VERSION "hnnbnnnynnnnnnnnnnnnnnnnnnnnnnnnnnnnnnnnnn/4/%%%/4/'%**4nnn///"

NS_ :

BS_:

BU_: BAP_Tester Fahrerdisplay_Kombi HUD ICAS1_X_Gateway ICAS3_Gateway ICC_IO_Node Kombi SmartLight_01 ZR_MIB_TOP_ab_Gen3

BO_ 2463978804 SmaLi_Control_Frame_01: 32 ICAS1_X_Gateway
	SG_ SmaLi_brightness : 72|8@1+ (1,0) [0|255] "None"  SmartLight_01
	SG_ SmaLi_Checksum : 96|16@1+ (1,0) [0|65535] "None"  SmartLight_01
	SG_ SmaLi_Cnt_05 : 8|16@1+ (1,0) [0|65535] "None"  SmartLight_01
	SG_ SmaLi_CtrlCmd_01 : 0|8@1+ (1,0) [0|255] ""  SmartLight_01
	SG_ SmaLi_Loops : 64|8@1+ (1,0) [0|255] "None"  SmartLight_01
	SG_ SmaLi_MovieBundleVersion : 80|16@1+ (1,0) [0|65535] "None"  SmartLight_01
	SG_ SmaLi_MovieID : 32|32@1+ (1,0) [0|4294967295] "None"  SmartLight_01
	SG_ SmaLi_SlotID_05 : 24|8@1+ (1,0) [0|255] "None"  SmartLight_01

BO_ 2463978800 SmaLi_Daten_Frame_01: 64 ICAS1_X_Gateway
	SG_ SmaLi_Cnt_01 : 8|16@1+ (1,0) [0|65535] "None"  SmartLight_01
	SG_ SmaLi_ColorValue_01 : 48|32@1+ (1,0) [0|4294967295] "None"  SmartLight_01
	SG_ SmaLi_ColorValue_02 : 80|32@1+ (1,0) [0|4294967295] "None"  SmartLight_01
	SG_ SmaLi_ColorValue_03 : 112|32@1+ (1,0) [0|4294967295] "None"  SmartLight_01
	SG_ SmaLi_ColorValue_04 : 144|32@1+ (1,0) [0|4294967295] "None"  SmartLight_01
	SG_ SmaLi_ColorValue_05 : 176|32@1+ (1,0) [0|4294967295] "None"  SmartLight_01
	SG_ SmaLi_ColorValue_06 : 208|32@1+ (1,0) [0|4294967295] "None"  SmartLight_01
	SG_ SmaLi_ColorValue_07 : 240|32@1+ (1,0) [0|4294967295] "None"  SmartLight_01
	SG_ SmaLi_ColorValue_08 : 272|32@1+ (1,0) [0|4294967295] "None"  SmartLight_01
	SG_ SmaLi_ColorValue_09 : 304|32@1+ (1,0) [0|4294967295] "None"  SmartLight_01
	SG_ SmaLi_ColorValue_10 : 336|32@1+ (1,0) [0|4294967295] "None"  SmartLight_01
	SG_ SmaLi_ColorValue_11 : 368|32@1+ (1,0) [0|4294967295] "None"  SmartLight_01
	SG_ SmaLi_ColorValue_12 : 400|32@1+ (1,0) [0|4294967295] "None"  SmartLight_01
	SG_ SmaLi_ColorValue_13 : 432|32@1+ (1,0) [0|4294967295] "None"  SmartLight_01
	SG_ SmaLi_ColorValue_14 : 464|32@1+ (1,0) [0|4294967295] "None"  SmartLight_01
	SG_ SmaLi_FrameCmd_01 : 0|8@1+ (1,0) [0|255] ""  SmartLight_01
	SG_ SmaLi_length : 40|8@1+ (1,0) [0|255] "None"  SmartLight_01
	SG_ SmaLi_SlotID_01 : 24|8@1+ (1,0) [0|255] "None"  SmartLight_01
	SG_ SmaLi_StartIndex : 32|8@1+ (1,0) [0|255] "None"  SmartLight_01

BO_ 2463978801 SmaLi_Daten_Frame_02: 64 ICAS1_X_Gateway
	SG_ SmaLi_Cnt_02 : 8|16@1+ (1,0) [0|65535] "None"  SmartLight_01
	SG_ SmaLi_ColorValue_15 : 32|32@1+ (1,0) [0|4294967295] "None"  SmartLight_01
	SG_ SmaLi_ColorValue_16 : 64|32@1+ (1,0) [0|4294967295] "None"  SmartLight_01
	SG_ SmaLi_ColorValue_17 : 96|32@1+ (1,0) [0|4294967295] "None"  SmartLight_01
	SG_ SmaLi_ColorValue_18 : 128|32@1+ (1,0) [0|4294967295] "None"  SmartLight_01
	SG_ SmaLi_ColorValue_19 : 160|32@1+ (1,0) [0|4294967295] "None"  SmartLight_01
	SG_ SmaLi_ColorValue_20 : 192|32@1+ (1,0) [0|4294967295] "None"  SmartLight_01
	SG_ SmaLi_ColorValue_21 : 224|32@1+ (1,0) [0|4294967295] "None"  SmartLight_01
	SG_ SmaLi_ColorValue_22 : 256|32@1+ (1,0) [0|4294967295] "None"  SmartLight_01
	SG_ SmaLi_ColorValue_23 : 288|32@1+ (1,0) [0|4294967295] "None"  SmartLight_01
	SG_ SmaLi_ColorValue_24 : 320|32@1+ (1,0) [0|4294967295] "None"  SmartLight_01
	SG_ SmaLi_ColorValue_25 : 352|32@1+ (1,0) [0|4294967295] "None"  SmartLight_01
	SG_ SmaLi_ColorValue_26 : 384|32@1+ (1,0) [0|4294967295] "None"  SmartLight_01
	SG_ SmaLi_ColorValue_27 : 416|32@1+ (1,0) [0|4294967295] "None"  SmartLight_01
	SG_ SmaLi_ColorValue_28 : 448|32@1+ (1,0) [0|4294967295] "None"  SmartLight_01
	SG_ SmaLi_ColorValue_29 : 480|32@1+ (1,0) [0|4294967295] "None"  SmartLight_01
	SG_ SmaLi_FrameCmd_02 : 0|8@1+ (1,0) [0|255] ""  SmartLight_01
	SG_ SmaLi_SlotID_02 : 24|8@1+ (1,0) [0|255] "None"  SmartLight_01

BO_ 2463978802 SmaLi_Daten_Frame_03: 64 ICAS1_X_Gateway
	SG_ SmaLi_Cnt_03 : 8|16@1+ (1,0) [0|65535] "None"  SmartLight_01
	SG_ SmaLi_ColorValue_30 : 32|32@1+ (1,0) [0|4294967295] "None"  SmartLight_01
	SG_ SmaLi_ColorValue_31 : 64|32@1+ (1,0) [0|4294967295] "None"  SmartLight_01
	SG_ SmaLi_ColorValue_32 : 96|32@1+ (1,0) [0|4294967295] "None"  SmartLight_01
	SG_ SmaLi_ColorValue_33 : 128|32@1+ (1,0) [0|4294967295] "None"  SmartLight_01
	SG_ SmaLi_ColorValue_34 : 160|32@1+ (1,0) [0|4294967295] "None"  SmartLight_01
	SG_ SmaLi_ColorValue_35 : 192|32@1+ (1,0) [0|4294967295] "None"  SmartLight_01
	SG_ SmaLi_ColorValue_36 : 224|32@1+ (1,0) [0|4294967295] "None"  SmartLight_01
	SG_ SmaLi_ColorValue_37 : 256|32@1+ (1,0) [0|4294967295] "None"  SmartLight_01
	SG_ SmaLi_ColorValue_38 : 288|32@1+ (1,0) [0|4294967295] "None"  SmartLight_01
	SG_ SmaLi_ColorValue_39 : 320|32@1+ (1,0) [0|4294967295] "None"  SmartLight_01
	SG_ SmaLi_ColorValue_40 : 352|32@1+ (1,0) [0|4294967295] "None"  SmartLight_01
	SG_ SmaLi_ColorValue_41 : 384|32@1+ (1,0) [0|4294967295] "None"  SmartLight_01
	SG_ SmaLi_ColorValue_42 : 416|32@1+ (1,0) [0|4294967295] "None"  SmartLight_01
	SG_ SmaLi_ColorValue_43 : 448|32@1+ (1,0) [0|4294967295] "None"  SmartLight_01
	SG_ SmaLi_ColorValue_44 : 480|32@1+ (1,0) [0|4294967295] "None"  SmartLight_01
	SG_ SmaLi_FrameCmd_03 : 0|8@1+ (1,0) [0|255] ""  SmartLight_01
	SG_ SmaLi_SlotID_03 : 24|8@1+ (1,0) [0|255] "None"  SmartLight_01

BO_ 2463978803 SmaLi_Daten_Frame_04: 64 ICAS1_X_Gateway
	SG_ SmaLi_Cnt_04 : 8|16@1+ (1,0) [0|65535] "None"  SmartLight_01
	SG_ SmaLi_ColorValue_45 : 32|32@1+ (1,0) [0|4294967295] "None"  SmartLight_01
	SG_ SmaLi_ColorValue_46 : 64|32@1+ (1,0) [0|4294967295] "None"  SmartLight_01
	SG_ SmaLi_ColorValue_47 : 96|32@1+ (1,0) [0|4294967295] "None"  SmartLight_01
	SG_ SmaLi_ColorValue_48 : 128|32@1+ (1,0) [0|4294967295] "None"  SmartLight_01
	SG_ SmaLi_ColorValue_49 : 160|32@1+ (1,0) [0|4294967295] "None"  SmartLight_01
	SG_ SmaLi_ColorValue_50 : 192|32@1+ (1,0) [0|4294967295] "None"  SmartLight_01
	SG_ SmaLi_ColorValue_51 : 224|32@1+ (1,0) [0|4294967295] "None"  SmartLight_01
	SG_ SmaLi_ColorValue_52 : 256|32@1+ (1,0) [0|4294967295] "None"  SmartLight_01
	SG_ SmaLi_ColorValue_53 : 288|32@1+ (1,0) [0|4294967295] "None"  SmartLight_01
	SG_ SmaLi_ColorValue_54 : 320|32@1+ (1,0) [0|4294967295] "None"  SmartLight_01
	SG_ SmaLi_ColorValue_55 : 352|32@1+ (1,0) [0|4294967295] "None"  SmartLight_01
	SG_ SmaLi_ColorValue_56 : 384|32@1+ (1,0) [0|4294967295] "None"  SmartLight_01
	SG_ SmaLi_ColorValue_57 : 416|32@1+ (1,0) [0|4294967295] "None"  SmartLight_01
	SG_ SmaLi_ColorValue_58 : 448|32@1+ (1,0) [0|4294967295] "None"  SmartLight_01
	SG_ SmaLi_ColorValue_59 : 480|32@1+ (1,0) [0|4294967295] "None"  SmartLight_01
	SG_ SmaLi_FrameCmd_04 : 0|8@1+ (1,0) [0|255] ""  SmartLight_01
	SG_ SmaLi_SlotID_04 : 24|8@1+ (1,0) [0|255] "None"  SmartLight_01

BO_ 2463978806 SmaLi_Daten_Frame_05: 64 ICAS1_X_Gateway
	SG_ SmaLi_Cnt_07 : 8|16@1+ (1,0) [0|65535] "None"  SmartLight_01
	SG_ SmaLi_ColorValue_60 : 32|32@1+ (1,0) [0|4294967295] "None"  SmartLight_01
	SG_ SmaLi_ColorValue_61 : 64|32@1+ (1,0) [0|4294967295] "None"  SmartLight_01
	SG_ SmaLi_ColorValue_62 : 96|32@1+ (1,0) [0|4294967295] "None"  SmartLight_01
	SG_ SmaLi_ColorValue_63 : 128|32@1+ (1,0) [0|4294967295] "None"  SmartLight_01
	SG_ SmaLi_ColorValue_64 : 160|32@1+ (1,0) [0|4294967295] "None"  SmartLight_01
	SG_ SmaLi_ColorValue_65 : 192|32@1+ (1,0) [0|4294967295] "None"  SmartLight_01
	SG_ SmaLi_ColorValue_66 : 224|32@1+ (1,0) [0|4294967295] "None"  SmartLight_01
	SG_ SmaLi_ColorValue_67 : 256|32@1+ (1,0) [0|4294967295] "None"  SmartLight_01
	SG_ SmaLi_ColorValue_68 : 288|32@1+ (1,0) [0|4294967295] "None"  SmartLight_01
	SG_ SmaLi_ColorValue_69 : 320|32@1+ (1,0) [0|4294967295] "None"  SmartLight_01
	SG_ SmaLi_ColorValue_70 : 352|32@1+ (1,0) [0|4294967295] "None"  SmartLight_01
	SG_ SmaLi_ColorValue_71 : 384|32@1+ (1,0) [0|4294967295] "None"  SmartLight_01
	SG_ SmaLi_ColorValue_72 : 416|32@1+ (1,0) [0|4294967295] "None"  SmartLight_01
	SG_ SmaLi_ColorValue_73 : 448|32@1+ (1,0) [0|4294967295] "None"  SmartLight_01
	SG_ SmaLi_ColorValue_74 : 480|32@1+ (1,0) [0|4294967295] "None"  SmartLight_01
	SG_ SmaLi_FrameCmd_05 : 0|8@1+ (1,0) [0|255] ""  SmartLight_01
	SG_ SmaLi_SlotID_07 : 24|8@1+ (1,0) [0|255] "None"  SmartLight_01

BO_ 2463978805 SmaLi_Response_Frame_01: 32 SmartLight_01
	SG_ SmaLi_AppSwVersion : 160|32@1+ (1,0) [0|4294967295] ""  ICAS1_X_Gateway,ICAS3_Gateway
	SG_ SmaLi_availMemory : 88|16@1+ (1,0) [0|65535] "None"  ICAS1_X_Gateway,ICAS3_Gateway
	SG_ SmaLi_Cnt_06 : 8|16@1+ (1,0) [0|65535] "None"  ICAS1_X_Gateway,ICAS3_Gateway
	SG_ SmaLi_CtrlCmdRsp_01 : 0|8@1+ (1,0) [0|255] ""  ICAS1_X_Gateway,ICAS3_Gateway
	SG_ SmaLi_error_cause : 136|8@1+ (1,0) [0|255] ""  ICAS1_X_Gateway,ICAS3_Gateway
	SG_ SmaLi_InterfaceVersion : 32|16@1+ (1,0) [0|65535] "None"  ICAS1_X_Gateway,ICAS3_Gateway
	SG_ SmaLi_MovieIDRsp : 104|32@1+ (1,0) [0|4294967295] "None"  ICAS1_X_Gateway,ICAS3_Gateway
	SG_ SmaLi_numLEDs : 48|8@1+ (1,0) [0|255] "None"  ICAS1_X_Gateway,ICAS3_Gateway
	SG_ SmaLi_numOfSlots : 80|8@1+ (1,0) [0|255] "None"  ICAS1_X_Gateway,ICAS3_Gateway
	SG_ SmaLi_SavedMovieBundleVersion : 144|16@1+ (1,0) [0|65535] "None"  ICAS1_X_Gateway,ICAS3_Gateway
	SG_ SmaLi_SlotID_06 : 24|8@1+ (1,0) [0|255] "None"  ICAS1_X_Gateway,ICAS3_Gateway
	SG_ SmaLi_xPosCenter : 64|8@1+ (1,0) [0|255] "None"  ICAS1_X_Gateway,ICAS3_Gateway
	SG_ SmaLi_xPosPassengerLeft : 56|8@1+ (1,0) [0|255] "None"  ICAS1_X_Gateway,ICAS3_Gateway
	SG_ SmaLi_xPosPassengerRight : 72|8@1+ (1,0) [0|255] "None"  ICAS1_X_Gateway,ICAS3_Gateway

BO_ 980 SMLS_01: 8 ICAS1_X_Gateway
	SG_ BH_Blinker_Fehler : 46|1@1+ (1,0) [0|1] ""  Vector__XXX
	SG_ BH_Blinker_li : 12|1@1+ (1,0) [0|1] ""  ICAS3_Gateway
	SG_ BH_Blinker_re : 13|1@1+ (1,0) [0|1] ""  ICAS3_Gateway
	SG_ BH_Fernlicht : 15|1@1+ (1,0) [0|1] ""  Vector__XXX
	SG_ BH_Lichthupe : 14|1@1+ (1,0) [0|1] ""  Vector__XXX
	SG_ FAS_Taster : 27|1@1+ (1,0) [0|1] ""  Vector__XXX
	SG_ FAS_Taster_Fehler : 28|1@1+ (1,0) [0|1] ""  Vector__XXX
	SG_ LRH_aktiv : 40|1@1+ (1,0) [0|1] ""  Vector__XXX
	SG_ LRH_On_Off : 30|2@1+ (1,0) [0|3] ""  Kombi
	SG_ LSS_Tastencode : 32|8@1+ (1,0) [0|255] ""  Vector__XXX
	SG_ SMLS_01_BZ : 8|4@1+ (1,0) [0|15] ""  Vector__XXX
	SG_ SMLS_01_CRC : 0|8@1+ (1,0) [0|255] ""  Vector__XXX
	SG_ SMLS_Hupe : 29|1@1+ (1,0) [0|1] ""  Vector__XXX
	SG_ SMLS_P_verriegelt : 41|2@1+ (1,0) [0|3] ""  Vector__XXX
	SG_ SMLS_P_verriegelt_plausibel : 43|1@1+ (1,0) [0|1] ""  Vector__XXX
	SG_ SMLS_PTT : 47|1@1+ (1,0) [0|1] ""  Vector__XXX
	SG_ WH_Frontwaschen : 20|1@1+ (1,0) [0|1] ""  Vector__XXX
	SG_ WH_Heckintervall : 21|1@1+ (1,0) [0|1] ""  Vector__XXX
	SG_ WH_Heckwaschen : 22|1@1+ (1,0) [0|1] ""  Vector__XXX
	SG_ WH_Intervall : 17|1@1+ (1,0) [0|1] ""  Vector__XXX
	SG_ WH_Intervallstufen : 23|4@1+ (1,0) [0|15] ""  Vector__XXX
	SG_ WH_SRA : 44|1@1+ (1,0) [0|1] ""  Vector__XXX
	SG_ WH_Tipwischen : 16|1@1+ (1,0) [0|1] ""  Vector__XXX
	SG_ WH_Tipwischen_lang : 48|1@1+ (1,0) [0|1] ""  Vector__XXX
	SG_ WH_Wischer_Fehler : 45|1@1+ (1,0) [0|1] ""  Vector__XXX
	SG_ WH_WischerStufe1 : 18|1@1+ (1,0) [0|1] ""  Vector__XXX
	SG_ WH_WischerStufe2 : 19|1@1+ (1,0) [0|1] ""  Vector__XXX

BO_ 2536271618 SOK_BAP_ENI4_ASG_03_Sig: 8 Vector__XXX
	SG_ SOK_BAP_ENI4_ASG_03_Sig : 0|64@1+ (1,0) [0|18446744073709551616] ""  ICAS1_X_Gateway

BO_ 2536271634 SOK_BAP_ENI4_FSG_03_Sig: 8 ICAS1_X_Gateway
	SG_ SOK_BAP_ENI4_FSG_03_Sig : 0|64@1+ (1,0) [0|18446744073709551616] ""  Vector__XXX

BO_ 2464161907 SOK_FoD_Info_El_Req_Chal_04: 8 ICAS3_Gateway
	SG_ SOK_FoD_Info_El_Req_Challenge : 0|64@1+ (1,0) [0|18446744073709551616] "None"  ICAS1_X_Gateway

BO_ 2464301171 SOK_FoD_Info_El_Resp_Chal_04: 8 ICAS1_X_Gateway
	SG_ SOK_FoD_Info_El_Resp_Challenge : 0|64@1+ (1,0) [0|18446744073709551616] "None"  ICAS3_Gateway,ICC_IO_Node,ZR_MIB_TOP_ab_Gen3

BO_ 2589283756 SOK_NoAuthenticTime_01: 8 ICAS1_X_Gateway
	SG_ SOK_ungeschuetzte_Zeit : 8|56@1+ (1,0) [1|72057594037927936] "None"  ICAS3_Gateway,ICC_IO_Node,Kombi,ZR_MIB_TOP_ab_Gen3

BO_ 2464153715 SOK_Zeit_Info_El_Chal_01: 8 ICAS3_Gateway
	SG_ SOK_Zeit_Info_El_Challenge : 0|64@1+ (1,0) [0|18446744073709551616] "None"  ICAS1_X_Gateway

BO_ 2464284787 SOK_Zeit_Info_El_Resp_01: 16 ICAS1_X_Gateway
	SG_ SOK_Zeit_Info_El_Signatur : 64|64@1- (1,0) [0|18446744073709551616] ""  ICAS3_Gateway,ICC_IO_Node,ZR_MIB_TOP_ab_Gen3
	SG_ SOK_Zeit_Info_El_Zeit : 0|56@1+ (1,0) [0|72057594037927936] "None"  ICAS3_Gateway,ICC_IO_Node,ZR_MIB_TOP_ab_Gen3

BO_ 2464153620 SOK_Zeit_Kombi_Chal_01: 8 Kombi
	SG_ SOK_Zeit_Kombi_Challenge : 0|64@1+ (1,0) [0|18446744073709551616] "None"  ICAS1_X_Gateway

BO_ 2464284692 SOK_Zeit_Kombi_Signatur_Resp_01: 8 ICAS1_X_Gateway
	SG_ SOK_Zeit_Kombi_Signatur : 0|64@1+ (1,0) [0|18446744073709551616] ""  Kombi

BO_ 2464288788 SOK_Zeit_Kombi_Zeit_Resp_01: 8 ICAS1_X_Gateway
	SG_ SOK_Zeit_Kombi_Zeit : 0|56@1+ (1,0) [0|72057594037927936] "None"  Kombi

BO_ 2527679739 Standklima_01: 8 ICAS1_X_Gateway
	SG_ STK_Anf_AussenspiegelHZ : 34|1@1+ (1,0) [0|1] ""  Vector__XXX
	SG_ STK_Berechnungsphase : 30|2@1+ (1,0) [0|3] ""  Vector__XXX
	SG_ STK_Betriebsdauer : 5|7@1+ (1,0) [0|120] "Minut"  Vector__XXX
	SG_ STK_ErwVK_Anf : 25|1@1+ (1,0) [0|1] ""  Vector__XXX
	SG_ STK_ErwVK_Beifahrerzone : 35|1@1+ (1,0) [0|1] ""  Vector__XXX
	SG_ STK_ErwVK_Fahrerzone : 36|1@1+ (1,0) [0|1] ""  Vector__XXX
	SG_ STK_ErwVK_Heckzone2_links : 62|1@1+ (1,0) [0|1] ""  Vector__XXX
	SG_ STK_ErwVK_Heckzone2_rechts : 63|1@1+ (1,0) [0|1] ""  Vector__XXX
	SG_ STK_ErwVK_Heckzone_links : 37|1@1+ (1,0) [0|1] ""  Vector__XXX
	SG_ STK_ErwVK_Heckzone_rechts : 38|1@1+ (1,0) [0|1] ""  Vector__XXX
	SG_ STK_ErwVK_Modus : 26|4@1+ (1,0) [0|15] ""  Vector__XXX
	SG_ STK_ErwVK_Scheibenheizung : 39|1@1+ (1,0) [0|1] ""  Vector__XXX
	SG_ STK_FSH_Anf : 12|1@1+ (1,0) [0|1] ""  Vector__XXX
	SG_ STK_GesamtEnergiebedarf : 52|8@1+ (0.1,0) [0|15] "KiloWattHour"  Vector__XXX
	SG_ STK_HSH_Anf : 13|1@1+ (1,0) [0|1] ""  Vector__XXX
	SG_ STK_Klima_Temp : 14|5@1+ (0.5,15.5) [15.5|29.5] "DegreCelsi"  Vector__XXX
	SG_ STK_KurzVK_Anf : 19|1@1+ (1,0) [0|1] ""  Vector__XXX
	SG_ STK_MaxLeistung : 44|8@1+ (0.1,0) [0|15] "KiloWatt"  Vector__XXX
	SG_ STK_Standklima_Anf : 20|1@1+ (1,0) [0|1] ""  Vector__XXX
	SG_ STK_Standklima_Timer_Status : 21|1@1+ (1,0) [0|1] ""  Vector__XXX
	SG_ STK_Stecker_Status : 60|2@1+ (1,0) [0|3] ""  Vector__XXX
	SG_ STK_VK_Modus : 23|2@1+ (1,0) [0|3] ""  Vector__XXX
	SG_ STK_VK_STH_Einsatz : 40|3@1+ (1,0) [0|7] ""  Vector__XXX
	SG_ STK_VK_Timer_Status : 32|2@1+ (1,0) [0|3] ""  Vector__XXX
	SG_ STK_Voko_LED : 43|1@1+ (1,0) [0|1] ""  Fahrerdisplay_Kombi

BO_ 1413 Systeminfo_01: 8 ICAS1_X_Gateway
	SG_ GW_KD_Fehler : 13|1@1+ (1,0) [0|1] ""  ICAS3_Gateway,ICC_IO_Node,ZR_MIB_TOP_ab_Gen3
	SG_ SI_BUS_01 : 16|1@1+ (1,0) [0|1] ""  ICAS3_Gateway,ICC_IO_Node,Kombi,ZR_MIB_TOP_ab_Gen3
	SG_ SI_BUS_02 : 17|1@1+ (1,0) [0|1] ""  Fahrerdisplay_Kombi,ICAS3_Gateway,ICC_IO_Node,Kombi,ZR_MIB_TOP_ab_Gen3
	SG_ SI_BUS_03 : 18|1@1+ (1,0) [0|1] ""  ICAS3_Gateway,ICC_IO_Node,Kombi,ZR_MIB_TOP_ab_Gen3
	SG_ SI_BUS_04 : 19|1@1+ (1,0) [0|1] ""  ICAS3_Gateway,ICC_IO_Node,Kombi,ZR_MIB_TOP_ab_Gen3
	SG_ SI_BUS_05 : 20|1@1+ (1,0) [0|1] ""  ICAS3_Gateway,ICC_IO_Node,Kombi,ZR_MIB_TOP_ab_Gen3
	SG_ SI_BUS_06 : 21|1@1+ (1,0) [0|1] ""  ICAS3_Gateway,ICC_IO_Node,Kombi,ZR_MIB_TOP_ab_Gen3
	SG_ SI_BUS_07 : 22|1@1+ (1,0) [0|1] ""  ICAS3_Gateway,ICC_IO_Node,ZR_MIB_TOP_ab_Gen3
	SG_ SI_BUS_08 : 23|1@1+ (1,0) [0|1] ""  ICAS3_Gateway,ICC_IO_Node,ZR_MIB_TOP_ab_Gen3
	SG_ SI_BUS_09 : 24|1@1+ (1,0) [0|1] ""  ICAS3_Gateway,ICC_IO_Node,ZR_MIB_TOP_ab_Gen3
	SG_ SI_BUS_10 : 25|1@1+ (1,0) [0|1] ""  ICAS3_Gateway,ICC_IO_Node,ZR_MIB_TOP_ab_Gen3
	SG_ SI_BUS_11 : 26|1@1+ (1,0) [0|1] ""  ICAS3_Gateway,ICC_IO_Node,ZR_MIB_TOP_ab_Gen3
	SG_ SI_BUS_12 : 27|1@1+ (1,0) [0|1] ""  ICAS3_Gateway,ICC_IO_Node,ZR_MIB_TOP_ab_Gen3
	SG_ SI_BUS_13 : 28|1@1+ (1,0) [0|1] ""  ICAS3_Gateway,ICC_IO_Node,Kombi,ZR_MIB_TOP_ab_Gen3
	SG_ SI_BUS_14 : 29|1@1+ (1,0) [0|1] ""  ICAS3_Gateway,ICC_IO_Node,Kombi,ZR_MIB_TOP_ab_Gen3
	SG_ SI_BUS_15 : 30|1@1+ (1,0) [0|1] ""  ICAS3_Gateway,ICC_IO_Node,Kombi,ZR_MIB_TOP_ab_Gen3
	SG_ SI_Bus_Identifikation : 32|8@1+ (1,0) [0|255] ""  ICAS3_Gateway,ICC_IO_Node,Kombi,ZR_MIB_TOP_ab_Gen3
	SG_ SI_CAB_V15 : 40|24@1+ (1,0) [0|16777215] ""  ICAS3_Gateway,ICC_IO_Node,ZR_MIB_TOP_ab_Gen3
	SG_ SI_Diagnose_Aktiv : 7|1@1+ (1,0) [0|1] ""  ICAS3_Gateway,ICC_IO_Node,ZR_MIB_TOP_ab_Gen3
	SG_ SI_NWDF : 10|1@1+ (1,0) [0|1] ""  Fahrerdisplay_Kombi,HUD,ICAS3_Gateway,ICC_IO_Node,Kombi,SmartLight_01,ZR_MIB_TOP_ab_Gen3
	SG_ SI_NWDF_gueltig : 11|1@1+ (1,0) [0|1] ""  Fahrerdisplay_Kombi,HUD,ICAS3_Gateway,ICC_IO_Node,Kombi,SmartLight_01,ZR_MIB_TOP_ab_Gen3
	SG_ SI_P_Mode : 15|1@1+ (1,0) [0|1] ""  Fahrerdisplay_Kombi,HUD,ICAS3_Gateway,ICC_IO_Node,Kombi,SmartLight_01,ZR_MIB_TOP_ab_Gen3
	SG_ SI_P_Mode_gueltig : 6|1@1+ (1,0) [0|1] ""  Fahrerdisplay_Kombi,HUD,ICAS3_Gateway,ICC_IO_Node,Kombi,SmartLight_01,ZR_MIB_TOP_ab_Gen3
	SG_ SI_QRS_Mode : 8|1@1+ (1,0) [0|1] ""  Fahrerdisplay_Kombi,HUD,ICAS3_Gateway,ICC_IO_Node,Kombi,SmartLight_01,ZR_MIB_TOP_ab_Gen3
	SG_ SI_Sammel_SG_Fehler : 0|6@1+ (1,0) [0|60] ""  ICAS3_Gateway,ICC_IO_Node,ZR_MIB_TOP_ab_Gen3
	SG_ SI_Sammelfehler : 12|1@1+ (1,0) [0|1] ""  ICAS3_Gateway,ICC_IO_Node,ZR_MIB_TOP_ab_Gen3
	SG_ SI_T_Mode : 9|1@1+ (1,0) [0|1] ""  Fahrerdisplay_Kombi,HUD,ICAS3_Gateway,ICC_IO_Node,Kombi,SmartLight_01,ZR_MIB_TOP_ab_Gen3
	SG_ SI_T_Schutz : 14|1@1+ (1,0) [0|1] ""  ICAS3_Gateway,ICC_IO_Node,Kombi,SmartLight_01,ZR_MIB_TOP_ab_Gen3

BO_ 2589283775 SystemState_01: 8 ICAS1_X_Gateway
	SG_ NM_aktiv_Buskopplung : 25|1@1+ (1,0) [0|1] ""  Vector__XXX
	SG_ NM_aktiv_CAB : 26|1@1+ (1,0) [0|1] ""  Vector__XXX
	SG_ NM_aktiv_CWU : 24|1@1+ (1,0) [0|1] ""  Vector__XXX
	SG_ NM_Req_CMS : 13|1@1+ (1,0) [0|1] ""  Vector__XXX
	SG_ NM_Req_DCP_01 : 14|1@1+ (1,0) [0|1] ""  Vector__XXX
	SG_ NM_Req_DCP_02 : 18|1@1+ (1,0) [0|1] ""  Vector__XXX
	SG_ NM_Req_DIM : 15|1@1+ (1,0) [0|1] ""  Vector__XXX
	SG_ NM_Req_ECM : 12|1@1+ (1,0) [0|1] ""  Vector__XXX
	SG_ NM_Req_EMHLR : 10|1@1+ (1,0) [0|1] ""  Vector__XXX
	SG_ NM_Req_EOC : 22|1@1+ (1,0) [0|1] ""  Vector__XXX
	SG_ NM_Req_FoD : 9|1@1+ (1,0) [0|1] ""  Vector__XXX
	SG_ NM_Req_HVEM : 11|1@1+ (1,0) [0|1] ""  Vector__XXX
	SG_ NM_Req_IAA_PSO : 2|1@1+ (1,0) [0|1] ""  Vector__XXX
	SG_ NM_Req_internal : 21|1@1+ (1,0) [0|1] ""  Vector__XXX
	SG_ NM_Req_Kessy : 0|1@1+ (1,0) [0|1] ""  Vector__XXX
	SG_ NM_Req_KLS : 17|1@1+ (1,0) [0|1] ""  Vector__XXX
	SG_ NM_Req_KS : 3|1@1+ (1,0) [0|1] ""  Vector__XXX
	SG_ NM_Req_PaCo : 4|1@1+ (1,0) [0|1] ""  Vector__XXX
	SG_ NM_Req_RTM : 7|1@1+ (1,0) [0|1] ""  Vector__XXX
	SG_ NM_Req_SAL : 16|1@1+ (1,0) [0|1] ""  Vector__XXX
	SG_ NM_Req_STK : 5|1@1+ (1,0) [0|1] ""  Vector__XXX
	SG_ NM_Req_SWC1 : 19|1@1+ (1,0) [0|1] ""  Vector__XXX
	SG_ NM_Req_SWC2 : 20|1@1+ (1,0) [0|1] ""  Vector__XXX
	SG_ NM_Req_USS : 1|1@1+ (1,0) [0|1] ""  Vector__XXX
	SG_ NM_Req_ZM : 8|1@1+ (1,0) [0|1] ""  Vector__XXX
	SG_ NM_Req_ZV : 6|1@1+ (1,0) [0|1] ""  Vector__XXX
	SG_ Powerstate_Act : 32|5@1+ (1,0) [0|31] ""  Vector__XXX
	SG_ Powerstate_Time : 48|16@1+ (1,0) [0|65535] "Minut"  Vector__XXX

BO_ 2589283947 SystemState_02: 16 ICAS1_X_Gateway
	SG_ NM_Reason_CMS : 52|4@1+ (1,0) [0|15] ""  Vector__XXX
	SG_ NM_Reason_DCP_1 : 56|4@1+ (1,0) [0|15] ""  Vector__XXX
	SG_ NM_Reason_DCP_2 : 60|4@1+ (1,0) [0|15] ""  Vector__XXX
	SG_ NM_Reason_DIM : 64|4@1+ (1,0) [0|15] ""  Vector__XXX
	SG_ NM_Reason_ECM : 48|4@1+ (1,0) [0|15] ""  Vector__XXX
	SG_ NM_Reason_EMHLR : 40|4@1+ (1,0) [0|15] ""  Vector__XXX
	SG_ NM_Reason_EOC : 88|4@1+ (1,0) [0|15] ""  Vector__XXX
	SG_ NM_Reason_FoD : 36|4@1+ (1,0) [0|15] ""  Vector__XXX
	SG_ NM_Reason_HVEM : 44|4@1+ (1,0) [0|15] ""  Vector__XXX
	SG_ NM_Reason_IAA_PSO : 8|4@1+ (1,0) [0|15] ""  Vector__XXX
	SG_ NM_Reason_ICAS1_internal : 84|4@1+ (1,0) [0|15] ""  Vector__XXX
	SG_ NM_Reason_Kessy : 0|4@1+ (1,0) [0|15] ""  Vector__XXX
	SG_ NM_Reason_KLS : 72|4@1+ (1,0) [0|15] ""  Vector__XXX
	SG_ NM_Reason_KS : 12|4@1+ (1,0) [0|15] ""  Vector__XXX
	SG_ NM_Reason_PaCo : 16|4@1+ (1,0) [0|15] ""  Vector__XXX
	SG_ NM_Reason_RTM : 28|4@1+ (1,0) [0|15] ""  Vector__XXX
	SG_ NM_Reason_SAL : 68|4@1+ (1,0) [0|15] ""  Vector__XXX
	SG_ NM_Reason_STK : 20|4@1+ (1,0) [0|15] ""  Vector__XXX
	SG_ NM_Reason_SWC1 : 76|4@1+ (1,0) [0|15] ""  Vector__XXX
	SG_ NM_Reason_SWC2 : 80|4@1+ (1,0) [0|15] ""  Vector__XXX
	SG_ NM_Reason_USS : 4|4@1+ (1,0) [0|15] ""  Vector__XXX
	SG_ NM_Reason_ZM : 32|4@1+ (1,0) [0|15] ""  Vector__XXX
	SG_ NM_Reason_ZV : 24|4@1+ (1,0) [0|15] ""  Vector__XXX
	SG_ Powerstate_Prev_01 : 104|5@1+ (1,0) [0|31] ""  Vector__XXX
	SG_ Powerstate_Prev_02 : 109|5@1+ (1,0) [0|31] ""  Vector__XXX

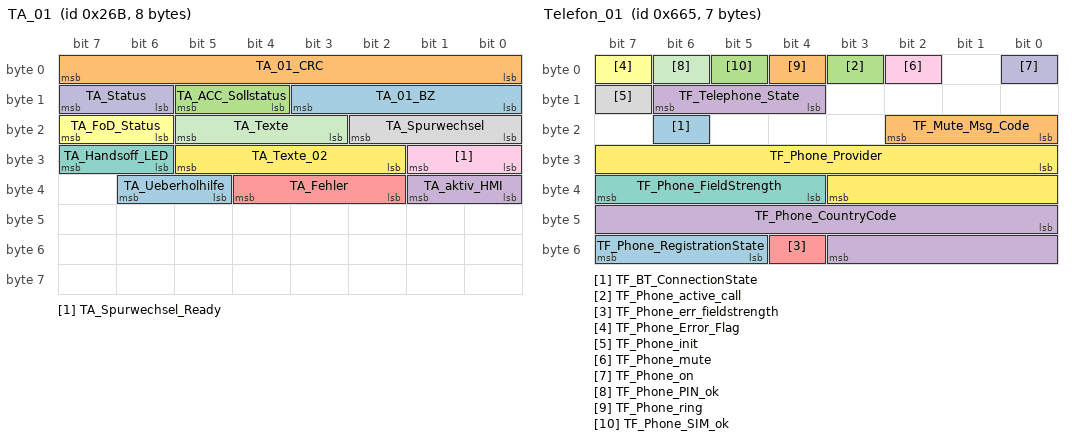
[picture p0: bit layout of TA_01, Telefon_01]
BO_ 619 TA_01: 8 ICAS1_X_Gateway
	SG_ TA_01_BZ : 8|4@1+ (1,0) [0|15] ""  Vector__XXX
	SG_ TA_01_CRC : 0|8@1+ (1,0) [0|255] ""  Vector__XXX
	SG_ TA_ACC_Sollstatus : 12|2@1+ (1,0) [0|3] ""  Vector__XXX
	SG_ TA_aktiv_HMI : 32|2@1+ (1,0) [0|3] ""  ICAS3_Gateway
	SG_ TA_Fehler : 34|3@1+ (1,0) [0|7] ""  ICAS3_Gateway
	SG_ TA_FoD_Status : 22|2@1+ (1,0) [0|3] ""  ICAS3_Gateway
	SG_ TA_Handsoff_LED : 30|2@1+ (1,0) [0|3] ""  ICAS3_Gateway
	SG_ TA_Spurwechsel : 16|3@1+ (1,0) [0|7] ""  Kombi
	SG_ TA_Spurwechsel_Ready : 24|2@1+ (1,0) [0|3] ""  Vector__XXX
	SG_ TA_Status : 14|2@1+ (1,0) [0|3] ""  Kombi
	SG_ TA_Texte : 19|3@1+ (1,0) [0|7] ""  Kombi
	SG_ TA_Texte_02 : 26|4@1+ (1,0) [0|15] ""  Kombi
	SG_ TA_Ueberholhilfe : 37|2@1+ (1,0) [0|3] ""  Vector__XXX

BO_ 1637 Telefon_01: 7 ICAS3_Gateway
	SG_ TF_BT_ConnectionState : 22|1@1+ (1,0) [0|1] ""  Vector__XXX
	SG_ TF_Mute_Msg_Code : 16|3@1+ (1,0) [0|7] ""  Vector__XXX
	SG_ TF_Phone_active_call : 3|1@1+ (1,0) [0|1] ""  Vector__XXX
	SG_ TF_Phone_CountryCode : 40|12@1+ (1,0) [0|4095] ""  Vector__XXX
	SG_ TF_Phone_err_fieldstrength : 52|1@1+ (1,0) [0|1] ""  Vector__XXX
	SG_ TF_Phone_Error_Flag : 7|1@1+ (1,0) [0|1] ""  Vector__XXX
	SG_ TF_Phone_FieldStrength : 36|4@1+ (1,0) [0|15] ""  Vector__XXX
	SG_ TF_Phone_init : 15|1@1+ (1,0) [0|1] ""  Vector__XXX
	SG_ TF_Phone_mute : 2|1@1+ (1,0) [0|1] ""  Vector__XXX
	SG_ TF_Phone_on : 0|1@1+ (1,0) [0|1] ""  Vector__XXX
	SG_ TF_Phone_PIN_ok : 6|1@1+ (1,0) [0|1] ""  Vector__XXX
	SG_ TF_Phone_Provider : 24|12@1+ (1,0) [0|4095] ""  Vector__XXX
	SG_ TF_Phone_RegistrationState : 53|3@1+ (1,0) [0|7] ""  Vector__XXX
	SG_ TF_Phone_ring : 4|1@1+ (1,0) [0|1] ""  Vector__XXX
	SG_ TF_Phone_SIM_ok : 5|1@1+ (1,0) [0|1] ""  Vector__XXX
	SG_ TF_Telephone_State : 12|3@1+ (1,0) [0|7] ""  ICAS1_X_Gateway

BO_ 2589283750 Temperaturen_01: 8 ICAS1_X_Gateway
	SG_ KBI_Aussen_Temp_gef : 16|8@1+ (0.5,-50) [-50|75] "DegreCelsi"  SmartLight_01,ZR_MIB_TOP_ab_Gen3
	SG_ KBI_QBit_Aussen_Temp_gef : 12|1@1+ (1,0) [0|1] ""  SmartLight_01,ZR_MIB_TOP_ab_Gen3

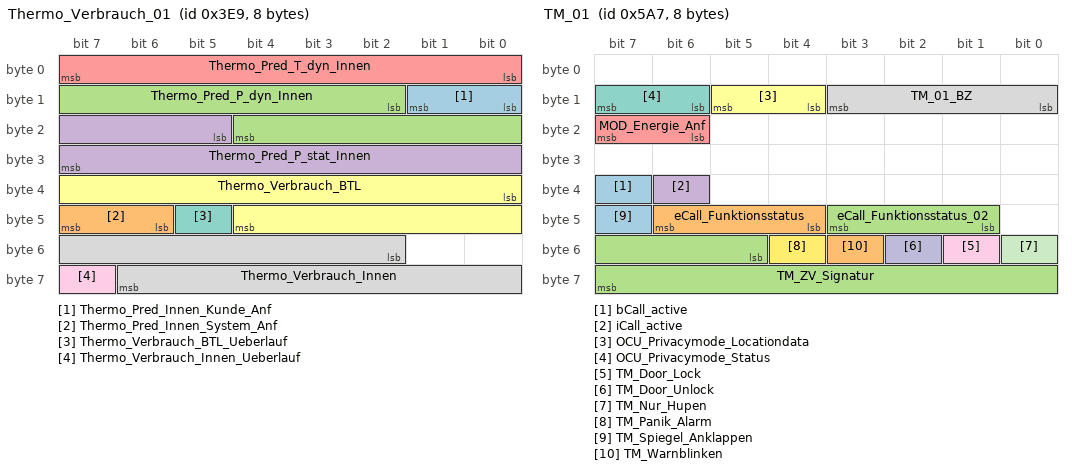
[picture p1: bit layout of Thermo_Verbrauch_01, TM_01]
BO_ 1001 Thermo_Verbrauch_01: 8 ICAS1_X_Gateway
	SG_ Thermo_Pred_Innen_Kunde_Anf : 8|2@1+ (1,0) [0|3] "None"  Vector__XXX
	SG_ Thermo_Pred_Innen_System_Anf : 46|2@1+ (1,0) [0|3] "None"  Vector__XXX
	SG_ Thermo_Pred_P_dyn_Innen : 10|11@1+ (10,0) [0|20450] "Watt"  Vector__XXX
	SG_ Thermo_Pred_P_stat_Innen : 21|11@1+ (10,0) [0|20450] "Watt"  Vector__XXX
	SG_ Thermo_Pred_T_dyn_Innen : 0|8@1+ (1,0) [0|253] "Minut"  Vector__XXX
	SG_ Thermo_Verbrauch_BTL : 32|13@1+ (1,0) [0|8191] "WattSecond"  Kombi
	SG_ Thermo_Verbrauch_BTL_Ueberlauf : 45|1@1+ (1,0) [0|1] ""  Kombi
	SG_ Thermo_Verbrauch_Innen : 50|13@1+ (1,0) [0|8191] "WattSecond"  Kombi
	SG_ Thermo_Verbrauch_Innen_Ueberlauf : 63|1@1+ (1,0) [0|1] ""  Kombi

BO_ 1447 TM_01: 8 ICAS1_X_Gateway
	SG_ bCall_active : 39|1@1+ (1,0) [0|1] ""  Vector__XXX
	SG_ eCall_Funktionsstatus : 44|3@1+ (1,0) [0|7] ""  Kombi
	SG_ eCall_Funktionsstatus_02 : 41|3@1+ (1,0) [0|7] ""  Kombi
	SG_ iCall_active : 38|1@1+ (1,0) [0|1] ""  Vector__XXX
	SG_ MOD_Energie_Anf : 22|2@1+ (1,0) [0|3] ""  Vector__XXX
	SG_ OCU_Privacymode_Locationdata : 12|2@1+ (1,0) [0|3] ""  Vector__XXX
	SG_ OCU_Privacymode_Status : 14|2@1+ (1,0) [0|3] ""  Vector__XXX
	SG_ TM_01_BZ : 8|4@1+ (1,0) [0|15] ""  Vector__XXX
	SG_ TM_Door_Lock : 49|1@1+ (1,0) [0|1] ""  Vector__XXX
	SG_ TM_Door_Unlock : 50|1@1+ (1,0) [0|1] ""  Vector__XXX
	SG_ TM_Nur_Hupen : 48|1@1+ (1,0) [0|1] ""  Vector__XXX
	SG_ TM_Panik_Alarm : 52|1@1+ (1,0) [0|1] ""  Vector__XXX
	SG_ TM_Spiegel_Anklappen : 47|1@1+ (1,0) [0|1] ""  Vector__XXX
	SG_ TM_Warnblinken : 51|1@1+ (1,0) [0|1] ""  Vector__XXX
	SG_ TM_ZV_Signatur : 53|11@1+ (1,0) [1|2047] "None"  Vector__XXX

BO_ 977 TSG_BT_01: 8 ICAS1_X_Gateway
	SG_ ASW_Warnung_aktiv_BFS : 56|1@1+ (1,0) [0|1] ""  Vector__XXX
	SG_ BFS_Status_eTAG : 49|2@1+ (1,0) [0|3] ""  Vector__XXX
	SG_ BT_ASW_HMI_defekt : 63|1@1+ (1,0) [0|1] ""  Vector__XXX
	SG_ BT_EC_Spiegel_Helligkeit : 10|5@1+ (3.125,0) [0|96.875] "PerCent"  Vector__XXX
	SG_ BT_FH_Bew_hoch : 32|1@1+ (1,0) [0|1] ""  Vector__XXX
	SG_ BT_FH_Bew_tief : 33|1@1+ (1,0) [0|1] ""  Vector__XXX
	SG_ BT_FH_Block : 35|1@1+ (1,0) [0|1] ""  Vector__XXX
	SG_ BT_FH_Fang : 34|1@1+ (1,0) [0|1] ""  Vector__XXX
	SG_ BT_FH_normiert : 39|1@1+ (1,0) [0|1] ""  Vector__XXX
	SG_ BT_FH_Oeffnung : 24|8@1+ (0.5,0) [0|100] "PerCent"  Vector__XXX
	SG_ BT_FH_Pos_oben : 57|1@1+ (1,0) [0|1] ""  Vector__XXX
	SG_ BT_FH_S_AutoHoch : 21|1@1+ (1,0) [0|1] ""  Vector__XXX
	SG_ BT_FH_S_AutoTief : 23|1@1+ (1,0) [0|1] ""  Vector__XXX
	SG_ BT_FH_S_ManHoch : 20|1@1+ (1,0) [0|1] ""  Vector__XXX
	SG_ BT_FH_S_ManTief : 22|1@1+ (1,0) [0|1] ""  Vector__XXX
	SG_ BT_FH_Thermo : 36|1@1+ (1,0) [0|1] ""  Vector__XXX
	SG_ BT_gesafet : 2|1@1+ (1,0) [0|1] ""  Vector__XXX
	SG_ BT_Kisi_Fehler : 38|1@1+ (1,0) [0|1] ""  Vector__XXX
	SG_ BT_Lock_Taster : 6|1@1+ (1,0) [0|1] ""  Vector__XXX
	SG_ BT_Lock_Taster_inv : 60|1@1+ (1,0) [0|1] ""  Vector__XXX
	SG_ BT_Lock_Unlock_Taster : 52|1@1+ (1,0) [0|1] ""  Vector__XXX
	SG_ BT_Oben_Block_erw : 46|1@1+ (1,0) [0|1] ""  Vector__XXX
	SG_ BT_Schliesstaster : 40|1@1+ (1,0) [0|1] ""  Vector__XXX
	SG_ BT_Schluesselschalter_auf : 3|1@1+ (1,0) [0|1] ""  Vector__XXX
	SG_ BT_Schluesselschalter_zu : 4|1@1+ (1,0) [0|1] ""  Vector__XXX
	SG_ BT_Schluesselschalter_zu_inv : 61|1@1+ (1,0) [0|1] ""  Vector__XXX
	SG_ BT_SP_ausgerastet : 42|1@1+ (1,0) [0|1] ""  Vector__XXX
	SG_ BT_Sp_Blk_def : 19|1@1+ (1,0) [0|1] ""  Vector__XXX
	SG_ BT_SP_Heizung_aktiv : 45|1@1+ (1,0) [0|1] ""  Vector__XXX
	SG_ BT_Sp_Heizung_Anf : 15|1@1+ (100,0) [0|100] "PerCent"  Vector__XXX
	SG_ BT_SP_Heizung_Status : 55|1@1+ (1,0) [0|1] ""  Vector__XXX
	SG_ BT_SP_ht_aktiv : 44|1@1+ (1,0) [0|1] ""  Vector__XXX
	SG_ BT_SP_lr_aktiv : 43|1@1+ (1,0) [0|1] ""  Vector__XXX
	SG_ BT_Sperrklinke : 7|1@1+ (1,0) [0|1] ""  Vector__XXX
	SG_ BT_SWA_HMI_defekt : 62|1@1+ (1,0) [0|1] ""  Vector__XXX
	SG_ BT_TAG_betaetigt : 8|1@1+ (1,0) [0|1] ""  Vector__XXX
	SG_ BT_TCR_Mode_aktiv : 51|1@1+ (1,0) [0|1] ""  Vector__XXX
	SG_ BT_TIG_betaetigt : 9|1@1+ (1,0) [0|1] ""  Vector__XXX
	SG_ BT_TSG_hinten_verbaut : 18|1@1+ (1,0) [0|1] ""  Vector__XXX
	SG_ BT_Tuer_geoeffnet : 0|1@1+ (1,0) [0|1] ""  ICAS3_Gateway,ZR_MIB_TOP_ab_Gen3
	SG_ BT_Tuer_Status : 16|2@1+ (1,0) [0|3] ""  Vector__XXX
	SG_ BT_Tuer_Status_QBit : 48|1@1+ (1,0) [0|1] ""  Vector__XXX
	SG_ BT_Tueroeffnen_Warnung : 59|1@1+ (1,0) [0|1] ""  Vector__XXX
	SG_ BT_Tuerschloss_defekt : 58|1@1+ (1,0) [0|1] ""  Kombi
	SG_ BT_UEKB_aktiviert : 37|1@1+ (1,0) [0|1] ""  Vector__XXX
	SG_ BT_Unlock_Taster : 5|1@1+ (1,0) [0|1] ""  Vector__XXX
	SG_ BT_Unten_Block_erw : 47|1@1+ (1,0) [0|1] ""  Vector__XXX
	SG_ BT_verriegelt : 1|1@1+ (1,0) [0|1] ""  Vector__XXX
	SG_ BT_Zuziehhilfe_aktiv : 41|1@1+ (1,0) [0|1] ""  Vector__XXX

BO_ 976 TSG_FT_01: 8 ICAS1_X_Gateway
	SG_ ASW_HMI_defekt : 38|1@1+ (1,0) [0|1] ""  Vector__XXX
	SG_ ASW_wakeup : 45|1@1+ (1,0) [0|1] ""  Vector__XXX
	SG_ ASW_Warnung_aktiv_FS : 56|1@1+ (1,0) [0|1] ""  Vector__XXX
	SG_ FS_Status_eTAG : 62|2@1+ (1,0) [0|3] ""  Vector__XXX
	SG_ FT_BFS_Fond_Freigabe : 52|1@1+ (1,0) [0|1] ""  Vector__XXX
	SG_ FT_Daemmglas : 54|1@1+ (1,0) [0|1] ""  Vector__XXX
	SG_ FT_FH_Bew_hoch : 32|1@1+ (1,0) [0|1] ""  Vector__XXX
	SG_ FT_FH_Bew_tief : 33|1@1+ (1,0) [0|1] ""  Vector__XXX
	SG_ FT_FH_Block : 35|1@1+ (1,0) [0|1] ""  Vector__XXX
	SG_ FT_FH_Fang : 34|1@1+ (1,0) [0|1] ""  Vector__XXX
	SG_ FT_FH_normiert : 39|1@1+ (1,0) [0|1] ""  Vector__XXX
	SG_ FT_FH_Oeffnung : 24|8@1+ (0.5,0) [0|100] "PerCent"  Vector__XXX
	SG_ FT_FH_Pos_oben : 57|1@1+ (1,0) [0|1] ""  Vector__XXX
	SG_ FT_FH_S_AutoHoch : 21|1@1+ (1,0) [0|1] ""  Vector__XXX
	SG_ FT_FH_S_AutoTief : 23|1@1+ (1,0) [0|1] ""  Vector__XXX
	SG_ FT_FH_S_ManHoch : 20|1@1+ (1,0) [0|1] ""  Vector__XXX
	SG_ FT_FH_S_ManTief : 22|1@1+ (1,0) [0|1] ""  Vector__XXX
	SG_ FT_FH_Thermo : 36|1@1+ (1,0) [0|1] ""  Vector__XXX
	SG_ FT_gesafet : 2|1@1+ (1,0) [0|1] ""  Vector__XXX
	SG_ FT_HD_Taste : 11|1@1+ (1,0) [0|1] ""  Vector__XXX
	SG_ FT_HD_Taste_2 : 16|1@1+ (1,0) [0|1] ""  Vector__XXX
	SG_ FT_IRUE_Taste : 10|1@1+ (1,0) [0|1] ""  Vector__XXX
	SG_ FT_Kisi_Fehler : 53|1@1+ (1,0) [0|1] ""  Kombi
	SG_ FT_Kisi_li_aktiv : 48|1@1+ (1,0) [0|1] ""  ZR_MIB_TOP_ab_Gen3
	SG_ FT_Kisi_re_aktiv : 49|1@1+ (1,0) [0|1] ""  ZR_MIB_TOP_ab_Gen3
	SG_ FT_Kisi_Taster_li : 50|1@1+ (1,0) [0|1] ""  Vector__XXX
	SG_ FT_Kisi_Taster_re : 51|1@1+ (1,0) [0|1] ""  Vector__XXX
	SG_ FT_Lock_Taster : 6|1@1+ (1,0) [0|1] ""  Vector__XXX
	SG_ FT_Lock_Unlock_Taster : 17|1@1+ (1,0) [0|1] ""  Vector__XXX
	SG_ FT_Oben_Block_erw : 46|1@1+ (1,0) [0|1] ""  Vector__XXX
	SG_ FT_Schliesstaster : 40|1@1+ (1,0) [0|1] ""  Vector__XXX
	SG_ FT_Schluesselschalter_auf : 3|1@1+ (1,0) [0|1] ""  Vector__XXX
	SG_ FT_Schluesselschalter_zu : 4|1@1+ (1,0) [0|1] ""  Vector__XXX
	SG_ FT_SP_ausgerastet : 42|1@1+ (1,0) [0|1] ""  Vector__XXX
	SG_ FT_Sp_Blk_def : 19|1@1+ (1,0) [0|1] ""  Vector__XXX
	SG_ FT_Sp_Heizung_Anf : 15|1@1+ (100,0) [0|100] "PerCent"  Vector__XXX
	SG_ FT_SP_Heizung_Status : 55|1@1+ (1,0) [0|1] ""  Vector__XXX
	SG_ FT_SP_ht_aktiv : 44|1@1+ (1,0) [0|1] ""  Vector__XXX
	SG_ FT_SP_lr_aktiv : 43|1@1+ (1,0) [0|1] ""  Vector__XXX
	SG_ FT_Sperrklinke : 7|1@1+ (1,0) [0|1] ""  Vector__XXX
	SG_ FT_SWA_Taster : 59|1@1+ (1,0) [0|1] ""  Vector__XXX
	SG_ FT_TAG_betaetigt : 8|1@1+ (1,0) [0|1] ""  Vector__XXX
	SG_ FT_TD_Taste : 13|1@1+ (1,0) [0|1] ""  Vector__XXX
	SG_ FT_TD_Taste_Fehler : 12|1@1+ (1,0) [0|1] ""  Vector__XXX
	SG_ FT_TIG_betaetigt : 9|1@1+ (1,0) [0|1] ""  Vector__XXX
	SG_ FT_TSG_hinten_verbaut : 18|1@1+ (1,0) [0|1] ""  Vector__XXX
	SG_ FT_Tuer_geoeffnet : 0|1@1+ (1,0) [0|1] ""  ICAS3_Gateway,ZR_MIB_TOP_ab_Gen3
	SG_ FT_Tuerschloss_defekt : 58|1@1+ (1,0) [0|1] ""  Kombi
	SG_ FT_UEKB_aktiviert : 37|1@1+ (1,0) [0|1] ""  Vector__XXX
	SG_ FT_Unlock_Taster : 5|1@1+ (1,0) [0|1] ""  Vector__XXX
	SG_ FT_Unten_Block_erw : 47|1@1+ (1,0) [0|1] ""  Vector__XXX
	SG_ FT_verriegelt : 1|1@1+ (1,0) [0|1] ""  Vector__XXX
	SG_ FT_Zuziehhilfe_aktiv : 41|1@1+ (1,0) [0|1] ""  Vector__XXX
	SG_ SSR_Temp_Freigabe : 14|1@1+ (1,0) [0|1] ""  Vector__XXX
	SG_ SWA_HMI_Diagnose : 60|2@1+ (1,0) [0|3] ""  Vector__XXX

BO_ 997 TSG_FT_02: 8 ICAS1_X_Gateway
	SG_ FT_BFS_Tuer_Status : 17|2@1+ (1,0) [0|3] ""  Vector__XXX
	SG_ FT_Cargolock_bet : 38|1@1+ (1,0) [0|1] ""  Vector__XXX
	SG_ FT_HBFS_Tuer_Status : 19|2@1+ (1,0) [0|3] ""  Vector__XXX
	SG_ FT_HFS_Tuer_Status : 21|2@1+ (1,0) [0|3] ""  Vector__XXX
	SG_ FT_kisi_asynchron : 40|1@1+ (1,0) [0|1] ""  Kombi
	SG_ FT_KiSi_Status_Soll_HBFS : 34|1@1+ (1,0) [0|1] ""  Vector__XXX
	SG_ FT_KiSi_Status_Soll_HFS : 35|1@1+ (1,0) [0|1] ""  Vector__XXX
	SG_ FT_Kisi_Taster_li_02 : 25|1@1+ (1,0) [0|1] ""  Vector__XXX
	SG_ FT_Kisi_Taster_re_02 : 26|1@1+ (1,0) [0|1] ""  Vector__XXX
	SG_ FT_Lock_Taster_02 : 15|1@1+ (1,0) [0|1] ""  Vector__XXX
	SG_ FT_Schluesselschalter_zu_02 : 16|1@1+ (1,0) [0|1] ""  Vector__XXX
	SG_ FT_SP_Heizung_ein : 24|1@1+ (1,0) [0|1] ""  Vector__XXX
	SG_ FT_TCR_Mode_aktiv : 29|1@1+ (1,0) [0|1] ""  Vector__XXX
	SG_ FT_TD_Taste_Status : 27|2@1+ (1,0) [0|3] ""  Vector__XXX
	SG_ FT_Tuer_Status : 12|2@1+ (1,0) [0|3] ""  ICAS3_Gateway,ICC_IO_Node,Kombi,ZR_MIB_TOP_ab_Gen3
	SG_ FT_Tuer_Status_QBit : 14|1@1+ (1,0) [0|1] ""  Vector__XXX
	SG_ FT_Tueroeffnen_Warnung : 23|1@1+ (1,0) [0|1] ""  Vector__XXX
	SG_ TBF_FS_Touch_Event : 30|4@1+ (1,0) [0|15] ""  ICAS3_Gateway,ICC_IO_Node
	SG_ TSG_FS_Spiegel_angeklappt : 37|1@1+ (1,0) [0|1] ""  Vector__XXX
	SG_ TSG_FT_02_BZ : 8|4@1+ (1,0) [0|15] ""  Vector__XXX
	SG_ TSG_FT_02_CRC : 0|8@1+ (1,0) [0|255] ""  Vector__XXX

BO_TX_BU_ 2463978804 :ICAS1_X_Gateway,ICAS3_Gateway;
BO_TX_BU_ 2463978800 :ICAS1_X_Gateway,ICAS3_Gateway;
BO_TX_BU_ 2463978801 :ICAS1_X_Gateway,ICAS3_Gateway;
BO_TX_BU_ 2463978802 :ICAS1_X_Gateway,ICAS3_Gateway;
BO_TX_BU_ 2463978803 :ICAS1_X_Gateway,ICAS3_Gateway;
BO_TX_BU_ 2463978806 :ICAS1_X_Gateway,ICAS3_Gateway;
BO_TX_BU_ 2463978805 :SmartLight_01;
BO_TX_BU_ 980 :ICAS1_X_Gateway;
BO_TX_BU_ 2536271634 :ICAS1_X_Gateway;
BO_TX_BU_ 2464161907 :ICAS3_Gateway,ICC_IO_Node,ZR_MIB_TOP_ab_Gen3;
BO_TX_BU_ 2464301171 :ICAS1_X_Gateway;
BO_TX_BU_ 2589283756 :ICAS1_X_Gateway;
BO_TX_BU_ 2464153715 :ICAS3_Gateway,ICC_IO_Node,ZR_MIB_TOP_ab_Gen3;
BO_TX_BU_ 2464284787 :ICAS1_X_Gateway;
BO_TX_BU_ 2464153620 :Kombi;
BO_TX_BU_ 2464284692 :ICAS1_X_Gateway;
BO_TX_BU_ 2464288788 :ICAS1_X_Gateway;
BO_TX_BU_ 2527679739 :ICAS1_X_Gateway;
BO_TX_BU_ 1413 :ICAS1_X_Gateway;
BO_TX_BU_ 2589283775 :ICAS1_X_Gateway;
BO_TX_BU_ 2589283947 :ICAS1_X_Gateway;
BO_TX_BU_ 619 :ICAS1_X_Gateway;
BO_TX_BU_ 1637 :ICAS3_Gateway;
BO_TX_BU_ 2589283750 :ICAS1_X_Gateway;
BO_TX_BU_ 1001 :ICAS1_X_Gateway;
BO_TX_BU_ 1447 :ICAS1_X_Gateway;
BO_TX_BU_ 977 :ICAS1_X_Gateway;
BO_TX_BU_ 976 :ICAS1_X_Gateway;
BO_TX_BU_ 997 :ICAS1_X_Gateway;
CM_ BO_ 980 "Ab MQB 7.2";
CM_ BO_ 1413 "MQB, MLBevo";
CM_ BO_ 977 "ab MQB 7.05";
CM_ BO_ 976 "ab MQB 7.05";
CM_ SG_ 2463978804 SmaLi_brightness "Smart Light\nHelligkeitswert";
CM_ SG_ 2463978804 SmaLi_Checksum "Smart Light\nPrï?½fsumme";
CM_ SG_ 2463978804 SmaLi_Cnt_05 "Smart Light \nKommandozï?½hler";
CM_ SG_ 2463978804 SmaLi_CtrlCmd_01 "Smart Light \nKommando";
CM_ SG_ 2463978804 SmaLi_Loops "Smart Light\nAnzahl der Schleifen";
CM_ SG_ 2463978804 SmaLi_MovieBundleVersion "Smart Light\nVom ICAS3 gesendete Versionsnummer des Filmpakets";
CM_ SG_ 2463978804 SmaLi_MovieID "Smart Light \nFilmID";
CM_ SG_ 2463978804 SmaLi_SlotID_05 "Smart Light\nSlotnummer";
CM_ SG_ 2463978800 SmaLi_Cnt_01 "Smart Light \nKommandozï?½hler";
CM_ SG_ 2463978800 SmaLi_ColorValue_01 "Smart Light \nLED Farbwert";
CM_ SG_ 2463978800 SmaLi_ColorValue_02 "Smart Light \nLED Farbwert";
CM_ SG_ 2463978800 SmaLi_ColorValue_03 "Smart Light \nLED Farbwert";
CM_ SG_ 2463978800 SmaLi_ColorValue_04 "Smart Light \nLED Farbwert";
CM_ SG_ 2463978800 SmaLi_ColorValue_05 "Smart Light \nLED Farbwert";
CM_ SG_ 2463978800 SmaLi_ColorValue_06 "Smart Light \nLED Farbwert";
CM_ SG_ 2463978800 SmaLi_ColorValue_07 "Smart Light \nLED Farbwert";
CM_ SG_ 2463978800 SmaLi_ColorValue_08 "Smart Light \nLED Farbwert";
CM_ SG_ 2463978800 SmaLi_ColorValue_09 "Smart Light \nLED Farbwert";
CM_ SG_ 2463978800 SmaLi_ColorValue_10 "Smart Light \nLED Farbwert";
CM_ SG_ 2463978800 SmaLi_ColorValue_11 "Smart Light \nLED Farbwert";
CM_ SG_ 2463978800 SmaLi_ColorValue_12 "Smart Light \nLED Farbwert";
CM_ SG_ 2463978800 SmaLi_ColorValue_13 "Smart Light \nLED Farbwert";
CM_ SG_ 2463978800 SmaLi_ColorValue_14 "Smart Light \nLED Farbwert";
CM_ SG_ 2463978800 SmaLi_FrameCmd_01 "Smart Light \nKommando zur Steuerung der LED Frames";
CM_ SG_ 2463978800 SmaLi_length "Smart Light\nLï?½nge des SL-Frames";
CM_ SG_ 2463978800 SmaLi_SlotID_01 "Smart Light\nSlotnummer";
CM_ SG_ 2463978800 SmaLi_StartIndex "Smart Light\nStart-LED des SL-Frames im Smartlight";
CM_ SG_ 2463978801 SmaLi_Cnt_02 "Smart Light \nKommandozï?½hler";
CM_ SG_ 2463978801 SmaLi_ColorValue_15 "Smart Light \nLED Farbwert";
CM_ SG_ 2463978801 SmaLi_ColorValue_16 "Smart Light \nLED Farbwert";
CM_ SG_ 2463978801 SmaLi_ColorValue_17 "Smart Light \nLED Farbwert";
CM_ SG_ 2463978801 SmaLi_ColorValue_18 "Smart Light \nLED Farbwert";
CM_ SG_ 2463978801 SmaLi_ColorValue_19 "Smart Light \nLED Farbwert";
CM_ SG_ 2463978801 SmaLi_ColorValue_20 "Smart Light \nLED Farbwert";
CM_ SG_ 2463978801 SmaLi_ColorValue_21 "Smart Light \nLED Farbwert";
CM_ SG_ 2463978801 SmaLi_ColorValue_22 "Smart Light \nLED Farbwert";
CM_ SG_ 2463978801 SmaLi_ColorValue_23 "Smart Light \nLED Farbwert";
CM_ SG_ 2463978801 SmaLi_ColorValue_24 "Smart Light \nLED Farbwert";
CM_ SG_ 2463978801 SmaLi_ColorValue_25 "Smart Light \nLED Farbwert";
CM_ SG_ 2463978801 SmaLi_ColorValue_26 "Smart Light \nLED Farbwert";
CM_ SG_ 2463978801 SmaLi_ColorValue_27 "Smart Light \nLED Farbwert";
CM_ SG_ 2463978801 SmaLi_ColorValue_28 "Smart Light \nLED Farbwert";
CM_ SG_ 2463978801 SmaLi_ColorValue_29 "Smart Light \nLED Farbwert";
CM_ SG_ 2463978801 SmaLi_FrameCmd_02 "Smart Light \nKommando zur Steuerung der LED Frames";
CM_ SG_ 2463978801 SmaLi_SlotID_02 "Smart Light\nSlotnummer";
CM_ SG_ 2463978802 SmaLi_Cnt_03 "Smart Light \nKommandozï?½hler";
CM_ SG_ 2463978802 SmaLi_ColorValue_30 "Smart Light \nLED Farbwert";
CM_ SG_ 2463978802 SmaLi_ColorValue_31 "Smart Light \nLED Farbwert";
CM_ SG_ 2463978802 SmaLi_ColorValue_32 "Smart Light \nLED Farbwert";
CM_ SG_ 2463978802 SmaLi_ColorValue_33 "Smart Light \nLED Farbwert";
CM_ SG_ 2463978802 SmaLi_ColorValue_34 "Smart Light \nLED Farbwert";
CM_ SG_ 2463978802 SmaLi_ColorValue_35 "Smart Light \nLED Farbwert";
CM_ SG_ 2463978802 SmaLi_ColorValue_36 "Smart Light \nLED Farbwert";
CM_ SG_ 2463978802 SmaLi_ColorValue_37 "Smart Light \nLED Farbwert";
CM_ SG_ 2463978802 SmaLi_ColorValue_38 "Smart Light \nLED Farbwert";
CM_ SG_ 2463978802 SmaLi_ColorValue_39 "Smart Light \nLED Farbwert";
CM_ SG_ 2463978802 SmaLi_ColorValue_40 "Smart Light \nLED Farbwert";
CM_ SG_ 2463978802 SmaLi_ColorValue_41 "Smart Light \nLED Farbwert";
CM_ SG_ 2463978802 SmaLi_ColorValue_42 "Smart Light \nLED Farbwert";
CM_ SG_ 2463978802 SmaLi_ColorValue_43 "Smart Light \nLED Farbwert";
CM_ SG_ 2463978802 SmaLi_ColorValue_44 "Smart Light \nLED Farbwert";
CM_ SG_ 2463978802 SmaLi_FrameCmd_03 "Smart Light \nKommando zur Steuerung der LED Frames";
CM_ SG_ 2463978802 SmaLi_SlotID_03 "Smart Light\nSlotnummer";
CM_ SG_ 2463978803 SmaLi_Cnt_04 "Smart Light \nKommandozï?½hler";
CM_ SG_ 2463978803 SmaLi_ColorValue_45 "Smart Light \nLED Farbwert";
CM_ SG_ 2463978803 SmaLi_ColorValue_46 "Smart Light \nLED Farbwert";
CM_ SG_ 2463978803 SmaLi_ColorValue_47 "Smart Light \nLED Farbwert";
CM_ SG_ 2463978803 SmaLi_ColorValue_48 "Smart Light \nLED Farbwert";
CM_ SG_ 2463978803 SmaLi_ColorValue_49 "Smart Light \nLED Farbwert";
CM_ SG_ 2463978803 SmaLi_ColorValue_50 "Smart Light \nLED Farbwert";
CM_ SG_ 2463978803 SmaLi_ColorValue_51 "Smart Light \nLED Farbwert";
CM_ SG_ 2463978803 SmaLi_ColorValue_52 "Smart Light \nLED Farbwert";
CM_ SG_ 2463978803 SmaLi_ColorValue_53 "Smart Light \nLED Farbwert";
CM_ SG_ 2463978803 SmaLi_ColorValue_54 "Smart Light \nLED Farbwert";
CM_ SG_ 2463978803 SmaLi_ColorValue_55 "Smart Light \nLED Farbwert";
CM_ SG_ 2463978803 SmaLi_ColorValue_56 "Smart Light \nLED Farbwert";
CM_ SG_ 2463978803 SmaLi_ColorValue_57 "Smart Light \nLED Farbwert";
CM_ SG_ 2463978803 SmaLi_ColorValue_58 "Smart Light \nLED Farbwert";
CM_ SG_ 2463978803 SmaLi_ColorValue_59 "Smart Light \nLED Farbwert";
CM_ SG_ 2463978803 SmaLi_FrameCmd_04 "Smart Light \nKommando zur Steuerung der LED Frames";
CM_ SG_ 2463978803 SmaLi_SlotID_04 "Smart Light\nSlotnummer";
CM_ SG_ 2463978806 SmaLi_Cnt_07 "Smart Light \nKommandozï?½hler";
CM_ SG_ 2463978806 SmaLi_ColorValue_60 "Smart Light \nLED Farbwert";
CM_ SG_ 2463978806 SmaLi_ColorValue_61 "Smart Light \nLED Farbwert";
CM_ SG_ 2463978806 SmaLi_ColorValue_62 "Smart Light \nLED Farbwert";
CM_ SG_ 2463978806 SmaLi_ColorValue_63 "Smart Light \nLED Farbwert";
CM_ SG_ 2463978806 SmaLi_ColorValue_64 "Smart Light \nLED Farbwert";
CM_ SG_ 2463978806 SmaLi_ColorValue_65 "Smart Light \nLED Farbwert";
CM_ SG_ 2463978806 SmaLi_ColorValue_66 "Smart Light \nLED Farbwert";
CM_ SG_ 2463978806 SmaLi_ColorValue_67 "Smart Light \nLED Farbwert";
CM_ SG_ 2463978806 SmaLi_ColorValue_68 "Smart Light \nLED Farbwert";
CM_ SG_ 2463978806 SmaLi_ColorValue_69 "Smart Light \nLED Farbwert";
CM_ SG_ 2463978806 SmaLi_ColorValue_70 "Smart Light \nLED Farbwert";
CM_ SG_ 2463978806 SmaLi_ColorValue_71 "Smart Light \nLED Farbwert";
CM_ SG_ 2463978806 SmaLi_ColorValue_72 "Smart Light \nLED Farbwert";
CM_ SG_ 2463978806 SmaLi_ColorValue_73 "Smart Light \nLED Farbwert";
CM_ SG_ 2463978806 SmaLi_ColorValue_74 "Smart Light \nLED Farbwert";
CM_ SG_ 2463978806 SmaLi_FrameCmd_05 "Smart Light \nKommando zur Steuerung der LED Frames";
CM_ SG_ 2463978806 SmaLi_SlotID_07 "Smart Light\nSlotnummer";
CM_ SG_ 2463978805 SmaLi_AppSwVersion "SmartLight\nAuf dem SL-SG vorhandene Applikations-Software Version";
CM_ SG_ 2463978805 SmaLi_availMemory "Smart Light \nverfï?½gbarer Speicher im SL-SG in kByte";
CM_ SG_ 2463978805 SmaLi_Cnt_06 "Smart Light \nKommandozï?½hler";
CM_ SG_ 2463978805 SmaLi_CtrlCmdRsp_01 "Smart Light \nKommandoresponse";
CM_ SG_ 2463978805 SmaLi_error_cause "Smart Light \nFehlercode";
CM_ SG_ 2463978805 SmaLi_InterfaceVersion "Smart Light \nSW-VersionNumber";
CM_ SG_ 2463978805 SmaLi_MovieIDRsp "Smart Light \nFilmID";
CM_ SG_ 2463978805 SmaLi_numLEDs "Smart Light \nAnzahl der LEDs im Lichtband";
CM_ SG_ 2463978805 SmaLi_numOfSlots "Smart Light \nmax. Speicherslots im SL-SG";
CM_ SG_ 2463978805 SmaLi_SavedMovieBundleVersion "SmartLight\nAuf dem SL-SG gespeicherte Versionsnummer des Filmpakets";
CM_ SG_ 2463978805 SmaLi_SlotID_06 "Smart Light\nSlotnummer";
CM_ SG_ 2463978805 SmaLi_xPosCenter "Smart Light \nLED-Index im Lichtband vor FzgMitte";
CM_ SG_ 2463978805 SmaLi_xPosPassengerLeft "Smart Light \nLED-Index im Lichtband vor linkem Passagier";
CM_ SG_ 2463978805 SmaLi_xPosPassengerRight "Smart Light \nLED-Index im Lichtband vor rechtem Passagier";
CM_ SG_ 980 BH_Blinker_Fehler "Anzeige, ob am Lenkstockschalter ein Fehler anliegt.\nNotwendig aufgrund ASIL-Einstufung";
CM_ SG_ 980 BH_Blinker_li "Blinkerhebel Richtung links";
CM_ SG_ 980 BH_Blinker_re "Blinkerhebel Richtung rechts";
CM_ SG_ 980 BH_Fernlicht "Betaetigung Fernlicht\n";
CM_ SG_ 980 BH_Lichthupe "Betaetigung Lichthupe\n";
CM_ SG_ 980 FAS_Taster "Betaetigung FAS Taster\n";
CM_ SG_ 980 FAS_Taster_Fehler "Fehlerstatus FAS Taster\n";
CM_ SG_ 980 LRH_aktiv "Signal gibt an, ob ein Heizstrom durch die Lenkradheizung flieï?½t. Es dient der Auswertung durch das Energiemanagement.";
CM_ SG_ 980 LRH_On_Off "Status Lenkradheizung";
CM_ SG_ 980 LSS_Tastencode "0x00 = No key pressed / key released\n0x01 = Menu\n0x02 = Menu Up / Next Screen\n0x03 = Menu Down / Previous Screen\n0x04 = Up\n0x05 = Down\n0x06 = Up / Down ThumbWheel\n0x07 = OK (ThumbWheel-Button)\n0x08 = Cancel / Escape\n0x09..0x0F = reserved for furt";
CM_ SG_ 980 SMLS_01_BZ "4bit Botschaftszaehler, wird mit jeder Sendebotschaft inkrementiert";
CM_ SG_ 980 SMLS_01_CRC "Fï?½r MLB:\n'Berechnung siehe Lastenheft 'Kommunikationsabsicherung fï?½r FlexRay und CAN''\n\nAb MQB und MLBevo:\n'Berechnung siehe Lastenheft 'End-to-End Kommunikationsabsicherung''\n\nEndwerte siehe Begleitdokument 'S-PDU Kennungsfolgen'";
CM_ SG_ 980 SMLS_Hupe "Betaetigung Hupe\n";
CM_ SG_ 980 SMLS_P_verriegelt "Signal stellt den Status des Signals P-verriegelt auf den Fahrzeugbus zur Verfï?½gung. Nutzer sind z.B. die ELV, die das Signal fï?½r die Verriegelung benï?½tigt und die Funktion Verlassenswarnung, die den Fahrer beim Verrollen des Fahrzeugs warnt.";
CM_ SG_ 980 SMLS_P_verriegelt_plausibel "Signal stellt den Plausibilisierungstatus des Signals p_verriegelt auf den Fahrzeugbus zur Verfï?½gung. Eine Plausibilitï?½t muss explizit erkannt werden. Initial wird 'unplausibel' gesendet. Ein plausibles Signal wird erkannt, wenn p_verriegelt plausibel geg";
CM_ SG_ 980 SMLS_PTT "Betaetigung PTT";
CM_ SG_ 980 WH_Frontwaschen "Wischerhebel: Stellung Wisch Wasch vorne\n";
CM_ SG_ 980 WH_Heckintervall "Wischerhebel: Stellung Heckintervall\n";
CM_ SG_ 980 WH_Heckwaschen "Wischerhebel: Stellung Wisch Wasch hinten\n";
CM_ SG_ 980 WH_Intervall "Wischerhebel: Stellung Intervall\n";
CM_ SG_ 980 WH_Intervallstufen "Wischerhebel: Stellung Intervallstufen";
CM_ SG_ 980 WH_SRA "Scheinwerferreinigungsanlage\n\nderzeit nur bei PAG umgesetzt";
CM_ SG_ 980 WH_Tipwischen "Wischerhebel: Tippwischen\n\nMQB A0/ PQ26: Bei Verbau LSS (kein SMLS): gespiegelter Wert zu Signal WH_WischerStufe1";
CM_ SG_ 980 WH_Tipwischen_lang "Wischerhebel: Tippwischen lang\n(dient zur Auswertung fï?½r die Unterscheidung Tippwischen oder Serviceposition Wischer)";
CM_ SG_ 980 WH_Wischer_Fehler "Anzeige, ob am Lenkstockschalter ein Fehler anliegt.\nNotwendig aufgrund ASIL-Einstufung";
CM_ SG_ 980 WH_WischerStufe1 "Wischerhebel: Stufe Wischen 1\n";
CM_ SG_ 980 WH_WischerStufe2 "Wischerhebel: Stufe Wischen 2\n";
CM_ SG_ 2536271618 SOK_BAP_ENI4_ASG_03_Sig "Signatur im Rahmen des Authentischer-Broadcast-Protokoll\nGeschï?½tze Funktion: Bap-Katalog ENI4";
CM_ SG_ 2536271634 SOK_BAP_ENI4_FSG_03_Sig "Signatur im Rahmen des Authentischer-Broadcast-Protokoll\nGeschï?½tze Funktion: Bap-Katalog ENI4";
CM_ SG_ 2464161907 SOK_FoD_Info_El_Req_Challenge "Challenge im Rahmen des SOK Challenge-Response Protokolls.\n\nGeschï?½tzte Funktion: Function on Demand";
CM_ SG_ 2464301171 SOK_FoD_Info_El_Resp_Challenge "Challenge im Rahmen des SOK Challenge-Response Protokolls.\n\nGeschï?½tzte Funktion: Function on Demand";
CM_ SG_ 2589283756 SOK_ungeschuetzte_Zeit "Periodisch verschickter SOK Zeitwert des SOK Zeitmasters als Referenzzeit zur Erkennung von Clockjitter durch andere SOK Teilnehmer.\n\nDer Empfang dieses Signals ist verpflichtend fï?½r jedes Steuergerï?½t, das durch die authentische Broadcast Funktionalitï?½t";
CM_ SG_ 2464153715 SOK_Zeit_Info_El_Challenge "Challenge im Rahmen des SOK Challenge-Response Protokolls.\n\nGeschï?½tzte Funktion: Empfang der SOK-Zeit vom SOK-Zeitmaster; verbindlich fï?½r Steuergerï?½te, welche mit der durch SOK geschï?½tzten Broadcast Nachrichten empfangen oder versenden";
CM_ SG_ 2464284787 SOK_Zeit_Info_El_Signatur "Signatur im Rahmen des SOK Challenge-Response Protokolls.\n\nGeschï?½tzte Funktion: Empfang der SOK-Zeit vom SOK-Zeitmaster; verbindlich fï?½r Steuergerï?½te, welche mit der durch SOK geschï?½tzten Broadcast Nachrichten empfangen oder versenden";
CM_ SG_ 2464284787 SOK_Zeit_Info_El_Zeit "Aktueller Wert der SOK-Zeit des SOK-Zeitmasters; geschï?½tzt durch das SOK Challenge-Response Protokoll";
CM_ SG_ 2464153620 SOK_Zeit_Kombi_Challenge "Challenge im Rahmen des SOK Challenge-Response Protokolls.\n\nGeschï?½tzte Funktion: Empfang der SOK-Zeit vom SOK-Zeitmaster; verbindlich fï?½r Steuergerï?½te, welche mit der durch SOK geschï?½tzten Broadcast Nachrichten empfangen oder versenden";
CM_ SG_ 2464284692 SOK_Zeit_Kombi_Signatur "Signatur im Rahmen des SOK Challenge-Response Protokolls.\n\nGeschï?½tzte Funktion: Empfang der SOK-Zeit vom SOK-Zeitmaster; verbindlich fï?½r Steuergerï?½te, welche mit der durch SOK geschï?½tzten Broadcast Nachrichten empfangen oder versenden";
CM_ SG_ 2464288788 SOK_Zeit_Kombi_Zeit "Aktueller Wert der SOK-Zeit des SOK-Zeitmasters; geschï?½tzt durch das SOK Challenge-Response Protokoll";
CM_ SG_ 2527679739 STK_Anf_AussenspiegelHZ "Anforderung Auï?½enspiegelheizung seitens Klimafunktion (z.B. bei Erweiterter VoKo)";
CM_ SG_ 2527679739 STK_Berechnungsphase "Status der Berechnungsphase Vorkonditionierung.\n\n0 = keine Berechnungsphase\n1 = Berechnungsphase erforderlich\n2 = Init\n3 = Fehler";
CM_ SG_ 2527679739 STK_Betriebsdauer "Betriebsdauer (TimeRemaining) Standklima Frontend";
CM_ SG_ 2527679739 STK_ErwVK_Anf "Anforderung  zur Aktivierung der Erweiterten-Vorkonditionierung  im  Innenraum";
CM_ SG_ 2527679739 STK_ErwVK_Beifahrerzone "Erweiterte Voko Beifahrerseite";
CM_ SG_ 2527679739 STK_ErwVK_Fahrerzone "Erweiterte Voko Fahrerseite";
CM_ SG_ 2527679739 STK_ErwVK_Heckzone2_links "Anforderung der erweiterten Standklimatisierung in der dritten Sitzreihe links";
CM_ SG_ 2527679739 STK_ErwVK_Heckzone2_rechts "Anforderung der erweiterten Standklimatisierung fï?½r die dritte Sitzreihe rechts.";
CM_ SG_ 2527679739 STK_ErwVK_Heckzone_links "Erweiterte Voko Sitzheizung hinten links";
CM_ SG_ 2527679739 STK_ErwVK_Heckzone_rechts "Erweiterte Voko Sitzheizung hinten rechts";
CM_ SG_ 2527679739 STK_ErwVK_Modus "Erweiterte Voko angefordert";
CM_ SG_ 2527679739 STK_ErwVK_Scheibenheizung "Erweiterte Voko Scheibenheizung Freigabe";
CM_ SG_ 2527679739 STK_FSH_Anf "Frontscheibenheizung anfordern";
CM_ SG_ 2527679739 STK_GesamtEnergiebedarf "Fï?½r den Klimavorgang benï?½tigte Energie von ca. 15 kWh fï?½r Signal \nSTK_GesamtEnergiebedarf";
CM_ SG_ 2527679739 STK_HSH_Anf "Heckscheibenheizung anfordern";
CM_ SG_ 2527679739 STK_Klima_Temp "MEB: Gewï?½nschte Innenraumtemperatur, auf die bei der Standklimatisierung geregelt werden soll.\nMQB: Temperatur die vom Nutzer vorgewï?½hlt wurde (VW: low=15,5 ï?½C/ high=30,0ï?½C)";
CM_ SG_ 2527679739 STK_KurzVK_Anf "Anforderung der kurz-Vorkonditionierung  zur Aktivierung der Vorkonditionierung Innenraum";
CM_ SG_ 2527679739 STK_MaxLeistung "Anforderung an  HVLM ï?½ber den Maximalwert der angeforderten Energieleistung fï?½r Klima-Vorkonditionierung";
CM_ SG_ 2527679739 STK_Standklima_Anf "Anforderung der Vorkonditionierung zur Aktivierung der Vorkonditionierung Innenraum";
CM_ SG_ 2527679739 STK_Standklima_Timer_Status "Signalisierung an die Klima Black Box ob mind. ein Timer zur Standklimatisierung programmiert ist";
CM_ SG_ 2527679739 STK_Stecker_Status "ï?½bermittlung Status des Ladesteckers fï?½r das Klima Steuergerï?½t";
CM_ SG_ 2527679739 STK_VK_Modus "ï?½bermittlung des aktuellen Konditionierungs-Status fï?½r HMI, Mobile Online Dienste";
CM_ SG_ 2527679739 STK_VK_STH_Einsatz "Anforderung(STK) an CCM zur Freigabe der Standheizung";
CM_ SG_ 2527679739 STK_VK_Timer_Status "Statusmeldung an BMCe zum Vorkonditionierungsmodus, zur Aktivierung der Vorkonditionierung der HV-Batterie.\n'aktiv' = falls die Batterie einen Kï?½hl-/Heizbedarf festgestellt hat, darf diese Batterie darf diese eine HV-Aktivierung anfordern und die Batteri";
CM_ SG_ 2527679739 STK_Voko_LED "Signalisierung des Standheizungsbetriebs";
CM_ SG_ 1413 GW_KD_Fehler "Kundendienstfehlerbit Gateway zur Anzeige eines im Gateway abgelegten Fehlerspeichereintrages.";
CM_ SG_ 1413 SI_BUS_01 "MQB/MQB_A0/PQ26: ACAN\nMQB2020: ACAN(FD)\nMLBevo: HCAN\nE3_Volumen: ACAN(FD)\nMQBw_Baseline: ACAN(FD)";
CM_ SG_ 1413 SI_BUS_02 "MQB/MQB A0 Standard+, High: FCAN\nMQB2020: FCAN(FD)\nMLBevo: Frei\nE3_Volumen: FCAN(FD)\nMQBw_Baseline: FCAN(FD)";
CM_ SG_ 1413 SI_BUS_03 "MQB/MQB A0/PQ26: KCAN\nMQB2020: KCAN\nMLBevo: KCAN\nE3_Volumen: KCAN(HS) / K2CAN(FD) (Buskopplung)\nMQBw_Baseline: KCAN(HS)";
CM_ SG_ 1413 SI_BUS_04 "MQB/MQB A0 Standard+, High: ICAN\nMQB2020: ICAN(HS)\nMLBevo: ICAN\nE3_Volumen: ABCAN(FD)\nMQBw_Baseline: ICAN(HS)";
CM_ SG_ 1413 SI_BUS_05 "MQB/MQB A0/PQ26: DiagCAN\nMQB2020: DiagCAN(FD)\nMLBevo: DiagCAN\nE3_Volumen: DiagCAN(FD)\nMQBw_Baseline: DiagCAN(FD)";
CM_ SG_ 1413 SI_BUS_06 "MQB/MQB A0/PQ26: ECAN\nMQB2020: FASCAN(FD)\nMLBevo: ECAN\nE3_Volumen: FASCAN_1(FD)\nMQBw_Baseline: FASCAN_1(FD)";
CM_ SG_ 1413 SI_BUS_07 "MQB: LIN1 (Energie)\nMQB2020: LIN1 (Energie)\nMLBevo: LIN1 (Energie)\nE3_Volumen: LIN 1 (Energie)\nMQBw_Baseline: LIN1 (Energie)";
CM_ SG_ 1413 SI_BUS_08 "MQB: LIN2 (MFL)\nMQB2020: LIN2 (MFL)\nMLBevo: LIN2 (MFL)\nE3_Volumen: LIN2 (MFL)\nMQBw_Baseline: LIN2 (MFL)";
CM_ SG_ 1413 SI_BUS_09 "MQB: LIN3 (unbelegt)\nMQB2020: LIN3 (Uhr/FES)\nMLBevo: LIN3 (Energie2)\nMEB: LIN3\nEï?½ 1.1 UNECE: MDKCAN";
CM_ SG_ 1413 SI_BUS_10 "MLBevo: Flexray\nMQB2020: MCAN\nMQBw_Baseline: FASCAN_2(FD)\nEï?½ 1.1 UNECE: FASCAN_2(FD)";
CM_ SG_ 1413 SI_BUS_11 "MLBevo: Ethernet\nMEB: LIN4";
CM_ SG_ 1413 SI_BUS_12 "MQB: unbelegt\nMLBevo: K2CAN\nE3_Volumen: MFLCAN\nMQBw_Baseline: K2CAN(FD)";
CM_ SG_ 1413 SI_BUS_13 "MQB: unbelegt\nMLBevo: DCAN\nMEB: CCAN\nMQBw_Baseline: K3CAN(FD)";
CM_ SG_ 1413 SI_BUS_14 "MQB/MQB A0: unbelegt\nMQB2020: HCAN\nMLBevo: CCAN\nE3_Volumen: EVCAN(FD)\nMQBw_Baseline: EVCANFD(FD)";
CM_ SG_ 1413 SI_BUS_15 "MQB: frei\nMQB2020: frei\nMLBevo: frei\nMEB: AFSCAN";
CM_ SG_ 1413 SI_Bus_Identifikation "Das Signal identifiziert den Bus eindeutig. Das Signal ist konstant auf jedem Bus.\nDer Signalwert entspricht dem Wert 'Busnummer' aus der VW80127 Gateway_component_list_databus_identification (0x2A2D) 'Bus-Identifier'.";
CM_ SG_ 1413 SI_CAB_V15 "CAB = Clusteraktivbits (V15)";
CM_ SG_ 1413 SI_Diagnose_Aktiv "Gibt an ob Diagnose-Botschaften empfangen werden und somit eine Diagnose aktiv ist.\nMQB: Gibt an ob Diagnose-Bus Botschaften empfangen werden und somit eine Diagnose aktiv ist.";
CM_ SG_ 1413 SI_NWDF "Netzwerk-Diagnose Freigebe zur zentralen Aktivierung der Netzwerkdiagnose";
CM_ SG_ 1413 SI_NWDF_gueltig "Gï?½ltigkeitsbit zu SI_NWDF gemï?½ï?½ Lastenheft: Zentrale Aktivierung Netzwerkdiagnose";
CM_ SG_ 1413 SI_P_Mode "Zentrale Steuerung des Produktionsmodes gemï?½ï?½ Q-LAH-Produktionsmode (LAH.DUM.907.AS)";
CM_ SG_ 1413 SI_P_Mode_gueltig "zeigt an, ob es sich um ein Fahrzeug mit zentraler oder dezentraler Steu-erung des Produktionsmodes handelt\nSiehe Q-LAH Produktionsmode (LAH.DUM.907.AS)";
CM_ SG_ 1413 SI_QRS_Mode "Messmodus Quick-Ruhestrom";
CM_ SG_ 1413 SI_Sammel_SG_Fehler "Anzahl der gesetzten KD-Fehler direkt angeschlossener Steuergerï?½te der DK3 und DK4 gemï?½ï?½ 80127.\nHinweis: Ein Subbusmaster stellt nur die gesammelte Information der an ihn angeschlossenen Steuergerï?½te der DK3 und DK4 zur Verfï?½gung.\n\nFï?½r ServiceKey Auswe";
CM_ SG_ 1413 SI_Sammelfehler "Sammelfehlermeldung zur Anzeige im Kombi - siehe Spez. Sammelfehlermeldung\nHinweis: Einzelne Steuergerï?½te kï?½nnen zur Anpassung an den Produktionsprozess im Gateway auskodiert werden!";
CM_ SG_ 1413 SI_T_Mode "0x0: Transportmodus nicht aktiv\n0x1: Transportmodus aktiv";
CM_ SG_ 1413 SI_T_Schutz "Transportschutz-Signal, das bei Transportmodus und Motorlauf aktiv bleibt\n0x0: Transportschutz nicht aktiv\n0x1: Transportschutz aktiv";
CM_ SG_ 2589283775 NM_aktiv_Buskopplung "Nachlauf wegen Buskopplung (z.B. FAS CAN1 und CAN2)";
CM_ SG_ 2589283775 NM_aktiv_CAB "Nachlauf wegen empfangenen CAB-Signal";
CM_ SG_ 2589283775 NM_aktiv_CWU "Nachlauf wegen empfangenen CarWakeUp";
CM_ SG_ 2589283775 NM_Req_CMS "Cluster werden auf Grund einer Aktivitï?½t dieser SWC wachgehalten";
CM_ SG_ 2589283775 NM_Req_DCP_01 "Cluster werden auf Grund einer Aktivitï?½t dieser SWC wachgehalten";
CM_ SG_ 2589283775 NM_Req_DCP_02 "Cluster werden auf Grund einer Aktivitï?½t dieser SWC wachgehalten";
CM_ SG_ 2589283775 NM_Req_DIM "Cluster werden auf Grund einer Aktivitï?½t dieser SWC wachgehalten";
CM_ SG_ 2589283775 NM_Req_ECM "Cluster werden auf Grund einer Aktivitï?½t dieser SWC wachgehalten";
CM_ SG_ 2589283775 NM_Req_EMHLR "Cluster werden auf Grund einer Aktivitï?½t dieser SWC wachgehalten";
CM_ SG_ 2589283775 NM_Req_EOC "Cluster werden auf Grund einer Aktivitï?½t dieser Easy-Open-Close wachgehalten";
CM_ SG_ 2589283775 NM_Req_FoD "Dieser Bus wird auf Grund einer Aktivitï?½t der Function on Demand wachgehalten";
CM_ SG_ 2589283775 NM_Req_HVEM "Dieser Bus wird auf Grund einer Aktivitï?½t des Hochvolt Energiemanagements wachgehalten";
CM_ SG_ 2589283775 NM_Req_IAA_PSO "Dieser Bus wird auf Grund einer Aktivitï?½t des User State Servers wachgehalten";
CM_ SG_ 2589283775 NM_Req_internal "Cluster werden auf Grund einer Aktivitï?½t dieser SWC wachgehalten";
CM_ SG_ 2589283775 NM_Req_Kessy "Dieser Bus wird auf Grund einer Aktivitï?½t der Funktion Kessy wachgehalten";
CM_ SG_ 2589283775 NM_Req_KLS "Dieser Bus wird auf Grund einer Aktivitï?½t der Klemmensteuerung wachgehalten";
CM_ SG_ 2589283775 NM_Req_KS "Dieser Bus wird auf Grund einer Aktivitï?½t des Komponentenschutzes wachgehalten";
CM_ SG_ 2589283775 NM_Req_PaCo "Dieser Bus wird auf Grund einer Aktivitï?½t des Park Koordinators wachgehalten";
CM_ SG_ 2589283775 NM_Req_RTM "Cluster werden auf Grund einer Aktivitï?½t dieser SWC wachgehalten";
CM_ SG_ 2589283775 NM_Req_SAL "Dieser Bus wird auf Grund einer Aktivitï?½t des Standardauï?½enlichts wachgehalten";
CM_ SG_ 2589283775 NM_Req_STK "Cluster werden auf Grund einer Aktivitï?½t dieser SWC wachgehalten";
CM_ SG_ 2589283775 NM_Req_SWC1 "Cluster werden auf Grund einer Aktivitï?½t dieser SWC wachgehalten";
CM_ SG_ 2589283775 NM_Req_SWC2 "Cluster werden auf Grund einer Aktivitï?½t dieser SWC wachgehalten";
CM_ SG_ 2589283775 NM_Req_USS "Dieser Bus wird auf Grund einer Aktivitï?½t des User State Servers wachgehalten";
CM_ SG_ 2589283775 NM_Req_ZM "Dieser Bus wird auf Grund einer Aktivitï?½t des Zeitmasters wachgehalten";
CM_ SG_ 2589283775 NM_Req_ZV "Cluster werden auf Grund einer Aktivitï?½t dieser SWC wachgehalten";
CM_ SG_ 2589283775 Powerstate_Act "Zeigt die ï?½bergï?½nge und Zustï?½nde des Powermanagements vom Sender an";
CM_ SG_ 2589283775 Powerstate_Time "Zeigt die Dauer des Ausgangszustands an";
CM_ SG_ 2589283947 NM_Reason_CMS "Cluster werden auf Grundeiner Aktivitï?½t des Charging Management Servers vom HVLM wachgehalten";
CM_ SG_ 2589283947 NM_Reason_DCP_1 "Cluster werden auf Grundeiner Aktivitï?½t von Dynamic Charging POIs vom HVLM wachgehalten";
CM_ SG_ 2589283947 NM_Reason_DCP_2 "Cluster werden auf Grundeiner Aktivitï?½t von Dynamic Charging POIs (Req) vom HVLM wachgehalten";
CM_ SG_ 2589283947 NM_Reason_DIM "Cluster werden auf Grundeiner Aktivitï?½t der Dimmung wachgehalten.";
CM_ SG_ 2589283947 NM_Reason_ECM "Cluster werden auf Grundeiner Aktivitï?½t des Extended Charging Monitoring vom HVLM wachgehalten";
CM_ SG_ 2589283947 NM_Reason_EMHLR "Cluster werden auf Grundeiner Aktivitï?½t der Energiemanagement Heizleistungsregelung wachgehalten";
CM_ SG_ 2589283947 NM_Reason_EOC "Cluster werden auf Grund einer Aktivitï?½t Easy-Open-Close wachgehalten.";
CM_ SG_ 2589283947 NM_Reason_FoD "Cluster werden auf Grundeiner Aktivitï?½t der Function on Demand wachgehalten";
CM_ SG_ 2589283947 NM_Reason_HVEM "Cluster werden auf Grundeiner Aktivitï?½t des Hochvolt Energiemanagements wachgehalten";
CM_ SG_ 2589283947 NM_Reason_IAA_PSO "Cluster werden auf Grundeiner Aktivitï?½t des IAA wachgehalten";
CM_ SG_ 2589283947 NM_Reason_ICAS1_internal "Cluster werden auf Grund einer internen ICAS Aktivitï?½t wachgehalten";
CM_ SG_ 2589283947 NM_Reason_Kessy "Cluster werden auf Grund einer Aktivitï?½t der Funktion Kessy wachgehalten";
CM_ SG_ 2589283947 NM_Reason_KLS "Cluster werden auf Grundeiner Aktivitï?½t der Klemmensteuerung wachgehalten";
CM_ SG_ 2589283947 NM_Reason_KS "Cluster werden auf Grundeiner Aktivitï?½t des Komponentenschutzes wachgehalten";
CM_ SG_ 2589283947 NM_Reason_PaCo "Cluster werden auf Grundeiner Aktivitï?½t des Park Koordinators wachgehalten";
CM_ SG_ 2589283947 NM_Reason_RTM "Cluster werden auf Grundeiner Aktivitï?½t des Real Time Monitors wachgehalten";
CM_ SG_ 2589283947 NM_Reason_SAL "Cluster werden auf Grundeiner Aktivitï?½t des Standardauï?½enlichts wachgehalten";
CM_ SG_ 2589283947 NM_Reason_STK "Cluster werden auf Grundeiner Aktivitï?½t der Standklimatisierung wachgehalten";
CM_ SG_ 2589283947 NM_Reason_SWC1 "Cluster werden auf Grundeiner Aktivitï?½t einer Softwarekomponente 1 wachgehalten.";
CM_ SG_ 2589283947 NM_Reason_SWC2 "Cluster werden auf Grundeiner Aktivitï?½t einer Softwarekomponente 2 wachgehalten.";
CM_ SG_ 2589283947 NM_Reason_USS "Cluster werden auf Grundeiner Aktivitï?½t des User State Servers wachgehalten";
CM_ SG_ 2589283947 NM_Reason_ZM "Cluster werden auf Grundeiner Aktivitï?½t des Zeitmasters wachgehalten";
CM_ SG_ 2589283947 NM_Reason_ZV "Cluster werden auf Grundeiner Aktivitï?½t der Zentralverriegelung wachgehalten";
CM_ SG_ 2589283947 Powerstate_Prev_01 "Zeigt die ï?½bergï?½nge und Zustï?½nde des Powermanagements vom Sender an";
CM_ SG_ 2589283947 Powerstate_Prev_02 "Zeigt die ï?½bergï?½nge und Zustï?½nde des Powermanagements vom Sender an";
CM_ SG_ 619 TA_01_BZ "4bit Botschaftszï?½hler, wird mit jeder Sendebotschaft inkrementiert";
CM_ SG_ 619 TA_01_CRC "Fï?½r MLB:\nBerechnung siehe Lastenheft 'Kommunikationsabsicherung fï?½r FlexRay und CAN'\nAb MQB und MLBevo:\nBerechnung siehe Lastenheft 'End-to-End Kommunikationsabsicherung'\n\nEndwerte siehe Begleitdokument 'S-PDU Kennungsfolgen'";
CM_ SG_ 619 TA_ACC_Sollstatus "Status-Anforderung ACC vom TravelAssist";
CM_ SG_ 619 TA_aktiv_HMI "Signalwert an Anzeigegerï?½t welche Funktion aktiv";
CM_ SG_ 619 TA_Fehler "Fehler im Modus Travel Assist";
CM_ SG_ 619 TA_FoD_Status "TAwird durch FoD geschï?½tzt sein und so reicht die PR/Zieldatencontainer basierte Codierung nicht mehr aus.\n\nAus diesem Grund brauch wir ein separates Signal, dass uns den Freischaltezustand mitteilt.";
CM_ SG_ 619 TA_Handsoff_LED "Anfordern der Anzeige des LAHO-Icon in weiï?½ und rot unabhï?½ngig von der Textmeldung";
CM_ SG_ 619 TA_Spurwechsel "Anzeige fï?½r die Durchfï?½hrung eines Spurwechsels im Kombi";
CM_ SG_ 619 TA_Spurwechsel_Ready "Angabe der assistierten Spurwechselmï?½glichkeiten durch die Funktion 'Travel Assist'";
CM_ SG_ 619 TA_Status "Anzeige TravelAssist-Statusleuchte im Kombi";
CM_ SG_ 619 TA_Texte "Anzeige TravelAssist-Texte im Kombi";
CM_ SG_ 619 TA_Texte_02 "Anzeige TravelAssist-Texte im Kombi";
CM_ SG_ 619 TA_Ueberholhilfe "zusï?½tzliches Signal fï?½r Handshake TA <--> ACC hinsichtlich ï?½berholhilfe";
CM_ SG_ 1637 TF_BT_ConnectionState "Bei vorhandener BT-Verbindung zum Mobilgerï?½t soll im Kombiinstrument ein BT-Icon angezeigt werden.";
CM_ SG_ 1637 TF_Mute_Msg_Code "Tells the mute reason\n0 = Phonecall (Telephone voive)\n1 = Speech Recognition active (SDS active e.g. voice prompts)\n2 = Emergency Call\n3 = beep-signal (Signal tone)\n4 = Operator Call\n5 = Ringing\n6 = Phonecall wideband voice\n(e.g. UMTS min 100H";
CM_ SG_ 1637 TF_Phone_active_call "Phone status, call active (call in progress)\n0 = no active call  \n1 = call active ";
CM_ SG_ 1637 TF_Phone_err_fieldstrength "Signal strength not available or error: if set, \nthen the field strength is not determinable \nand the field strength information of \nTF_Phone_FieldStrength is invalid.";
CM_ SG_ 1637 TF_Phone_Error_Flag "State of CIB error memory \n0 = Error memory is empty  \n1 = Error memory is not empty (mindestens ein Kundendienstfehlerspeicher  \nEintrag vorhanden)";
CM_ SG_ 1637 TF_Phone_FieldStrength "Signal strength:(linear scaled range)\n0  = 0%\n15 = 100%";
CM_ SG_ 1637 TF_Phone_init "Phone initialization indication\n0 = Telephone is initialized \n1 = Initialization in progress ";
CM_ SG_ 1637 TF_Phone_mute "Request to mute audio\n0 = Audio active \n1 = Mute (TF_Mute_Msg_Code tells the reason) \n";
CM_ SG_ 1637 TF_Phone_on "Displays the current phone status\n0 = Phone not active (MMI off)\n1 = Phone active (MMI on)";
CM_ SG_ 1637 TF_Phone_PIN_ok "Result of entering the PIN. \n0 = PIN was not accepted by the SIM-card. \n1 = PIN was accepted by the SIM-card.";
CM_ SG_ 1637 TF_Phone_RegistrationState "Network registration status: \nset field to exact value from +CREG. In \ncase +CREG returns ERROR (or until first \nOK response comes after init bit switches \nto 0), set it to 7. \n0 = no service, not searching \n1 = registered at home network \n2 = no s";
CM_ SG_ 1637 TF_Phone_ring "Incoming or waiting call \n0 = phone does not ring  \n1 = phone rings ";
CM_ SG_ 1637 TF_Phone_SIM_ok "State of the SIM card reader\n0 = Telephone can not recognize SIM-card or no SIM-card inserted. \n1 = Telephone has detected the SIM card.";
CM_ SG_ 1637 TF_Telephone_State "This signal contain the information if a telephone call is active or not active.";
CM_ SG_ 2589283750 KBI_QBit_Aussen_Temp_gef "0x0 = gï?½ltiger Wert\n0x1 = Ersatz-, Init- oder Fehlerwert";
CM_ SG_ 1001 Thermo_Pred_Innen_Kunde_Anf "ï?½nderung der Prï?½diktion iniziiert durch Kundenaktion";
CM_ SG_ 1001 Thermo_Pred_Innen_System_Anf "Systemseitig initiierte ï?½nderung der Prï?½diktion; Signal ist einheitsloser Zï?½hler mit ï?½berlauf. \nEine Inkrementierung steht fï?½r die ï?½nderung der Umgebungsbedingungen mit dazugehï?½riger Klimaleistungsï?½nderung.";
CM_ SG_ 1001 Thermo_Pred_P_dyn_Innen "Dynamsiche Leistung fï?½r Headup / Cooldown";
CM_ SG_ 1001 Thermo_Pred_P_stat_Innen "Stationï?½re Leistung fï?½r Heizen / Kï?½hlen";
CM_ SG_ 1001 Thermo_Pred_T_dyn_Innen "Zeit bis zum ï?½bergang vom dynamischen in stationï?½ren Betrieb";
CM_ SG_ 1001 Thermo_Verbrauch_BTL "Verbrauch fï?½r Heizen und Kï?½hlen der Bauteile";
CM_ SG_ 1001 Thermo_Verbrauch_BTL_Ueberlauf "ï?½berlauf-Bit Verbrauch Bauteil";
CM_ SG_ 1001 Thermo_Verbrauch_Innen "Verbrauch fï?½r Heizen und Kï?½hlen Innenraum";
CM_ SG_ 1001 Thermo_Verbrauch_Innen_Ueberlauf "ï?½berlauf-Bit Verbrauch Innenraum";
CM_ SG_ 1447 bCall_active "1: Breakdown call is active\n0: BreakdownCall is inactive";
CM_ SG_ 1447 eCall_Funktionsstatus "HMI-Aufruf im Kombi (Broadcast)\nFehlerfï?½lle die im Kombi angezeigt werden kï?½nnen";
CM_ SG_ 1447 eCall_Funktionsstatus_02 "Erweiterung des Funktionsstatus fï?½r andere Funktionen\nACN aktiv, MEC aktiv\nMEC = manual emergency call = maueller Notruf\nACN = automatic emergency call = automatischer Notruf";
CM_ SG_ 1447 iCall_active "Statusrï?½ckmeldung von OCU ï?½ber Infocall aktiv/inaktiv";
CM_ SG_ 1447 MOD_Energie_Anf "Anforderung Energieversorgung MOD-Job an das NVEM";
CM_ SG_ 1447 OCU_Privacymode_Locationdata "Signal zur Ausgabe des speziellen Privacymode Status zur Ausleitung von Fahrzeugpositionsdaten.\n\n0 = Init\n1 = Ausgabe der Fahrzeugpositionsdaten ist erlaubt\n2 = Ausgabe der Fahrzeugpositionsdaten ist untersagt";
CM_ SG_ 1447 OCU_Privacymode_Status "Signal zur Ausgabe des Privacymode Status\n\n0 = Init\n1 = Privacymode ist nicht aktiv\n2 = Privacymode ist aktiv";
CM_ SG_ 1447 TM_01_BZ "4bit Botschaftszï?½hler, wird mit jeder Sendebotschaft inkrementiert";
CM_ SG_ 1447 TM_Door_Lock "Remote Door lock angefordert: ZV zu/verriegeln";
CM_ SG_ 1447 TM_Door_Unlock "Remote Door unlock angefordert: ZV auf/entriegeln";
CM_ SG_ 1447 TM_Nur_Hupen "Remote Hupen (ohne Blinken) aktiviert";
CM_ SG_ 1447 TM_Panik_Alarm "Remote Hupen und Blinken aktiv";
CM_ SG_ 1447 TM_Spiegel_Anklappen "Anklappen der Auï?½enspiegel ï?½ber Remote MOD Anforderung";
CM_ SG_ 1447 TM_Warnblinken "Remote Blinken aktiviert";
CM_ SG_ 1447 TM_ZV_Signatur "Gespeicherte Signatur der ZV fï?½r Authentifizierung";
CM_ SG_ 977 ASW_Warnung_aktiv_BFS "Abschaltung der Ambientefunktion Beifahrertï?½r bei aktiver ASW Warnung an der Fahrertï?½r";
CM_ SG_ 977 BFS_Status_eTAG "Status des elektrischen Tueraussengriffes Beifahrertuer";
CM_ SG_ 977 BT_ASW_HMI_defekt "Zeigt an, ob die ASW-Anzeige defekt ist.";
CM_ SG_ 977 BT_EC_Spiegel_Helligkeit "Dimmung fï?½r den Aussenspiegel in %";
CM_ SG_ 977 BT_FH_Bew_hoch "Fensterheber in Bewegung Richtung hoch";
CM_ SG_ 977 BT_FH_Bew_tief "Fensterheber in Bewegung Richtung tief";
CM_ SG_ 977 BT_FH_Block "Fensterscheibe befindet sich im mechanischen Block (oben oder unten)";
CM_ SG_ 977 BT_FH_Fang "Fangbereich ist 4mm von oberer Lippendichtung";
CM_ SG_ 977 BT_FH_normiert "Die Position der Fensterheberscheibe ist bekannt";
CM_ SG_ 977 BT_FH_Oeffnung "Gibt den Fensterï?½ffnungswert in % an.";
CM_ SG_ 977 BT_FH_S_AutoHoch "FH Schalter automatisch hoch gedrï?½ckt";
CM_ SG_ 977 BT_FH_S_AutoTief "FH Schalter automatisch tief gedrï?½ckt";
CM_ SG_ 977 BT_FH_S_ManHoch "FH Schalter manuell hoch gedrï?½ckt";
CM_ SG_ 977 BT_FH_S_ManTief "FH Schalter manuell tief gedrï?½ckt";
CM_ SG_ 977 BT_FH_Thermo "gibt an ob Fensterheber im Thermoschutz ist";
CM_ SG_ 977 BT_gesafet "Im Zustand Safe wird auch das Signal BT_verriegelt = 1 gesendet";
CM_ SG_ 977 BT_Kisi_Fehler "Fehlerstatus Kindersicherungsfunktion";
CM_ SG_ 977 BT_Lock_Taster "Verriegelungstaster";
CM_ SG_ 977 BT_Lock_Taster_inv "Lock Taster nicht betï?½tigt";
CM_ SG_ 977 BT_Lock_Unlock_Taster "ZV Funktion Lock Unlock mit Toggle-Logik";
CM_ SG_ 977 BT_Oben_Block_erw "Fensterheber in Blockerwartung oben";
CM_ SG_ 977 BT_Schluesselschalter_auf "Schlï?½sselschalter Richtung auf betï?½tigt";
CM_ SG_ 977 BT_Schluesselschalter_zu "Schluesselschalter Richtung zu betaetigt";
CM_ SG_ 977 BT_Schluesselschalter_zu_inv "Schluesselschalter zu nicht betaetigt";
CM_ SG_ 977 BT_SP_ausgerastet "Spiegel ausgerastet";
CM_ SG_ 977 BT_Sp_Blk_def "Blinker am Spiegel defekt";
CM_ SG_ 977 BT_Sp_Heizung_Anf "Kundenanforderung der Auï?½enspiegelheizung Beifahrertï?½r";
CM_ SG_ 977 BT_SP_Heizung_Status "Status der Spiegelheizung";
CM_ SG_ 977 BT_SP_ht_aktiv "Spiegelverstellung in Richtung hoch/tief aktiv";
CM_ SG_ 977 BT_SP_lr_aktiv "Spiegelverstellung in Richtung links/rechts aktiv";
CM_ SG_ 977 BT_Sperrklinke "Vorraste fï?½r Schloï?½\n\nzwischen Vor- und Hauptraste Signal kurz auf 1, danach wieder auf 0 wenn Tï?½r in Hauptraste (Tï?½r ist sicher zu wenn Sperrklinke und Tï?½rkontakt auf 0 sind)";
CM_ SG_ 977 BT_SWA_HMI_defekt "Zeigt an, ob die SWA-Anzeige defekt ist.";
CM_ SG_ 977 BT_TAG_betaetigt "Tï?½raussengriff";
CM_ SG_ 977 BT_TCR_Mode_aktiv "Signal zeigt eine aktive mechanische Redundanz am Tï?½rschloss an.";
CM_ SG_ 977 BT_TIG_betaetigt "Tï?½rinnengriff";
CM_ SG_ 977 BT_Tuer_geoeffnet "Zeigt eine geï?½ffnete Tï?½r an";
CM_ SG_ 977 BT_Tuer_Status "Tï?½rstatus mit Fehler und Initwert";
CM_ SG_ 977 BT_Tuer_Status_QBit "Dieses Bit gibt die Zuverlï?½ssigkeit des Tï?½rkontakts an. Ein auf dieses Bit folgender Fehlereintrag ist mit dem Sender des Bits abzustimmen (gï?½ltig ab PPE).";
CM_ SG_ 977 BT_Tueroeffnen_Warnung "Bit wird gesetzt, wenn Tï?½r wï?½hrend der Fahrt geoeffnet werden soll.";
CM_ SG_ 977 BT_Tuerschloss_defekt "Das Beifahrertï?½rschloss ist nicht mehr funktionsfï?½hig.";
CM_ SG_ 977 BT_UEKB_aktiviert "ï?½berschutzbegrenzungskraft bei Reversieren";
CM_ SG_ 977 BT_Unlock_Taster "Entriegelungstaster betï?½tigt";
CM_ SG_ 977 BT_Unten_Block_erw "Fensterheber in Blockerwartung unten";
CM_ SG_ 977 BT_verriegelt "Zeigt eine verriegelte Tï?½r an ( Status wird erst nach vollstï?½ndiger Schlossansteuerung ausgegeben (<=1,5sek))";
CM_ SG_ 977 BT_Zuziehhilfe_aktiv "Zuziehhilfe aktiv";
CM_ SG_ 976 ASW_HMI_defekt "HMI Status der Funktion AusstiegsWarnung (ASW). HMI wird durch das TSG angesteuert.";
CM_ SG_ 976 ASW_wakeup "Trigger Start Nachlaufzeit t_1 fï?½r die Funktion Ausstieswarnung (ASW)";
CM_ SG_ 976 ASW_Warnung_aktiv_FS "Abschaltung der Ambientefunktion Fahrertï?½r bei aktiver ASW Warnung an der Fahrertï?½r";
CM_ SG_ 976 FS_Status_eTAG "Status des elektrischen Tueraussengriffes Fahrertuer";
CM_ SG_ 976 FT_BFS_Fond_Freigabe "Freigabe fï?½r Fondverstellung";
CM_ SG_ 976 FT_Daemmglas "Daemmglas verbaut";
CM_ SG_ 976 FT_FH_Bew_hoch "Fensterheber in Bewegung Richtung hoch";
CM_ SG_ 976 FT_FH_Bew_tief "Fensterheber in Bewegung Richtung tief";
CM_ SG_ 976 FT_FH_Block "Fensterscheibe befindet sich im mechanischen Block (oben oder unten)";
CM_ SG_ 976 FT_FH_Fang "Fangbereich ist 4mm von oberer Lippendichtung";
CM_ SG_ 976 FT_FH_normiert "Die Position der Fensterheberscheibe ist bekannt";
CM_ SG_ 976 FT_FH_Oeffnung "Gibt den Fensterï?½ffnungswert in % an.";
CM_ SG_ 976 FT_FH_S_AutoHoch "FH Schalter automatisch hoch gedrï?½ckt";
CM_ SG_ 976 FT_FH_S_AutoTief "FH Schalter automatisch tief gedrï?½ckt";
CM_ SG_ 976 FT_FH_S_ManHoch "FH Schalter manuell hoch gedrï?½ckt";
CM_ SG_ 976 FT_FH_S_ManTief "FH Schalter manuell tief gedrï?½ckt";
CM_ SG_ 976 FT_FH_Thermo "gibt an ob Fensterheber im Thermoschutz ist";
CM_ SG_ 976 FT_gesafet "Im Zustand Safe wird auch das Signal FT_verriegelt = 1 gesendet";
CM_ SG_ 976 FT_HD_Taste "Taste in der Fahrertï?½r zum ï?½ffnen des Heckschlosses";
CM_ SG_ 976 FT_HD_Taste_2 "2. HD-Taste im Bedienfeld \nFunktion: Heckdeckel schlieï?½en";
CM_ SG_ 976 FT_IRUE_Taste "Betï?½tigung IRUE-Taster (Innenraumï?½berwachung)\nMQB: Bei Verbau eines einzelnen Taster zur Deaktivierung von IRUE und NGS wird dieses Signal als Deaktivierungsanforderung beider DWA-Alarmquellen gesendet.";
CM_ SG_ 976 FT_Kisi_Fehler "Fehlerstatus Kindersicherungsfunktion";
CM_ SG_ 976 FT_Kisi_li_aktiv "Aktivierungsstatus der Kindersicherung links";
CM_ SG_ 976 FT_Kisi_re_aktiv "Aktivierungsstatus der Kindersicherung rechts";
CM_ SG_ 976 FT_Kisi_Taster_li "Linker Kisi Taster betaetigt";
CM_ SG_ 976 FT_Kisi_Taster_re "Rechter Kisi Taster betaetigt";
CM_ SG_ 976 FT_Lock_Taster "Verriegelungstaster betï?½tigt";
CM_ SG_ 976 FT_Lock_Unlock_Taster "ZV Funktion Lock Unlock mit Toggle-Logik";
CM_ SG_ 976 FT_Oben_Block_erw "Fensterheber in Blockerwartung oben";
CM_ SG_ 976 FT_Schliesstaster "Vorhalt";
CM_ SG_ 976 FT_Schluesselschalter_auf "Schlï?½sselschalter Richtung auf betï?½tigt";
CM_ SG_ 976 FT_SP_ausgerastet "Spiegel ausgerastet";
CM_ SG_ 976 FT_Sp_Blk_def "Blinker am Spiegel defekt";
CM_ SG_ 976 FT_Sp_Heizung_Anf "Kundenanforderung der Auï?½enspiegelheizung Fahrertï?½r";
CM_ SG_ 976 FT_SP_Heizung_Status "Status der Spiegelheizung";
CM_ SG_ 976 FT_SP_ht_aktiv "Spiegelverstellung in Richtung hoch/tief aktiv";
CM_ SG_ 976 FT_SP_lr_aktiv "Spiegelverstellung in Richtung links/rechts aktiv";
CM_ SG_ 976 FT_Sperrklinke "Vorraste fï?½r Schloï?½\n\nzwischen Vor- und Hauptraste Signal kurz auf 1, danach wieder auf 0 wenn Tï?½r in Hauptraste (Tï?½r ist sicher zu wenn Sperrklinke und Tï?½rkontakt auf 0 sind)";
CM_ SG_ 976 FT_SWA_Taster "SWA/ASW Taster Fahrertï?½r";
CM_ SG_ 976 FT_TAG_betaetigt "Tï?½raussengriff\n\nwird nicht im MLB-B8 verwendet";
CM_ SG_ 976 FT_TD_Taste "Tankdeckelentriegelungs-Taste betï?½tigt";
CM_ SG_ 976 FT_TD_Taste_Fehler "Fehlerstatus des Tankdeckelentriegelungstasters. Wird bei Drucktankkonzepten vom MSG zusammen mit dem Signal FT_TD_Taste ausgewertet, um Tankbereitschaft herzustellen.\nDer Fehler beschreibt einen hï?½ngenden TD_Taster. Ein Kurzschluss oder Leitungsunterbre";
CM_ SG_ 976 FT_TIG_betaetigt "Tï?½rinnengriff\n\nwird nicht im MLB-B8 verwendet";
CM_ SG_ 976 FT_Tuer_geoeffnet "Zeigt eine geï?½ffnete Tï?½r an";
CM_ SG_ 976 FT_Tuerschloss_defekt "Das Fahrertï?½rschloss ist nicht mehr funktionsfï?½hig.";
CM_ SG_ 976 FT_UEKB_aktiviert "ï?½berschutzbegrenzungskraft bei Reversieren";
CM_ SG_ 976 FT_Unlock_Taster "Entriegelungstaster betï?½tigt";
CM_ SG_ 976 FT_Unten_Block_erw "Fensterheber in Blockerwartung unten";
CM_ SG_ 976 FT_verriegelt "Zeigt eine verriegelte Tï?½r an ( Status wird erst nach vollstï?½ndiger Schlossansteuerung ausgegeben (<=1,5sek))";
CM_ SG_ 976 FT_Zuziehhilfe_aktiv "Zuziehhilfe aktiv";
CM_ SG_ 976 SSR_Temp_Freigabe "Freigabe des Seitenscheibenrollos. Bit wird  fï?½r die Deaktivierung des SSR bei Innenraumtemperaturen kleiner -10 Grad verwendet.";
CM_ SG_ 976 SWA_HMI_Diagnose "SWA HMI Diagnose beim TSG";
CM_ SG_ 997 FT_BFS_Tuer_Status "Gesammelte Tï?½rstatusbotschaft";
CM_ SG_ 997 FT_Cargolock_bet "CargoLock-Taste betï?½tigt";
CM_ SG_ 997 FT_HBFS_Tuer_Status "Tï?½rstatus mit Fehler und Initwert";
CM_ SG_ 997 FT_HFS_Tuer_Status "Tï?½rstatus mit Fehler und Initwert";
CM_ SG_ 997 FT_kisi_asynchron "Signal erzeugt eine seperate Warnmeldung bei ungewollter Asynchronitï?½t der 'elektrische Kindersicherung' der Schlï?½sser.";
CM_ SG_ 997 FT_KiSi_Status_Soll_HBFS "Soll KiSi Status HBFS";
CM_ SG_ 997 FT_KiSi_Status_Soll_HFS "Soll Status der KiSi HFS";
CM_ SG_ 997 FT_Kisi_Taster_li_02 "Der Kindersicherungstaster hinten links aktiv.";
CM_ SG_ 997 FT_Kisi_Taster_re_02 "Der Kindersicherungstaster hinten rechts aktiv.";
CM_ SG_ 997 FT_Lock_Taster_02 "Lock-Taster betï?½tigt";
CM_ SG_ 997 FT_Schluesselschalter_zu_02 "Schlï?½sselschalter fï?½r Schlieï?½en betï?½tigt";
CM_ SG_ 997 FT_SP_Heizung_ein "Dieses Signal zeigt die tatsï?½chliche Ansteuerung der  Spiegelheizung incl. PWM an. \nZudem wird aufgrund des Teilnetzbetriebs das Signal zur Ansteuerung der Beifahrer-Spiegelheizung benutzt.\n\n";
CM_ SG_ 997 FT_TCR_Mode_aktiv "Signal zeigt eine aktive mechanische Redundanz am Tï?½rschloss an.";
CM_ SG_ 997 FT_TD_Taste_Status "Status Taste fï?½r Tankdeckel";
CM_ SG_ 997 FT_Tuer_Status "Tï?½r geï?½ffnet oder Tï?½r geschlossen";
CM_ SG_ 997 FT_Tuer_Status_QBit "Dieses Bit gibt die Zuverlï?½ssigkeit des Tï?½rkontakts an.";
CM_ SG_ 997 FT_Tueroeffnen_Warnung "Bit wird gesetzt, wenn Tï?½r wï?½hrend der Fahrt geoeffnet werden soll.";
CM_ SG_ 997 TBF_FS_Touch_Event "Touch_Events fï?½r Informationen einer Funktionsauslï?½sung auf dem TBF, welche dann fï?½r bspw. ein akustisches Signal zentral umgesetzt werden kï?½nnen.";
CM_ SG_ 997 TSG_FS_Spiegel_angeklappt "Funktionsrï?½ckmeldung TSG_FS ï?½ber Spiegelstellung angeklappt";
CM_ SG_ 997 TSG_FT_02_BZ "4bit Botschaftszaehler, wird mit jeder Sendebotschaft inkrementiert";
CM_ SG_ 997 TSG_FT_02_CRC "Fï?½r MLB:\n'Berechnung siehe Lastenheft 'Kommunikationsabsicherung fï?½r FlexRay und CAN''\n\nAb MQB und MLBevo:\n'Berechnung siehe Lastenheft 'End-to-End Kommunikationsabsicherung''\n\nEndwerte siehe Begleitdokument 'S-PDU Kennungsfolgen'";
BA_DEF_ BO_ "CANFD_BRS" ENUM "0", "1";
BA_DEF_ BO_ "DiagRequest" ENUM "No", "Yes";
BA_DEF_ BO_ "DiagResponse" ENUM "No", "Yes";
BA_DEF_ BO_ "DiagState" ENUM "No", "Yes";
BA_DEF_ BO_ "GenMsgChkConstant" HEX 0 4095;
BA_DEF_ BO_ "GenMsgCycleTime" INT 0 65535;
BA_DEF_ BO_ "GenMsgCycleTimeFast" INT 0 65535;
BA_DEF_ BO_ "GenMsgDelayTime" INT 0 100000;
BA_DEF_ BO_ "GenMsgILSupport" ENUM "No", "Yes";
BA_DEF_ BO_ "GenMsgNrOfRepetition" INT 0 100;
BA_DEF_ BO_ "GenMsgPDUConstants" STRING;
BA_DEF_ BO_ "GenMsgSendType" ENUM "Cyclic", "not_used", "not_used", "not_used", "not_used", "not_used", "not_used", "IfActive", "NoMsgSendType";
BA_DEF_ BO_ "GenMsgStartDelayTime" INT 0 100000;
BA_DEF_ BO_ "MsgType" ENUM "Application", "NM ", "NMH", "TP2.0", "ISO-TP ", "BAP", "EID", "KS", "XCP_PRE_CONFIGURED", "XCP_RUNTIME_CONFIGURED";
BA_DEF_ BO_ "NmMessage" ENUM "No", "Yes";
BA_DEF_ BO_ "NmhMessage" ENUM "No", "Yes";
BA_DEF_ BO_ "VAGTP20_API" HEX 0 255;
BA_DEF_ BO_ "VAGTP20_DynConnection" ENUM "No", "Yes";
BA_DEF_ BO_ "VAGTP20_DynSetup" ENUM "No", "Yes";
BA_DEF_ BO_ "VAGTP20_StatConnection" ENUM "No", "Yes";
BA_DEF_ BO_ "VFrameFormat" ENUM "StandardCAN", "ExtendedCAN", "reserved", "reserved", "reserved", "reserved", "reserved", "reserved", "reserved", "reserved", "reserved", "reserved", "reserved", "reserved", "StandardCAN_FD", "ExtendedCAN_FD";
BA_DEF_ SG_ "Fehlerwert" HEX 0 2147483647;
BA_DEF_ SG_ "GenSigActiveRepetitions" INT -2147483648 2147483647;
BA_DEF_ SG_ "GenSigFuncType" ENUM "NoFunction", "MsgCounter", "CRC-8", "XOR", "XOR-2", "DatedBit", "SW-Kl15", "CHK", "Constant", "Protocol", "CRC-8-SAE_J1850", "CRC-32", "DataLength", "DataID", "MsgCounter16", "SOK-Signatur", "Cluster";
BA_DEF_ SG_ "GenSigInactiveValue" INT -2147483648 2147483647;
BA_DEF_ SG_ "GenSigMissingSourceValue" HEX 0 2147483647;
BA_DEF_ SG_ "GenSigSendType" ENUM "Cyclic", "OnWrite", "OnWriteWithRepetition", "OnChange", "OnChangeWithRepetition", "IfActive", "IfActiveWithRepetition", "NoSigSendType", "OnChangeAndIfActive", "OnChangeAndIfActiveWithRepetition";
BA_DEF_ SG_ "GenSigStartValue" INT -2147483648 2147483647;
BA_DEF_ SG_ "GenSigSwitchedByIgnition" ENUM "No", "Yes";
BA_DEF_ SG_ "NWM-WakeupAllowed" ENUM "No", "Yes";

BA_DEF_REL_ BU_SG_REL_ "GenSigTimeoutTime" INT 0 65535;
BA_DEF_DEF_ "CANFD_BRS" "1";
BA_DEF_DEF_ "DiagRequest" "No";
BA_DEF_DEF_ "DiagResponse" "No";
BA_DEF_DEF_ "DiagState" "No";
BA_DEF_DEF_ "Fehlerwert" 0;
BA_DEF_DEF_ "GenMsgChkConstant" 0;
BA_DEF_DEF_ "GenMsgCycleTime" 0;
BA_DEF_DEF_ "GenMsgCycleTimeFast" 0;
BA_DEF_DEF_ "GenMsgDelayTime" 0;
BA_DEF_DEF_ "GenMsgILSupport" "No";
BA_DEF_DEF_ "GenMsgNrOfRepetition" 0;
BA_DEF_DEF_ "GenMsgPDUConstants" "";
BA_DEF_DEF_ "GenMsgSendType" "NoMsgSendType";
BA_DEF_DEF_ "GenMsgStartDelayTime" 0;
BA_DEF_DEF_ "GenSigActiveRepetitions" 0;
BA_DEF_DEF_ "GenSigFuncType" "NoFunction";
BA_DEF_DEF_ "GenSigInactiveValue" 0;
BA_DEF_DEF_ "GenSigMissingSourceValue" 0;
BA_DEF_DEF_ "GenSigSendType" "NoSigSendType";
BA_DEF_DEF_ "GenSigStartValue" 0;
BA_DEF_DEF_ "GenSigSwitchedByIgnition" "Yes";
BA_DEF_DEF_ "MsgType" "Application";
BA_DEF_DEF_ "NWM-WakeupAllowed" "No";
BA_DEF_DEF_ "NmMessage" "No";
BA_DEF_DEF_ "NmhMessage" "No";
BA_DEF_DEF_ "VAGTP20_API" 0;
BA_DEF_DEF_ "VAGTP20_DynConnection" "No";
BA_DEF_DEF_ "VAGTP20_DynSetup" "No";
BA_DEF_DEF_ "VAGTP20_StatConnection" "No";
BA_DEF_DEF_ "VFrameFormat" "StandardCAN";
BA_DEF_DEF_REL_ "GenSigTimeoutTime" 0;
BA_ "GenMsgDelayTime" BO_ 2463978804 20;
BA_ "GenMsgILSupport" BO_ 2463978804 1;
BA_ "VFrameFormat" BO_ 2463978804 15;
BA_ "GenMsgDelayTime" BO_ 2463978800 20;
BA_ "GenMsgILSupport" BO_ 2463978800 1;
BA_ "VFrameFormat" BO_ 2463978800 15;
BA_ "GenMsgDelayTime" BO_ 2463978801 20;
BA_ "GenMsgILSupport" BO_ 2463978801 1;
BA_ "VFrameFormat" BO_ 2463978801 15;
BA_ "GenMsgDelayTime" BO_ 2463978802 20;
BA_ "GenMsgILSupport" BO_ 2463978802 1;
BA_ "VFrameFormat" BO_ 2463978802 15;
BA_ "GenMsgDelayTime" BO_ 2463978803 20;
BA_ "GenMsgILSupport" BO_ 2463978803 1;
BA_ "VFrameFormat" BO_ 2463978803 15;
BA_ "GenMsgDelayTime" BO_ 2463978806 20;
BA_ "GenMsgILSupport" BO_ 2463978806 1;
BA_ "VFrameFormat" BO_ 2463978806 15;
BA_ "GenMsgCycleTime" BO_ 2463978805 1000;
BA_ "GenMsgDelayTime" BO_ 2463978805 20;
BA_ "GenMsgILSupport" BO_ 2463978805 1;
BA_ "GenMsgSendType" BO_ 2463978805 0;
BA_ "VFrameFormat" BO_ 2463978805 15;
BA_ "GenMsgCycleTime" BO_ 980 1000;
BA_ "GenMsgCycleTimeFast" BO_ 980 100;
BA_ "GenMsgDelayTime" BO_ 980 50;
BA_ "GenMsgILSupport" BO_ 980 1;
BA_ "GenMsgNrOfRepetition" BO_ 980 5;
BA_ "GenMsgPDUConstants" BO_ 980 "0xc3,0x79,0xbf,0xdb,0xe9,0x11,0x46,0x86,0x69,0xb6,0x9b,0x29,0x15,0x9c,0x45,0x0d";
BA_ "GenMsgSendType" BO_ 980 0;
BA_ "VFrameFormat" BO_ 980 14;
BA_ "GenMsgSendType" BO_ 2536271618 7;
BA_ "MsgType" BO_ 2536271618 5;
BA_ "VFrameFormat" BO_ 2536271618 15;
BA_ "GenMsgSendType" BO_ 2536271634 7;
BA_ "MsgType" BO_ 2536271634 5;
BA_ "VFrameFormat" BO_ 2536271634 15;
BA_ "GenMsgILSupport" BO_ 2464161907 1;
BA_ "VFrameFormat" BO_ 2464161907 15;
BA_ "GenMsgILSupport" BO_ 2464301171 1;
BA_ "VFrameFormat" BO_ 2464301171 15;
BA_ "GenMsgCycleTime" BO_ 2589283756 1000;
BA_ "GenMsgDelayTime" BO_ 2589283756 100;
BA_ "GenMsgILSupport" BO_ 2589283756 1;
BA_ "GenMsgSendType" BO_ 2589283756 0;
BA_ "VFrameFormat" BO_ 2589283756 15;
BA_ "GenMsgDelayTime" BO_ 2464153715 100;
BA_ "GenMsgILSupport" BO_ 2464153715 1;
BA_ "VFrameFormat" BO_ 2464153715 15;
BA_ "GenMsgDelayTime" BO_ 2464284787 100;
BA_ "GenMsgILSupport" BO_ 2464284787 1;
BA_ "VFrameFormat" BO_ 2464284787 15;
BA_ "DiagState" BO_ 2464153620 1;
BA_ "GenMsgDelayTime" BO_ 2464153620 100;
BA_ "GenMsgILSupport" BO_ 2464153620 1;
BA_ "VFrameFormat" BO_ 2464153620 15;
BA_ "GenMsgDelayTime" BO_ 2464284692 100;
BA_ "GenMsgILSupport" BO_ 2464284692 1;
BA_ "VFrameFormat" BO_ 2464284692 15;
BA_ "GenMsgDelayTime" BO_ 2464288788 100;
BA_ "GenMsgILSupport" BO_ 2464288788 1;
BA_ "VFrameFormat" BO_ 2464288788 15;
BA_ "GenMsgCycleTime" BO_ 2527679739 500;
BA_ "GenMsgDelayTime" BO_ 2527679739 50;
BA_ "GenMsgILSupport" BO_ 2527679739 1;
BA_ "GenMsgSendType" BO_ 2527679739 0;
BA_ "VFrameFormat" BO_ 2527679739 15;
BA_ "GenMsgCycleTime" BO_ 1413 1000;
BA_ "GenMsgDelayTime" BO_ 1413 10;
BA_ "GenMsgILSupport" BO_ 1413 1;
BA_ "GenMsgSendType" BO_ 1413 0;
BA_ "VFrameFormat" BO_ 1413 14;
BA_ "GenMsgCycleTime" BO_ 2589283775 1000;
BA_ "GenMsgDelayTime" BO_ 2589283775 40;
BA_ "GenMsgILSupport" BO_ 2589283775 1;
BA_ "GenMsgSendType" BO_ 2589283775 0;
BA_ "VFrameFormat" BO_ 2589283775 15;
BA_ "GenMsgCycleTime" BO_ 2589283947 1000;
BA_ "GenMsgDelayTime" BO_ 2589283947 40;
BA_ "GenMsgILSupport" BO_ 2589283947 1;
BA_ "GenMsgSendType" BO_ 2589283947 0;
BA_ "VFrameFormat" BO_ 2589283947 15;
BA_ "GenMsgCycleTime" BO_ 619 100;
BA_ "GenMsgDelayTime" BO_ 619 20;
BA_ "GenMsgILSupport" BO_ 619 1;
BA_ "GenMsgPDUConstants" BO_ 619 "0xce,0xcc,0xbd,0x69,0xa1,0x3c,0x18,0x76,0x0f,0x04,0xf2,0x3a,0x93,0x24,0x19,0x51";
BA_ "GenMsgSendType" BO_ 619 0;
BA_ "VFrameFormat" BO_ 619 14;
BA_ "GenMsgCycleTime" BO_ 1637 1000;
BA_ "GenMsgDelayTime" BO_ 1637 100;
BA_ "GenMsgILSupport" BO_ 1637 1;
BA_ "GenMsgSendType" BO_ 1637 0;
BA_ "VFrameFormat" BO_ 1637 14;
BA_ "GenMsgCycleTime" BO_ 2589283750 1000;
BA_ "GenMsgILSupport" BO_ 2589283750 1;
BA_ "GenMsgSendType" BO_ 2589283750 0;
BA_ "VFrameFormat" BO_ 2589283750 15;
BA_ "GenMsgCycleTime" BO_ 1001 100;
BA_ "GenMsgILSupport" BO_ 1001 1;
BA_ "GenMsgSendType" BO_ 1001 0;
BA_ "VFrameFormat" BO_ 1001 14;
BA_ "GenMsgCycleTime" BO_ 1447 1000;
BA_ "GenMsgCycleTimeFast" BO_ 1447 100;
BA_ "GenMsgDelayTime" BO_ 1447 50;
BA_ "GenMsgILSupport" BO_ 1447 1;
BA_ "GenMsgSendType" BO_ 1447 0;
BA_ "VFrameFormat" BO_ 1447 14;
BA_ "GenMsgCycleTime" BO_ 977 100;
BA_ "GenMsgDelayTime" BO_ 977 20;
BA_ "GenMsgILSupport" BO_ 977 1;
BA_ "GenMsgSendType" BO_ 977 0;
BA_ "VFrameFormat" BO_ 977 14;
BA_ "GenMsgCycleTime" BO_ 976 100;
BA_ "GenMsgDelayTime" BO_ 976 20;
BA_ "GenMsgILSupport" BO_ 976 1;
BA_ "GenMsgSendType" BO_ 976 0;
BA_ "VFrameFormat" BO_ 976 14;
BA_ "GenMsgCycleTime" BO_ 997 100;
BA_ "GenMsgDelayTime" BO_ 997 20;
BA_ "GenMsgILSupport" BO_ 997 1;
BA_ "GenMsgPDUConstants" BO_ 997 "0xc4,0x6a,0x69,0x30,0xcf,0x61,0x58,0x51,0x1b,0x86,0x99,0xd3,0xf6,0x1d,0x9a,0x37";
BA_ "GenMsgSendType" BO_ 997 0;
BA_ "VFrameFormat" BO_ 997 14;
BA_ "GenSigSendType" SG_ 2463978804 SmaLi_brightness 3;
BA_ "GenSigSwitchedByIgnition" SG_ 2463978804 SmaLi_brightness 0;
BA_ "GenSigSendType" SG_ 2463978804 SmaLi_Checksum 3;
BA_ "GenSigSwitchedByIgnition" SG_ 2463978804 SmaLi_Checksum 0;
BA_ "GenSigSendType" SG_ 2463978804 SmaLi_Cnt_05 3;
BA_ "GenSigSwitchedByIgnition" SG_ 2463978804 SmaLi_Cnt_05 0;
BA_ "GenSigSendType" SG_ 2463978804 SmaLi_CtrlCmd_01 3;
BA_ "GenSigSwitchedByIgnition" SG_ 2463978804 SmaLi_CtrlCmd_01 0;
BA_ "GenSigSendType" SG_ 2463978804 SmaLi_Loops 3;
BA_ "GenSigSwitchedByIgnition" SG_ 2463978804 SmaLi_Loops 0;
BA_ "GenSigSendType" SG_ 2463978804 SmaLi_MovieBundleVersion 3;
BA_ "GenSigSwitchedByIgnition" SG_ 2463978804 SmaLi_MovieBundleVersion 0;
BA_ "GenSigSendType" SG_ 2463978804 SmaLi_MovieID 3;
BA_ "GenSigSwitchedByIgnition" SG_ 2463978804 SmaLi_MovieID 0;
BA_ "GenSigSendType" SG_ 2463978804 SmaLi_SlotID_05 3;
BA_ "GenSigSwitchedByIgnition" SG_ 2463978804 SmaLi_SlotID_05 0;
BA_ "GenSigSendType" SG_ 2463978800 SmaLi_Cnt_01 3;
BA_ "GenSigSwitchedByIgnition" SG_ 2463978800 SmaLi_Cnt_01 0;
BA_ "GenSigSendType" SG_ 2463978800 SmaLi_ColorValue_01 3;
BA_ "GenSigSwitchedByIgnition" SG_ 2463978800 SmaLi_ColorValue_01 0;
BA_ "GenSigSendType" SG_ 2463978800 SmaLi_ColorValue_02 3;
BA_ "GenSigSwitchedByIgnition" SG_ 2463978800 SmaLi_ColorValue_02 0;
BA_ "GenSigSendType" SG_ 2463978800 SmaLi_ColorValue_03 3;
BA_ "GenSigSwitchedByIgnition" SG_ 2463978800 SmaLi_ColorValue_03 0;
BA_ "GenSigSendType" SG_ 2463978800 SmaLi_ColorValue_04 3;
BA_ "GenSigSwitchedByIgnition" SG_ 2463978800 SmaLi_ColorValue_04 0;
BA_ "GenSigSendType" SG_ 2463978800 SmaLi_ColorValue_05 3;
BA_ "GenSigSwitchedByIgnition" SG_ 2463978800 SmaLi_ColorValue_05 0;
BA_ "GenSigSendType" SG_ 2463978800 SmaLi_ColorValue_06 3;
BA_ "GenSigSwitchedByIgnition" SG_ 2463978800 SmaLi_ColorValue_06 0;
BA_ "GenSigSendType" SG_ 2463978800 SmaLi_ColorValue_07 3;
BA_ "GenSigSwitchedByIgnition" SG_ 2463978800 SmaLi_ColorValue_07 0;
BA_ "GenSigSendType" SG_ 2463978800 SmaLi_ColorValue_08 3;
BA_ "GenSigSwitchedByIgnition" SG_ 2463978800 SmaLi_ColorValue_08 0;
BA_ "GenSigSendType" SG_ 2463978800 SmaLi_ColorValue_09 3;
BA_ "GenSigSwitchedByIgnition" SG_ 2463978800 SmaLi_ColorValue_09 0;
BA_ "GenSigSendType" SG_ 2463978800 SmaLi_ColorValue_10 3;
BA_ "GenSigSwitchedByIgnition" SG_ 2463978800 SmaLi_ColorValue_10 0;
BA_ "GenSigSendType" SG_ 2463978800 SmaLi_ColorValue_11 3;
BA_ "GenSigSwitchedByIgnition" SG_ 2463978800 SmaLi_ColorValue_11 0;
BA_ "GenSigSendType" SG_ 2463978800 SmaLi_ColorValue_12 3;
BA_ "GenSigSwitchedByIgnition" SG_ 2463978800 SmaLi_ColorValue_12 0;
BA_ "GenSigSendType" SG_ 2463978800 SmaLi_ColorValue_13 3;
BA_ "GenSigSwitchedByIgnition" SG_ 2463978800 SmaLi_ColorValue_13 0;
BA_ "GenSigSendType" SG_ 2463978800 SmaLi_ColorValue_14 3;
BA_ "GenSigSwitchedByIgnition" SG_ 2463978800 SmaLi_ColorValue_14 0;
BA_ "GenSigSendType" SG_ 2463978800 SmaLi_FrameCmd_01 3;
BA_ "GenSigSwitchedByIgnition" SG_ 2463978800 SmaLi_FrameCmd_01 0;
BA_ "GenSigSendType" SG_ 2463978800 SmaLi_length 3;
BA_ "GenSigSwitchedByIgnition" SG_ 2463978800 SmaLi_length 0;
BA_ "GenSigSendType" SG_ 2463978800 SmaLi_SlotID_01 3;
BA_ "GenSigSwitchedByIgnition" SG_ 2463978800 SmaLi_SlotID_01 0;
BA_ "GenSigSendType" SG_ 2463978800 SmaLi_StartIndex 3;
BA_ "GenSigSwitchedByIgnition" SG_ 2463978800 SmaLi_StartIndex 0;
BA_ "GenSigSendType" SG_ 2463978801 SmaLi_Cnt_02 3;
BA_ "GenSigSwitchedByIgnition" SG_ 2463978801 SmaLi_Cnt_02 0;
BA_ "GenSigSendType" SG_ 2463978801 SmaLi_ColorValue_15 3;
BA_ "GenSigSwitchedByIgnition" SG_ 2463978801 SmaLi_ColorValue_15 0;
BA_ "GenSigSendType" SG_ 2463978801 SmaLi_ColorValue_16 3;
BA_ "GenSigSwitchedByIgnition" SG_ 2463978801 SmaLi_ColorValue_16 0;
BA_ "GenSigSendType" SG_ 2463978801 SmaLi_ColorValue_17 3;
BA_ "GenSigSwitchedByIgnition" SG_ 2463978801 SmaLi_ColorValue_17 0;
BA_ "GenSigSendType" SG_ 2463978801 SmaLi_ColorValue_18 3;
BA_ "GenSigSwitchedByIgnition" SG_ 2463978801 SmaLi_ColorValue_18 0;
BA_ "GenSigSendType" SG_ 2463978801 SmaLi_ColorValue_19 3;
BA_ "GenSigSwitchedByIgnition" SG_ 2463978801 SmaLi_ColorValue_19 0;
BA_ "GenSigSendType" SG_ 2463978801 SmaLi_ColorValue_20 3;
BA_ "GenSigSwitchedByIgnition" SG_ 2463978801 SmaLi_ColorValue_20 0;
BA_ "GenSigSendType" SG_ 2463978801 SmaLi_ColorValue_21 3;
BA_ "GenSigSwitchedByIgnition" SG_ 2463978801 SmaLi_ColorValue_21 0;
BA_ "GenSigSendType" SG_ 2463978801 SmaLi_ColorValue_22 3;
BA_ "GenSigSwitchedByIgnition" SG_ 2463978801 SmaLi_ColorValue_22 0;
BA_ "GenSigSendType" SG_ 2463978801 SmaLi_ColorValue_23 3;
BA_ "GenSigSwitchedByIgnition" SG_ 2463978801 SmaLi_ColorValue_23 0;
BA_ "GenSigSendType" SG_ 2463978801 SmaLi_ColorValue_24 3;
BA_ "GenSigSwitchedByIgnition" SG_ 2463978801 SmaLi_ColorValue_24 0;
BA_ "GenSigSendType" SG_ 2463978801 SmaLi_ColorValue_25 3;
BA_ "GenSigSwitchedByIgnition" SG_ 2463978801 SmaLi_ColorValue_25 0;
BA_ "GenSigSendType" SG_ 2463978801 SmaLi_ColorValue_26 3;
BA_ "GenSigSwitchedByIgnition" SG_ 2463978801 SmaLi_ColorValue_26 0;
BA_ "GenSigSendType" SG_ 2463978801 SmaLi_ColorValue_27 3;
BA_ "GenSigSwitchedByIgnition" SG_ 2463978801 SmaLi_ColorValue_27 0;
BA_ "GenSigSendType" SG_ 2463978801 SmaLi_ColorValue_28 3;
BA_ "GenSigSwitchedByIgnition" SG_ 2463978801 SmaLi_ColorValue_28 0;
BA_ "GenSigSendType" SG_ 2463978801 SmaLi_ColorValue_29 3;
BA_ "GenSigSwitchedByIgnition" SG_ 2463978801 SmaLi_ColorValue_29 0;
BA_ "GenSigSendType" SG_ 2463978801 SmaLi_FrameCmd_02 3;
BA_ "GenSigSwitchedByIgnition" SG_ 2463978801 SmaLi_FrameCmd_02 0;
BA_ "GenSigSendType" SG_ 2463978801 SmaLi_SlotID_02 3;
BA_ "GenSigSwitchedByIgnition" SG_ 2463978801 SmaLi_SlotID_02 0;
BA_ "GenSigSendType" SG_ 2463978802 SmaLi_Cnt_03 3;
BA_ "GenSigSwitchedByIgnition" SG_ 2463978802 SmaLi_Cnt_03 0;
BA_ "GenSigSendType" SG_ 2463978802 SmaLi_ColorValue_30 3;
BA_ "GenSigSwitchedByIgnition" SG_ 2463978802 SmaLi_ColorValue_30 0;
BA_ "GenSigSendType" SG_ 2463978802 SmaLi_ColorValue_31 3;
BA_ "GenSigSwitchedByIgnition" SG_ 2463978802 SmaLi_ColorValue_31 0;
BA_ "GenSigSendType" SG_ 2463978802 SmaLi_ColorValue_32 3;
BA_ "GenSigSwitchedByIgnition" SG_ 2463978802 SmaLi_ColorValue_32 0;
BA_ "GenSigSendType" SG_ 2463978802 SmaLi_ColorValue_33 3;
BA_ "GenSigSwitchedByIgnition" SG_ 2463978802 SmaLi_ColorValue_33 0;
BA_ "GenSigSendType" SG_ 2463978802 SmaLi_ColorValue_34 3;
BA_ "GenSigSwitchedByIgnition" SG_ 2463978802 SmaLi_ColorValue_34 0;
BA_ "GenSigSendType" SG_ 2463978802 SmaLi_ColorValue_35 3;
BA_ "GenSigSwitchedByIgnition" SG_ 2463978802 SmaLi_ColorValue_35 0;
BA_ "GenSigSendType" SG_ 2463978802 SmaLi_ColorValue_36 3;
BA_ "GenSigSwitchedByIgnition" SG_ 2463978802 SmaLi_ColorValue_36 0;
BA_ "GenSigSendType" SG_ 2463978802 SmaLi_ColorValue_37 3;
BA_ "GenSigSwitchedByIgnition" SG_ 2463978802 SmaLi_ColorValue_37 0;
BA_ "GenSigSendType" SG_ 2463978802 SmaLi_ColorValue_38 3;
BA_ "GenSigSwitchedByIgnition" SG_ 2463978802 SmaLi_ColorValue_38 0;
BA_ "GenSigSendType" SG_ 2463978802 SmaLi_ColorValue_39 3;
BA_ "GenSigSwitchedByIgnition" SG_ 2463978802 SmaLi_ColorValue_39 0;
BA_ "GenSigSendType" SG_ 2463978802 SmaLi_ColorValue_40 3;
BA_ "GenSigSwitchedByIgnition" SG_ 2463978802 SmaLi_ColorValue_40 0;
BA_ "GenSigSendType" SG_ 2463978802 SmaLi_ColorValue_41 3;
BA_ "GenSigSwitchedByIgnition" SG_ 2463978802 SmaLi_ColorValue_41 0;
BA_ "GenSigSendType" SG_ 2463978802 SmaLi_ColorValue_42 3;
BA_ "GenSigSwitchedByIgnition" SG_ 2463978802 SmaLi_ColorValue_42 0;
BA_ "GenSigSendType" SG_ 2463978802 SmaLi_ColorValue_43 3;
BA_ "GenSigSwitchedByIgnition" SG_ 2463978802 SmaLi_ColorValue_43 0;
BA_ "GenSigSendType" SG_ 2463978802 SmaLi_ColorValue_44 3;
BA_ "GenSigSwitchedByIgnition" SG_ 2463978802 SmaLi_ColorValue_44 0;
BA_ "GenSigSendType" SG_ 2463978802 SmaLi_FrameCmd_03 3;
BA_ "GenSigSwitchedByIgnition" SG_ 2463978802 SmaLi_FrameCmd_03 0;
BA_ "GenSigSendType" SG_ 2463978802 SmaLi_SlotID_03 3;
BA_ "GenSigSwitchedByIgnition" SG_ 2463978802 SmaLi_SlotID_03 0;
BA_ "GenSigSendType" SG_ 2463978803 SmaLi_Cnt_04 3;
BA_ "GenSigSwitchedByIgnition" SG_ 2463978803 SmaLi_Cnt_04 0;
BA_ "GenSigSendType" SG_ 2463978803 SmaLi_ColorValue_45 3;
BA_ "GenSigSwitchedByIgnition" SG_ 2463978803 SmaLi_ColorValue_45 0;
BA_ "GenSigSendType" SG_ 2463978803 SmaLi_ColorValue_46 3;
BA_ "GenSigSwitchedByIgnition" SG_ 2463978803 SmaLi_ColorValue_46 0;
BA_ "GenSigSendType" SG_ 2463978803 SmaLi_ColorValue_47 3;
BA_ "GenSigSwitchedByIgnition" SG_ 2463978803 SmaLi_ColorValue_47 0;
BA_ "GenSigSendType" SG_ 2463978803 SmaLi_ColorValue_48 3;
BA_ "GenSigSwitchedByIgnition" SG_ 2463978803 SmaLi_ColorValue_48 0;
BA_ "GenSigSendType" SG_ 2463978803 SmaLi_ColorValue_49 3;
BA_ "GenSigSwitchedByIgnition" SG_ 2463978803 SmaLi_ColorValue_49 0;
BA_ "GenSigSendType" SG_ 2463978803 SmaLi_ColorValue_50 3;
BA_ "GenSigSwitchedByIgnition" SG_ 2463978803 SmaLi_ColorValue_50 0;
BA_ "GenSigSendType" SG_ 2463978803 SmaLi_ColorValue_51 3;
BA_ "GenSigSwitchedByIgnition" SG_ 2463978803 SmaLi_ColorValue_51 0;
BA_ "GenSigSendType" SG_ 2463978803 SmaLi_ColorValue_52 3;
BA_ "GenSigSwitchedByIgnition" SG_ 2463978803 SmaLi_ColorValue_52 0;
BA_ "GenSigSendType" SG_ 2463978803 SmaLi_ColorValue_53 3;
BA_ "GenSigSwitchedByIgnition" SG_ 2463978803 SmaLi_ColorValue_53 0;
BA_ "GenSigSendType" SG_ 2463978803 SmaLi_ColorValue_54 3;
BA_ "GenSigSwitchedByIgnition" SG_ 2463978803 SmaLi_ColorValue_54 0;
BA_ "GenSigSendType" SG_ 2463978803 SmaLi_ColorValue_55 3;
BA_ "GenSigSwitchedByIgnition" SG_ 2463978803 SmaLi_ColorValue_55 0;
BA_ "GenSigSendType" SG_ 2463978803 SmaLi_ColorValue_56 3;
BA_ "GenSigSwitchedByIgnition" SG_ 2463978803 SmaLi_ColorValue_56 0;
BA_ "GenSigSendType" SG_ 2463978803 SmaLi_ColorValue_57 3;
BA_ "GenSigSwitchedByIgnition" SG_ 2463978803 SmaLi_ColorValue_57 0;
BA_ "GenSigSendType" SG_ 2463978803 SmaLi_ColorValue_58 3;
BA_ "GenSigSwitchedByIgnition" SG_ 2463978803 SmaLi_ColorValue_58 0;
BA_ "GenSigSendType" SG_ 2463978803 SmaLi_ColorValue_59 3;
BA_ "GenSigSwitchedByIgnition" SG_ 2463978803 SmaLi_ColorValue_59 0;
BA_ "GenSigSendType" SG_ 2463978803 SmaLi_FrameCmd_04 3;
BA_ "GenSigSwitchedByIgnition" SG_ 2463978803 SmaLi_FrameCmd_04 0;
BA_ "GenSigSendType" SG_ 2463978803 SmaLi_SlotID_04 3;
BA_ "GenSigSwitchedByIgnition" SG_ 2463978803 SmaLi_SlotID_04 0;
BA_ "GenSigSendType" SG_ 2463978806 SmaLi_Cnt_07 3;
BA_ "GenSigSwitchedByIgnition" SG_ 2463978806 SmaLi_Cnt_07 0;
BA_ "GenSigSendType" SG_ 2463978806 SmaLi_ColorValue_60 3;
BA_ "GenSigSwitchedByIgnition" SG_ 2463978806 SmaLi_ColorValue_60 0;
BA_ "GenSigSendType" SG_ 2463978806 SmaLi_ColorValue_61 3;
BA_ "GenSigSwitchedByIgnition" SG_ 2463978806 SmaLi_ColorValue_61 0;
BA_ "GenSigSendType" SG_ 2463978806 SmaLi_ColorValue_62 3;
BA_ "GenSigSwitchedByIgnition" SG_ 2463978806 SmaLi_ColorValue_62 0;
BA_ "GenSigSendType" SG_ 2463978806 SmaLi_ColorValue_63 3;
BA_ "GenSigSwitchedByIgnition" SG_ 2463978806 SmaLi_ColorValue_63 0;
BA_ "GenSigSendType" SG_ 2463978806 SmaLi_ColorValue_64 3;
BA_ "GenSigSwitchedByIgnition" SG_ 2463978806 SmaLi_ColorValue_64 0;
BA_ "GenSigSendType" SG_ 2463978806 SmaLi_ColorValue_65 3;
BA_ "GenSigSwitchedByIgnition" SG_ 2463978806 SmaLi_ColorValue_65 0;
BA_ "GenSigSendType" SG_ 2463978806 SmaLi_ColorValue_66 3;
BA_ "GenSigSwitchedByIgnition" SG_ 2463978806 SmaLi_ColorValue_66 0;
BA_ "GenSigSendType" SG_ 2463978806 SmaLi_ColorValue_67 3;
BA_ "GenSigSwitchedByIgnition" SG_ 2463978806 SmaLi_ColorValue_67 0;
BA_ "GenSigSendType" SG_ 2463978806 SmaLi_ColorValue_68 3;
BA_ "GenSigSwitchedByIgnition" SG_ 2463978806 SmaLi_ColorValue_68 0;
BA_ "GenSigSendType" SG_ 2463978806 SmaLi_ColorValue_69 3;
BA_ "GenSigSwitchedByIgnition" SG_ 2463978806 SmaLi_ColorValue_69 0;
BA_ "GenSigSendType" SG_ 2463978806 SmaLi_ColorValue_70 3;
BA_ "GenSigSwitchedByIgnition" SG_ 2463978806 SmaLi_ColorValue_70 0;
BA_ "GenSigSendType" SG_ 2463978806 SmaLi_ColorValue_71 3;
BA_ "GenSigSwitchedByIgnition" SG_ 2463978806 SmaLi_ColorValue_71 0;
BA_ "GenSigSendType" SG_ 2463978806 SmaLi_ColorValue_72 3;
BA_ "GenSigSwitchedByIgnition" SG_ 2463978806 SmaLi_ColorValue_72 0;
BA_ "GenSigSendType" SG_ 2463978806 SmaLi_ColorValue_73 3;
BA_ "GenSigSwitchedByIgnition" SG_ 2463978806 SmaLi_ColorValue_73 0;
BA_ "GenSigSendType" SG_ 2463978806 SmaLi_ColorValue_74 3;
BA_ "GenSigSwitchedByIgnition" SG_ 2463978806 SmaLi_ColorValue_74 0;
BA_ "GenSigSendType" SG_ 2463978806 SmaLi_FrameCmd_05 3;
BA_ "GenSigSwitchedByIgnition" SG_ 2463978806 SmaLi_FrameCmd_05 0;
BA_ "GenSigSendType" SG_ 2463978806 SmaLi_SlotID_07 3;
BA_ "GenSigSwitchedByIgnition" SG_ 2463978806 SmaLi_SlotID_07 0;
BA_ "GenSigSendType" SG_ 2463978805 SmaLi_AppSwVersion 3;
BA_ "GenSigSwitchedByIgnition" SG_ 2463978805 SmaLi_AppSwVersion 0;
BA_ "GenSigSendType" SG_ 2463978805 SmaLi_availMemory 3;
BA_ "GenSigSwitchedByIgnition" SG_ 2463978805 SmaLi_availMemory 0;
BA_ "GenSigSendType" SG_ 2463978805 SmaLi_Cnt_06 3;
BA_ "GenSigSwitchedByIgnition" SG_ 2463978805 SmaLi_Cnt_06 0;
BA_ "GenSigSendType" SG_ 2463978805 SmaLi_CtrlCmdRsp_01 3;
BA_ "GenSigSwitchedByIgnition" SG_ 2463978805 SmaLi_CtrlCmdRsp_01 0;
BA_ "GenSigSendType" SG_ 2463978805 SmaLi_error_cause 3;
BA_ "GenSigSwitchedByIgnition" SG_ 2463978805 SmaLi_error_cause 0;
BA_ "GenSigSendType" SG_ 2463978805 SmaLi_InterfaceVersion 3;
BA_ "GenSigSwitchedByIgnition" SG_ 2463978805 SmaLi_InterfaceVersion 0;
BA_ "GenSigSendType" SG_ 2463978805 SmaLi_MovieIDRsp 3;
BA_ "GenSigSwitchedByIgnition" SG_ 2463978805 SmaLi_MovieIDRsp 0;
BA_ "GenSigSendType" SG_ 2463978805 SmaLi_numLEDs 3;
BA_ "GenSigSwitchedByIgnition" SG_ 2463978805 SmaLi_numLEDs 0;
BA_ "GenSigSendType" SG_ 2463978805 SmaLi_numOfSlots 3;
BA_ "GenSigSwitchedByIgnition" SG_ 2463978805 SmaLi_numOfSlots 0;
BA_ "GenSigSendType" SG_ 2463978805 SmaLi_SavedMovieBundleVersion 3;
BA_ "GenSigSwitchedByIgnition" SG_ 2463978805 SmaLi_SavedMovieBundleVersion 0;
BA_ "GenSigSendType" SG_ 2463978805 SmaLi_SlotID_06 3;
BA_ "GenSigSwitchedByIgnition" SG_ 2463978805 SmaLi_SlotID_06 0;
BA_ "GenSigSendType" SG_ 2463978805 SmaLi_xPosCenter 3;
BA_ "GenSigSwitchedByIgnition" SG_ 2463978805 SmaLi_xPosCenter 0;
BA_ "GenSigSendType" SG_ 2463978805 SmaLi_xPosPassengerLeft 3;
BA_ "GenSigSwitchedByIgnition" SG_ 2463978805 SmaLi_xPosPassengerLeft 0;
BA_ "GenSigSendType" SG_ 2463978805 SmaLi_xPosPassengerRight 3;
BA_ "GenSigSwitchedByIgnition" SG_ 2463978805 SmaLi_xPosPassengerRight 0;
BA_ "Fehlerwert" SG_ 980 BH_Blinker_Fehler 1;
BA_ "GenSigSendType" SG_ 980 BH_Blinker_Fehler 4;
BA_ "GenSigSwitchedByIgnition" SG_ 980 BH_Blinker_Fehler 0;
BA_ "GenSigSendType" SG_ 980 BH_Blinker_li 4;
BA_ "GenSigSwitchedByIgnition" SG_ 980 BH_Blinker_li 0;
BA_ "GenSigSendType" SG_ 980 BH_Blinker_re 4;
BA_ "GenSigSwitchedByIgnition" SG_ 980 BH_Blinker_re 0;
BA_ "GenSigSendType" SG_ 980 BH_Fernlicht 3;
BA_ "GenSigSwitchedByIgnition" SG_ 980 BH_Fernlicht 0;
BA_ "GenSigSendType" SG_ 980 BH_Lichthupe 4;
BA_ "GenSigSwitchedByIgnition" SG_ 980 BH_Lichthupe 0;
BA_ "GenSigSendType" SG_ 980 FAS_Taster 3;
BA_ "GenSigSwitchedByIgnition" SG_ 980 FAS_Taster 0;
BA_ "Fehlerwert" SG_ 980 FAS_Taster_Fehler 1;
BA_ "GenSigSendType" SG_ 980 FAS_Taster_Fehler 3;
BA_ "GenSigSwitchedByIgnition" SG_ 980 FAS_Taster_Fehler 0;
BA_ "GenSigSendType" SG_ 980 LRH_aktiv 3;
BA_ "GenSigSwitchedByIgnition" SG_ 980 LRH_aktiv 0;
BA_ "Fehlerwert" SG_ 980 LRH_On_Off 3;
BA_ "GenSigSendType" SG_ 980 LRH_On_Off 3;
BA_ "GenSigSwitchedByIgnition" SG_ 980 LRH_On_Off 0;
BA_ "GenSigSendType" SG_ 980 LSS_Tastencode 3;
BA_ "GenSigSwitchedByIgnition" SG_ 980 LSS_Tastencode 0;
BA_ "GenSigFuncType" SG_ 980 SMLS_01_BZ 1;
BA_ "GenSigSendType" SG_ 980 SMLS_01_BZ 0;
BA_ "GenSigSwitchedByIgnition" SG_ 980 SMLS_01_BZ 0;
BA_ "GenSigFuncType" SG_ 980 SMLS_01_CRC 2;
BA_ "GenSigSendType" SG_ 980 SMLS_01_CRC 0;
BA_ "GenSigSwitchedByIgnition" SG_ 980 SMLS_01_CRC 0;
BA_ "GenSigSendType" SG_ 980 SMLS_Hupe 4;
BA_ "GenSigSwitchedByIgnition" SG_ 980 SMLS_Hupe 0;
BA_ "Fehlerwert" SG_ 980 SMLS_P_verriegelt 3;
BA_ "GenSigSendType" SG_ 980 SMLS_P_verriegelt 4;
BA_ "GenSigSwitchedByIgnition" SG_ 980 SMLS_P_verriegelt 0;
BA_ "GenSigSendType" SG_ 980 SMLS_P_verriegelt_plausibel 3;
BA_ "GenSigSwitchedByIgnition" SG_ 980 SMLS_P_verriegelt_plausibel 0;
BA_ "GenSigSendType" SG_ 980 SMLS_PTT 4;
BA_ "GenSigSendType" SG_ 980 WH_Frontwaschen 3;
BA_ "GenSigSwitchedByIgnition" SG_ 980 WH_Frontwaschen 0;
BA_ "GenSigSendType" SG_ 980 WH_Heckintervall 3;
BA_ "GenSigSwitchedByIgnition" SG_ 980 WH_Heckintervall 0;
BA_ "GenSigSendType" SG_ 980 WH_Heckwaschen 3;
BA_ "GenSigSwitchedByIgnition" SG_ 980 WH_Heckwaschen 0;
BA_ "GenSigSendType" SG_ 980 WH_Intervall 3;
BA_ "GenSigSwitchedByIgnition" SG_ 980 WH_Intervall 0;
BA_ "Fehlerwert" SG_ 980 WH_Intervallstufen 15;
BA_ "GenSigMissingSourceValue" SG_ 980 WH_Intervallstufen 15;
BA_ "GenSigSendType" SG_ 980 WH_Intervallstufen 3;
BA_ "GenSigSwitchedByIgnition" SG_ 980 WH_Intervallstufen 0;
BA_ "GenSigSendType" SG_ 980 WH_SRA 3;
BA_ "GenSigSwitchedByIgnition" SG_ 980 WH_SRA 0;
BA_ "GenSigSendType" SG_ 980 WH_Tipwischen 4;
BA_ "GenSigSwitchedByIgnition" SG_ 980 WH_Tipwischen 0;
BA_ "GenSigSendType" SG_ 980 WH_Tipwischen_lang 4;
BA_ "GenSigSwitchedByIgnition" SG_ 980 WH_Tipwischen_lang 0;
BA_ "Fehlerwert" SG_ 980 WH_Wischer_Fehler 1;
BA_ "GenSigSendType" SG_ 980 WH_Wischer_Fehler 3;
BA_ "GenSigSwitchedByIgnition" SG_ 980 WH_Wischer_Fehler 0;
BA_ "GenSigSendType" SG_ 980 WH_WischerStufe1 3;
BA_ "GenSigSwitchedByIgnition" SG_ 980 WH_WischerStufe1 0;
BA_ "GenSigSendType" SG_ 980 WH_WischerStufe2 3;
BA_ "GenSigSwitchedByIgnition" SG_ 980 WH_WischerStufe2 0;
BA_ "GenSigSendType" SG_ 2536271618 SOK_BAP_ENI4_ASG_03_Sig 3;
BA_ "GenSigSwitchedByIgnition" SG_ 2536271618 SOK_BAP_ENI4_ASG_03_Sig 0;
BA_ "GenSigSendType" SG_ 2536271634 SOK_BAP_ENI4_FSG_03_Sig 3;
BA_ "GenSigSwitchedByIgnition" SG_ 2536271634 SOK_BAP_ENI4_FSG_03_Sig 0;
BA_ "GenSigSendType" SG_ 2464161907 SOK_FoD_Info_El_Req_Challenge 3;
BA_ "GenSigSwitchedByIgnition" SG_ 2464161907 SOK_FoD_Info_El_Req_Challenge 0;
BA_ "GenSigSendType" SG_ 2464301171 SOK_FoD_Info_El_Resp_Challenge 3;
BA_ "GenSigSwitchedByIgnition" SG_ 2464301171 SOK_FoD_Info_El_Resp_Challenge 0;
BA_ "GenSigSendType" SG_ 2589283756 SOK_ungeschuetzte_Zeit 3;
BA_ "GenSigSwitchedByIgnition" SG_ 2589283756 SOK_ungeschuetzte_Zeit 0;
BA_ "GenSigSendType" SG_ 2464153715 SOK_Zeit_Info_El_Challenge 3;
BA_ "GenSigSwitchedByIgnition" SG_ 2464153715 SOK_Zeit_Info_El_Challenge 0;
BA_ "GenSigFuncType" SG_ 2464284787 SOK_Zeit_Info_El_Signatur 15;
BA_ "GenSigSendType" SG_ 2464284787 SOK_Zeit_Info_El_Signatur 3;
BA_ "GenSigSwitchedByIgnition" SG_ 2464284787 SOK_Zeit_Info_El_Signatur 0;
BA_ "GenSigSendType" SG_ 2464284787 SOK_Zeit_Info_El_Zeit 3;
BA_ "GenSigSwitchedByIgnition" SG_ 2464284787 SOK_Zeit_Info_El_Zeit 0;
BA_ "GenSigSendType" SG_ 2464153620 SOK_Zeit_Kombi_Challenge 3;
BA_ "GenSigSwitchedByIgnition" SG_ 2464153620 SOK_Zeit_Kombi_Challenge 0;
BA_ "GenSigFuncType" SG_ 2464284692 SOK_Zeit_Kombi_Signatur 15;
BA_ "GenSigSendType" SG_ 2464284692 SOK_Zeit_Kombi_Signatur 3;
BA_ "GenSigSwitchedByIgnition" SG_ 2464284692 SOK_Zeit_Kombi_Signatur 0;
BA_ "GenSigSendType" SG_ 2464288788 SOK_Zeit_Kombi_Zeit 3;
BA_ "GenSigSwitchedByIgnition" SG_ 2464288788 SOK_Zeit_Kombi_Zeit 0;
BA_ "GenSigSendType" SG_ 2527679739 STK_Anf_AussenspiegelHZ 0;
BA_ "GenSigSwitchedByIgnition" SG_ 2527679739 STK_Anf_AussenspiegelHZ 0;
BA_ "Fehlerwert" SG_ 2527679739 STK_Berechnungsphase 3;
BA_ "GenSigSendType" SG_ 2527679739 STK_Berechnungsphase 3;
BA_ "GenSigStartValue" SG_ 2527679739 STK_Berechnungsphase 2;
BA_ "GenSigSwitchedByIgnition" SG_ 2527679739 STK_Berechnungsphase 0;
BA_ "GenSigSendType" SG_ 2527679739 STK_Betriebsdauer 0;
BA_ "GenSigSendType" SG_ 2527679739 STK_ErwVK_Anf 3;
BA_ "GenSigSwitchedByIgnition" SG_ 2527679739 STK_ErwVK_Anf 0;
BA_ "GenSigSendType" SG_ 2527679739 STK_ErwVK_Beifahrerzone 3;
BA_ "GenSigSwitchedByIgnition" SG_ 2527679739 STK_ErwVK_Beifahrerzone 0;
BA_ "GenSigSendType" SG_ 2527679739 STK_ErwVK_Fahrerzone 3;
BA_ "GenSigSwitchedByIgnition" SG_ 2527679739 STK_ErwVK_Fahrerzone 0;
BA_ "GenSigSendType" SG_ 2527679739 STK_ErwVK_Heckzone2_links 0;
BA_ "GenSigSendType" SG_ 2527679739 STK_ErwVK_Heckzone2_rechts 0;
BA_ "GenSigSendType" SG_ 2527679739 STK_ErwVK_Heckzone_links 3;
BA_ "GenSigSwitchedByIgnition" SG_ 2527679739 STK_ErwVK_Heckzone_links 0;
BA_ "GenSigSendType" SG_ 2527679739 STK_ErwVK_Heckzone_rechts 3;
BA_ "GenSigSwitchedByIgnition" SG_ 2527679739 STK_ErwVK_Heckzone_rechts 0;
BA_ "GenSigSendType" SG_ 2527679739 STK_ErwVK_Modus 3;
BA_ "GenSigSwitchedByIgnition" SG_ 2527679739 STK_ErwVK_Modus 0;
BA_ "GenSigSendType" SG_ 2527679739 STK_ErwVK_Scheibenheizung 3;
BA_ "GenSigSwitchedByIgnition" SG_ 2527679739 STK_ErwVK_Scheibenheizung 0;
BA_ "GenSigSendType" SG_ 2527679739 STK_FSH_Anf 3;
BA_ "GenSigSwitchedByIgnition" SG_ 2527679739 STK_FSH_Anf 0;
BA_ "Fehlerwert" SG_ 2527679739 STK_GesamtEnergiebedarf 255;
BA_ "GenSigSendType" SG_ 2527679739 STK_GesamtEnergiebedarf 0;
BA_ "GenSigStartValue" SG_ 2527679739 STK_GesamtEnergiebedarf 254;
BA_ "GenSigSwitchedByIgnition" SG_ 2527679739 STK_GesamtEnergiebedarf 0;
BA_ "GenSigSendType" SG_ 2527679739 STK_HSH_Anf 3;
BA_ "GenSigSwitchedByIgnition" SG_ 2527679739 STK_HSH_Anf 0;
BA_ "Fehlerwert" SG_ 2527679739 STK_Klima_Temp 31;
BA_ "GenSigSendType" SG_ 2527679739 STK_Klima_Temp 0;
BA_ "GenSigStartValue" SG_ 2527679739 STK_Klima_Temp 30;
BA_ "GenSigSwitchedByIgnition" SG_ 2527679739 STK_Klima_Temp 0;
BA_ "GenSigSendType" SG_ 2527679739 STK_KurzVK_Anf 3;
BA_ "GenSigSwitchedByIgnition" SG_ 2527679739 STK_KurzVK_Anf 0;
BA_ "Fehlerwert" SG_ 2527679739 STK_MaxLeistung 255;
BA_ "GenSigSendType" SG_ 2527679739 STK_MaxLeistung 0;
BA_ "GenSigStartValue" SG_ 2527679739 STK_MaxLeistung 254;
BA_ "GenSigSwitchedByIgnition" SG_ 2527679739 STK_MaxLeistung 0;
BA_ "GenSigSendType" SG_ 2527679739 STK_Standklima_Anf 3;
BA_ "GenSigSwitchedByIgnition" SG_ 2527679739 STK_Standklima_Anf 0;
BA_ "GenSigSendType" SG_ 2527679739 STK_Standklima_Timer_Status 3;
BA_ "GenSigSwitchedByIgnition" SG_ 2527679739 STK_Standklima_Timer_Status 0;
BA_ "GenSigSendType" SG_ 2527679739 STK_Stecker_Status 0;
BA_ "Fehlerwert" SG_ 2527679739 STK_VK_Modus 3;
BA_ "GenSigSendType" SG_ 2527679739 STK_VK_Modus 3;
BA_ "GenSigSwitchedByIgnition" SG_ 2527679739 STK_VK_Modus 0;
BA_ "Fehlerwert" SG_ 2527679739 STK_VK_STH_Einsatz 7;
BA_ "GenSigSendType" SG_ 2527679739 STK_VK_STH_Einsatz 3;
BA_ "GenSigSwitchedByIgnition" SG_ 2527679739 STK_VK_STH_Einsatz 0;
BA_ "GenSigSendType" SG_ 2527679739 STK_VK_Timer_Status 3;
BA_ "GenSigSwitchedByIgnition" SG_ 2527679739 STK_VK_Timer_Status 0;
BA_ "GenSigSendType" SG_ 2527679739 STK_Voko_LED 3;
BA_ "GenSigSwitchedByIgnition" SG_ 2527679739 STK_Voko_LED 0;
BA_ "GenSigSendType" SG_ 1413 GW_KD_Fehler 3;
BA_ "GenSigSendType" SG_ 1413 SI_BUS_01 3;
BA_ "GenSigStartValue" SG_ 1413 SI_BUS_01 1;
BA_ "GenSigSwitchedByIgnition" SG_ 1413 SI_BUS_01 0;
BA_ "GenSigSendType" SG_ 1413 SI_BUS_02 3;
BA_ "GenSigStartValue" SG_ 1413 SI_BUS_02 1;
BA_ "GenSigSwitchedByIgnition" SG_ 1413 SI_BUS_02 0;
BA_ "GenSigSendType" SG_ 1413 SI_BUS_03 3;
BA_ "GenSigStartValue" SG_ 1413 SI_BUS_03 1;
BA_ "GenSigSwitchedByIgnition" SG_ 1413 SI_BUS_03 0;
BA_ "GenSigSendType" SG_ 1413 SI_BUS_04 3;
BA_ "GenSigStartValue" SG_ 1413 SI_BUS_04 1;
BA_ "GenSigSwitchedByIgnition" SG_ 1413 SI_BUS_04 0;
BA_ "GenSigSendType" SG_ 1413 SI_BUS_05 3;
BA_ "GenSigStartValue" SG_ 1413 SI_BUS_05 1;
BA_ "GenSigSwitchedByIgnition" SG_ 1413 SI_BUS_05 0;
BA_ "GenSigSendType" SG_ 1413 SI_BUS_06 3;
BA_ "GenSigStartValue" SG_ 1413 SI_BUS_06 1;
BA_ "GenSigSwitchedByIgnition" SG_ 1413 SI_BUS_06 0;
BA_ "GenSigSendType" SG_ 1413 SI_BUS_07 3;
BA_ "GenSigStartValue" SG_ 1413 SI_BUS_07 1;
BA_ "GenSigSwitchedByIgnition" SG_ 1413 SI_BUS_07 0;
BA_ "GenSigSendType" SG_ 1413 SI_BUS_08 3;
BA_ "GenSigStartValue" SG_ 1413 SI_BUS_08 1;
BA_ "GenSigSwitchedByIgnition" SG_ 1413 SI_BUS_08 0;
BA_ "GenSigSendType" SG_ 1413 SI_BUS_09 3;
BA_ "GenSigStartValue" SG_ 1413 SI_BUS_09 1;
BA_ "GenSigSwitchedByIgnition" SG_ 1413 SI_BUS_09 0;
BA_ "GenSigSendType" SG_ 1413 SI_BUS_10 3;
BA_ "GenSigStartValue" SG_ 1413 SI_BUS_10 1;
BA_ "GenSigSwitchedByIgnition" SG_ 1413 SI_BUS_10 0;
BA_ "GenSigSendType" SG_ 1413 SI_BUS_11 3;
BA_ "GenSigStartValue" SG_ 1413 SI_BUS_11 1;
BA_ "GenSigSwitchedByIgnition" SG_ 1413 SI_BUS_11 0;
BA_ "GenSigSendType" SG_ 1413 SI_BUS_12 3;
BA_ "GenSigStartValue" SG_ 1413 SI_BUS_12 1;
BA_ "GenSigSwitchedByIgnition" SG_ 1413 SI_BUS_12 0;
BA_ "GenSigSendType" SG_ 1413 SI_BUS_13 3;
BA_ "GenSigStartValue" SG_ 1413 SI_BUS_13 1;
BA_ "GenSigSwitchedByIgnition" SG_ 1413 SI_BUS_13 0;
BA_ "GenSigSendType" SG_ 1413 SI_BUS_14 3;
BA_ "GenSigStartValue" SG_ 1413 SI_BUS_14 1;
BA_ "GenSigSwitchedByIgnition" SG_ 1413 SI_BUS_14 0;
BA_ "GenSigSendType" SG_ 1413 SI_BUS_15 3;
BA_ "GenSigStartValue" SG_ 1413 SI_BUS_15 1;
BA_ "GenSigSwitchedByIgnition" SG_ 1413 SI_BUS_15 0;
BA_ "GenSigSendType" SG_ 1413 SI_Bus_Identifikation 0;
BA_ "GenSigSwitchedByIgnition" SG_ 1413 SI_Bus_Identifikation 0;
BA_ "GenSigSendType" SG_ 1413 SI_CAB_V15 3;
BA_ "GenSigSwitchedByIgnition" SG_ 1413 SI_CAB_V15 0;
BA_ "GenSigSendType" SG_ 1413 SI_Diagnose_Aktiv 3;
BA_ "GenSigSwitchedByIgnition" SG_ 1413 SI_Diagnose_Aktiv 0;
BA_ "GenSigSendType" SG_ 1413 SI_NWDF 3;
BA_ "GenSigSwitchedByIgnition" SG_ 1413 SI_NWDF 0;
BA_ "GenSigFuncType" SG_ 1413 SI_NWDF_gueltig 8;
BA_ "GenSigSendType" SG_ 1413 SI_NWDF_gueltig 3;
BA_ "GenSigSwitchedByIgnition" SG_ 1413 SI_NWDF_gueltig 0;
BA_ "GenSigSendType" SG_ 1413 SI_P_Mode 3;
BA_ "GenSigSwitchedByIgnition" SG_ 1413 SI_P_Mode 0;
BA_ "GenSigSendType" SG_ 1413 SI_P_Mode_gueltig 3;
BA_ "GenSigSwitchedByIgnition" SG_ 1413 SI_P_Mode_gueltig 0;
BA_ "GenSigSendType" SG_ 1413 SI_QRS_Mode 3;
BA_ "GenSigSwitchedByIgnition" SG_ 1413 SI_QRS_Mode 0;
BA_ "GenSigSendType" SG_ 1413 SI_Sammel_SG_Fehler 0;
BA_ "GenSigStartValue" SG_ 1413 SI_Sammel_SG_Fehler 63;
BA_ "GenSigSwitchedByIgnition" SG_ 1413 SI_Sammel_SG_Fehler 0;
BA_ "GenSigSendType" SG_ 1413 SI_Sammelfehler 3;
BA_ "GenSigSwitchedByIgnition" SG_ 1413 SI_Sammelfehler 0;
BA_ "GenSigSendType" SG_ 1413 SI_T_Mode 3;
BA_ "GenSigSwitchedByIgnition" SG_ 1413 SI_T_Mode 0;
BA_ "GenSigSendType" SG_ 1413 SI_T_Schutz 3;
BA_ "GenSigSwitchedByIgnition" SG_ 1413 SI_T_Schutz 0;
BA_ "GenSigSendType" SG_ 2589283775 NM_aktiv_Buskopplung 3;
BA_ "GenSigSwitchedByIgnition" SG_ 2589283775 NM_aktiv_Buskopplung 0;
BA_ "GenSigSendType" SG_ 2589283775 NM_aktiv_CAB 3;
BA_ "GenSigSwitchedByIgnition" SG_ 2589283775 NM_aktiv_CAB 0;
BA_ "GenSigSendType" SG_ 2589283775 NM_aktiv_CWU 3;
BA_ "GenSigSwitchedByIgnition" SG_ 2589283775 NM_aktiv_CWU 0;
BA_ "GenSigSendType" SG_ 2589283775 NM_Req_CMS 3;
BA_ "GenSigSwitchedByIgnition" SG_ 2589283775 NM_Req_CMS 0;
BA_ "GenSigSendType" SG_ 2589283775 NM_Req_DCP_01 3;
BA_ "GenSigSwitchedByIgnition" SG_ 2589283775 NM_Req_DCP_01 0;
BA_ "GenSigSendType" SG_ 2589283775 NM_Req_DCP_02 3;
BA_ "GenSigSwitchedByIgnition" SG_ 2589283775 NM_Req_DCP_02 0;
BA_ "GenSigSendType" SG_ 2589283775 NM_Req_DIM 3;
BA_ "GenSigSwitchedByIgnition" SG_ 2589283775 NM_Req_DIM 0;
BA_ "GenSigSendType" SG_ 2589283775 NM_Req_ECM 3;
BA_ "GenSigSwitchedByIgnition" SG_ 2589283775 NM_Req_ECM 0;
BA_ "GenSigSendType" SG_ 2589283775 NM_Req_EMHLR 3;
BA_ "GenSigSwitchedByIgnition" SG_ 2589283775 NM_Req_EMHLR 0;
BA_ "GenSigSendType" SG_ 2589283775 NM_Req_EOC 3;
BA_ "GenSigSwitchedByIgnition" SG_ 2589283775 NM_Req_EOC 0;
BA_ "GenSigSendType" SG_ 2589283775 NM_Req_FoD 3;
BA_ "GenSigSwitchedByIgnition" SG_ 2589283775 NM_Req_FoD 0;
BA_ "GenSigSendType" SG_ 2589283775 NM_Req_HVEM 3;
BA_ "GenSigSwitchedByIgnition" SG_ 2589283775 NM_Req_HVEM 0;
BA_ "GenSigSendType" SG_ 2589283775 NM_Req_IAA_PSO 3;
BA_ "GenSigSwitchedByIgnition" SG_ 2589283775 NM_Req_IAA_PSO 0;
BA_ "GenSigSendType" SG_ 2589283775 NM_Req_internal 3;
BA_ "GenSigSwitchedByIgnition" SG_ 2589283775 NM_Req_internal 0;
BA_ "GenSigSendType" SG_ 2589283775 NM_Req_Kessy 3;
BA_ "GenSigSwitchedByIgnition" SG_ 2589283775 NM_Req_Kessy 0;
BA_ "GenSigSendType" SG_ 2589283775 NM_Req_KLS 3;
BA_ "GenSigSwitchedByIgnition" SG_ 2589283775 NM_Req_KLS 0;
BA_ "GenSigSendType" SG_ 2589283775 NM_Req_KS 3;
BA_ "GenSigSwitchedByIgnition" SG_ 2589283775 NM_Req_KS 0;
BA_ "GenSigSendType" SG_ 2589283775 NM_Req_PaCo 3;
BA_ "GenSigSwitchedByIgnition" SG_ 2589283775 NM_Req_PaCo 0;
BA_ "GenSigSendType" SG_ 2589283775 NM_Req_RTM 3;
BA_ "GenSigSwitchedByIgnition" SG_ 2589283775 NM_Req_RTM 0;
BA_ "GenSigSendType" SG_ 2589283775 NM_Req_SAL 3;
BA_ "GenSigSwitchedByIgnition" SG_ 2589283775 NM_Req_SAL 0;
BA_ "GenSigSendType" SG_ 2589283775 NM_Req_STK 3;
BA_ "GenSigSwitchedByIgnition" SG_ 2589283775 NM_Req_STK 0;
BA_ "GenSigSendType" SG_ 2589283775 NM_Req_SWC1 3;
BA_ "GenSigSwitchedByIgnition" SG_ 2589283775 NM_Req_SWC1 0;
BA_ "GenSigSendType" SG_ 2589283775 NM_Req_SWC2 3;
BA_ "GenSigSwitchedByIgnition" SG_ 2589283775 NM_Req_SWC2 0;
BA_ "GenSigSendType" SG_ 2589283775 NM_Req_USS 3;
BA_ "GenSigSwitchedByIgnition" SG_ 2589283775 NM_Req_USS 0;
BA_ "GenSigSendType" SG_ 2589283775 NM_Req_ZM 3;
BA_ "GenSigSwitchedByIgnition" SG_ 2589283775 NM_Req_ZM 0;
BA_ "GenSigSendType" SG_ 2589283775 NM_Req_ZV 3;
BA_ "GenSigSwitchedByIgnition" SG_ 2589283775 NM_Req_ZV 0;
BA_ "GenSigSendType" SG_ 2589283775 Powerstate_Act 3;
BA_ "GenSigSwitchedByIgnition" SG_ 2589283775 Powerstate_Act 0;
BA_ "GenSigSendType" SG_ 2589283775 Powerstate_Time 3;
BA_ "GenSigSwitchedByIgnition" SG_ 2589283775 Powerstate_Time 0;
BA_ "GenSigSendType" SG_ 2589283947 NM_Reason_CMS 3;
BA_ "GenSigSwitchedByIgnition" SG_ 2589283947 NM_Reason_CMS 0;
BA_ "GenSigSendType" SG_ 2589283947 NM_Reason_DCP_1 3;
BA_ "GenSigSwitchedByIgnition" SG_ 2589283947 NM_Reason_DCP_1 0;
BA_ "GenSigSendType" SG_ 2589283947 NM_Reason_DCP_2 3;
BA_ "GenSigSwitchedByIgnition" SG_ 2589283947 NM_Reason_DCP_2 0;
BA_ "GenSigSendType" SG_ 2589283947 NM_Reason_DIM 3;
BA_ "GenSigSwitchedByIgnition" SG_ 2589283947 NM_Reason_DIM 0;
BA_ "GenSigSendType" SG_ 2589283947 NM_Reason_ECM 3;
BA_ "GenSigSwitchedByIgnition" SG_ 2589283947 NM_Reason_ECM 0;
BA_ "GenSigSendType" SG_ 2589283947 NM_Reason_EMHLR 3;
BA_ "GenSigSwitchedByIgnition" SG_ 2589283947 NM_Reason_EMHLR 0;
BA_ "GenSigSendType" SG_ 2589283947 NM_Reason_EOC 3;
BA_ "GenSigSwitchedByIgnition" SG_ 2589283947 NM_Reason_EOC 0;
BA_ "GenSigSendType" SG_ 2589283947 NM_Reason_FoD 3;
BA_ "GenSigSwitchedByIgnition" SG_ 2589283947 NM_Reason_FoD 0;
BA_ "GenSigSendType" SG_ 2589283947 NM_Reason_HVEM 3;
BA_ "GenSigSwitchedByIgnition" SG_ 2589283947 NM_Reason_HVEM 0;
BA_ "GenSigSendType" SG_ 2589283947 NM_Reason_IAA_PSO 3;
BA_ "GenSigSwitchedByIgnition" SG_ 2589283947 NM_Reason_IAA_PSO 0;
BA_ "GenSigSendType" SG_ 2589283947 NM_Reason_ICAS1_internal 3;
BA_ "GenSigSwitchedByIgnition" SG_ 2589283947 NM_Reason_ICAS1_internal 0;
BA_ "GenSigSendType" SG_ 2589283947 NM_Reason_Kessy 3;
BA_ "GenSigSwitchedByIgnition" SG_ 2589283947 NM_Reason_Kessy 0;
BA_ "GenSigSendType" SG_ 2589283947 NM_Reason_KLS 3;
BA_ "GenSigSwitchedByIgnition" SG_ 2589283947 NM_Reason_KLS 0;
BA_ "GenSigSendType" SG_ 2589283947 NM_Reason_KS 3;
BA_ "GenSigSwitchedByIgnition" SG_ 2589283947 NM_Reason_KS 0;
BA_ "GenSigSendType" SG_ 2589283947 NM_Reason_PaCo 3;
BA_ "GenSigSwitchedByIgnition" SG_ 2589283947 NM_Reason_PaCo 0;
BA_ "GenSigSendType" SG_ 2589283947 NM_Reason_RTM 3;
BA_ "GenSigSwitchedByIgnition" SG_ 2589283947 NM_Reason_RTM 0;
BA_ "GenSigSendType" SG_ 2589283947 NM_Reason_SAL 3;
BA_ "GenSigSwitchedByIgnition" SG_ 2589283947 NM_Reason_SAL 0;
BA_ "GenSigSendType" SG_ 2589283947 NM_Reason_STK 3;
BA_ "GenSigSwitchedByIgnition" SG_ 2589283947 NM_Reason_STK 0;
BA_ "GenSigSendType" SG_ 2589283947 NM_Reason_SWC1 3;
BA_ "GenSigSwitchedByIgnition" SG_ 2589283947 NM_Reason_SWC1 0;
BA_ "GenSigSendType" SG_ 2589283947 NM_Reason_SWC2 3;
BA_ "GenSigSwitchedByIgnition" SG_ 2589283947 NM_Reason_SWC2 0;
BA_ "GenSigSendType" SG_ 2589283947 NM_Reason_USS 3;
BA_ "GenSigSwitchedByIgnition" SG_ 2589283947 NM_Reason_USS 0;
BA_ "GenSigSendType" SG_ 2589283947 NM_Reason_ZM 3;
BA_ "GenSigSwitchedByIgnition" SG_ 2589283947 NM_Reason_ZM 0;
BA_ "GenSigSendType" SG_ 2589283947 NM_Reason_ZV 3;
BA_ "GenSigSwitchedByIgnition" SG_ 2589283947 NM_Reason_ZV 0;
BA_ "GenSigSendType" SG_ 2589283947 Powerstate_Prev_01 3;
BA_ "GenSigSwitchedByIgnition" SG_ 2589283947 Powerstate_Prev_01 0;
BA_ "GenSigSendType" SG_ 2589283947 Powerstate_Prev_02 3;
BA_ "GenSigSwitchedByIgnition" SG_ 2589283947 Powerstate_Prev_02 0;
BA_ "GenSigFuncType" SG_ 619 TA_01_BZ 1;
BA_ "GenSigSendType" SG_ 619 TA_01_BZ 0;
BA_ "GenSigSwitchedByIgnition" SG_ 619 TA_01_BZ 0;
BA_ "GenSigFuncType" SG_ 619 TA_01_CRC 2;
BA_ "GenSigSendType" SG_ 619 TA_01_CRC 0;
BA_ "GenSigSwitchedByIgnition" SG_ 619 TA_01_CRC 0;
BA_ "GenSigSendType" SG_ 619 TA_ACC_Sollstatus 3;
BA_ "GenSigSendType" SG_ 619 TA_aktiv_HMI 0;
BA_ "GenSigSwitchedByIgnition" SG_ 619 TA_aktiv_HMI 0;
BA_ "GenSigSendType" SG_ 619 TA_Fehler 0;
BA_ "GenSigSwitchedByIgnition" SG_ 619 TA_Fehler 0;
BA_ "GenSigSendType" SG_ 619 TA_FoD_Status 3;
BA_ "GenSigSwitchedByIgnition" SG_ 619 TA_FoD_Status 0;
BA_ "GenSigSendType" SG_ 619 TA_Handsoff_LED 0;
BA_ "GenSigSendType" SG_ 619 TA_Spurwechsel 0;
BA_ "GenSigSwitchedByIgnition" SG_ 619 TA_Spurwechsel 0;
BA_ "GenSigSendType" SG_ 619 TA_Spurwechsel_Ready 3;
BA_ "GenSigSwitchedByIgnition" SG_ 619 TA_Spurwechsel_Ready 0;
BA_ "GenSigSendType" SG_ 619 TA_Status 0;
BA_ "GenSigSendType" SG_ 619 TA_Texte 0;
BA_ "GenSigSendType" SG_ 619 TA_Texte_02 0;
BA_ "GenSigSendType" SG_ 619 TA_Ueberholhilfe 0;
BA_ "GenSigSendType" SG_ 1637 TF_BT_ConnectionState 3;
BA_ "GenSigSwitchedByIgnition" SG_ 1637 TF_BT_ConnectionState 0;
BA_ "GenSigSendType" SG_ 1637 TF_Mute_Msg_Code 3;
BA_ "GenSigSwitchedByIgnition" SG_ 1637 TF_Mute_Msg_Code 0;
BA_ "GenSigSendType" SG_ 1637 TF_Phone_active_call 3;
BA_ "GenSigSwitchedByIgnition" SG_ 1637 TF_Phone_active_call 0;
BA_ "GenSigSendType" SG_ 1637 TF_Phone_CountryCode 3;
BA_ "GenSigSwitchedByIgnition" SG_ 1637 TF_Phone_CountryCode 0;
BA_ "GenSigSendType" SG_ 1637 TF_Phone_err_fieldstrength 3;
BA_ "GenSigSwitchedByIgnition" SG_ 1637 TF_Phone_err_fieldstrength 0;
BA_ "GenSigSendType" SG_ 1637 TF_Phone_Error_Flag 3;
BA_ "GenSigSwitchedByIgnition" SG_ 1637 TF_Phone_Error_Flag 0;
BA_ "GenSigSendType" SG_ 1637 TF_Phone_FieldStrength 3;
BA_ "GenSigSwitchedByIgnition" SG_ 1637 TF_Phone_FieldStrength 0;
BA_ "GenSigSendType" SG_ 1637 TF_Phone_init 3;
BA_ "GenSigSwitchedByIgnition" SG_ 1637 TF_Phone_init 0;
BA_ "GenSigSendType" SG_ 1637 TF_Phone_mute 3;
BA_ "GenSigSwitchedByIgnition" SG_ 1637 TF_Phone_mute 0;
BA_ "GenSigSendType" SG_ 1637 TF_Phone_on 3;
BA_ "GenSigSwitchedByIgnition" SG_ 1637 TF_Phone_on 0;
BA_ "GenSigSendType" SG_ 1637 TF_Phone_PIN_ok 3;
BA_ "GenSigSwitchedByIgnition" SG_ 1637 TF_Phone_PIN_ok 0;
BA_ "GenSigSendType" SG_ 1637 TF_Phone_Provider 3;
BA_ "GenSigSwitchedByIgnition" SG_ 1637 TF_Phone_Provider 0;
BA_ "GenSigSendType" SG_ 1637 TF_Phone_RegistrationState 3;
BA_ "GenSigSwitchedByIgnition" SG_ 1637 TF_Phone_RegistrationState 0;
BA_ "GenSigSendType" SG_ 1637 TF_Phone_ring 3;
BA_ "GenSigSwitchedByIgnition" SG_ 1637 TF_Phone_ring 0;
BA_ "GenSigSendType" SG_ 1637 TF_Phone_SIM_ok 3;
BA_ "GenSigSwitchedByIgnition" SG_ 1637 TF_Phone_SIM_ok 0;
BA_ "GenSigSendType" SG_ 1637 TF_Telephone_State 3;
BA_ "GenSigSwitchedByIgnition" SG_ 1637 TF_Telephone_State 0;
BA_ "Fehlerwert" SG_ 2589283750 KBI_Aussen_Temp_gef 255;
BA_ "GenSigSendType" SG_ 2589283750 KBI_Aussen_Temp_gef 0;
BA_ "GenSigStartValue" SG_ 2589283750 KBI_Aussen_Temp_gef 254;
BA_ "GenSigSwitchedByIgnition" SG_ 2589283750 KBI_Aussen_Temp_gef 0;
BA_ "GenSigSendType" SG_ 2589283750 KBI_QBit_Aussen_Temp_gef 0;
BA_ "GenSigStartValue" SG_ 2589283750 KBI_QBit_Aussen_Temp_gef 1;
BA_ "GenSigSwitchedByIgnition" SG_ 2589283750 KBI_QBit_Aussen_Temp_gef 0;
BA_ "GenSigSendType" SG_ 1001 Thermo_Pred_Innen_Kunde_Anf 0;
BA_ "GenSigSwitchedByIgnition" SG_ 1001 Thermo_Pred_Innen_Kunde_Anf 0;
BA_ "GenSigSendType" SG_ 1001 Thermo_Pred_Innen_System_Anf 0;
BA_ "GenSigSwitchedByIgnition" SG_ 1001 Thermo_Pred_Innen_System_Anf 0;
BA_ "Fehlerwert" SG_ 1001 Thermo_Pred_P_dyn_Innen 2047;
BA_ "GenSigSendType" SG_ 1001 Thermo_Pred_P_dyn_Innen 0;
BA_ "GenSigStartValue" SG_ 1001 Thermo_Pred_P_dyn_Innen 2046;
BA_ "GenSigSwitchedByIgnition" SG_ 1001 Thermo_Pred_P_dyn_Innen 0;
BA_ "Fehlerwert" SG_ 1001 Thermo_Pred_P_stat_Innen 2047;
BA_ "GenSigSendType" SG_ 1001 Thermo_Pred_P_stat_Innen 0;
BA_ "GenSigStartValue" SG_ 1001 Thermo_Pred_P_stat_Innen 2046;
BA_ "GenSigSwitchedByIgnition" SG_ 1001 Thermo_Pred_P_stat_Innen 0;
BA_ "Fehlerwert" SG_ 1001 Thermo_Pred_T_dyn_Innen 255;
BA_ "GenSigSendType" SG_ 1001 Thermo_Pred_T_dyn_Innen 0;
BA_ "GenSigStartValue" SG_ 1001 Thermo_Pred_T_dyn_Innen 254;
BA_ "GenSigSwitchedByIgnition" SG_ 1001 Thermo_Pred_T_dyn_Innen 0;
BA_ "GenSigSendType" SG_ 1001 Thermo_Verbrauch_BTL 0;
BA_ "GenSigSwitchedByIgnition" SG_ 1001 Thermo_Verbrauch_BTL 0;
BA_ "GenSigSendType" SG_ 1001 Thermo_Verbrauch_BTL_Ueberlauf 0;
BA_ "GenSigSwitchedByIgnition" SG_ 1001 Thermo_Verbrauch_BTL_Ueberlauf 0;
BA_ "GenSigSendType" SG_ 1001 Thermo_Verbrauch_Innen 0;
BA_ "GenSigSwitchedByIgnition" SG_ 1001 Thermo_Verbrauch_Innen 0;
BA_ "GenSigSendType" SG_ 1001 Thermo_Verbrauch_Innen_Ueberlauf 0;
BA_ "GenSigSwitchedByIgnition" SG_ 1001 Thermo_Verbrauch_Innen_Ueberlauf 0;
BA_ "GenSigSendType" SG_ 1447 bCall_active 3;
BA_ "GenSigSwitchedByIgnition" SG_ 1447 bCall_active 0;
BA_ "GenSigSendType" SG_ 1447 eCall_Funktionsstatus 0;
BA_ "GenSigSwitchedByIgnition" SG_ 1447 eCall_Funktionsstatus 0;
BA_ "GenSigSendType" SG_ 1447 eCall_Funktionsstatus_02 0;
BA_ "GenSigStartValue" SG_ 1447 eCall_Funktionsstatus_02 7;
BA_ "GenSigSwitchedByIgnition" SG_ 1447 eCall_Funktionsstatus_02 0;
BA_ "GenSigSendType" SG_ 1447 iCall_active 3;
BA_ "GenSigSwitchedByIgnition" SG_ 1447 iCall_active 0;
BA_ "Fehlerwert" SG_ 1447 MOD_Energie_Anf 3;
BA_ "GenSigSendType" SG_ 1447 MOD_Energie_Anf 0;
BA_ "GenSigSwitchedByIgnition" SG_ 1447 MOD_Energie_Anf 0;
BA_ "GenSigSendType" SG_ 1447 OCU_Privacymode_Locationdata 0;
BA_ "GenSigSwitchedByIgnition" SG_ 1447 OCU_Privacymode_Locationdata 0;
BA_ "GenSigSendType" SG_ 1447 OCU_Privacymode_Status 0;
BA_ "GenSigSwitchedByIgnition" SG_ 1447 OCU_Privacymode_Status 0;
BA_ "GenSigFuncType" SG_ 1447 TM_01_BZ 1;
BA_ "GenSigSendType" SG_ 1447 TM_01_BZ 0;
BA_ "GenSigSwitchedByIgnition" SG_ 1447 TM_01_BZ 0;
BA_ "GenSigSendType" SG_ 1447 TM_Door_Lock 5;
BA_ "GenSigSwitchedByIgnition" SG_ 1447 TM_Door_Lock 0;
BA_ "GenSigSendType" SG_ 1447 TM_Door_Unlock 5;
BA_ "GenSigSwitchedByIgnition" SG_ 1447 TM_Door_Unlock 0;
BA_ "GenSigSendType" SG_ 1447 TM_Nur_Hupen 5;
BA_ "GenSigSwitchedByIgnition" SG_ 1447 TM_Nur_Hupen 0;
BA_ "GenSigSendType" SG_ 1447 TM_Panik_Alarm 5;
BA_ "GenSigSwitchedByIgnition" SG_ 1447 TM_Panik_Alarm 0;
BA_ "GenSigSendType" SG_ 1447 TM_Spiegel_Anklappen 5;
BA_ "GenSigSwitchedByIgnition" SG_ 1447 TM_Spiegel_Anklappen 0;
BA_ "GenSigSendType" SG_ 1447 TM_Warnblinken 5;
BA_ "GenSigSwitchedByIgnition" SG_ 1447 TM_Warnblinken 0;
BA_ "GenSigSendType" SG_ 1447 TM_ZV_Signatur 0;
BA_ "GenSigSwitchedByIgnition" SG_ 1447 TM_ZV_Signatur 0;
BA_ "GenSigSendType" SG_ 977 ASW_Warnung_aktiv_BFS 3;
BA_ "GenSigSwitchedByIgnition" SG_ 977 ASW_Warnung_aktiv_BFS 0;
BA_ "Fehlerwert" SG_ 977 BFS_Status_eTAG 3;
BA_ "GenSigSendType" SG_ 977 BFS_Status_eTAG 3;
BA_ "GenSigSwitchedByIgnition" SG_ 977 BFS_Status_eTAG 0;
BA_ "GenSigSendType" SG_ 977 BT_ASW_HMI_defekt 0;
BA_ "GenSigSwitchedByIgnition" SG_ 977 BT_ASW_HMI_defekt 0;
BA_ "GenSigSendType" SG_ 977 BT_EC_Spiegel_Helligkeit 3;
BA_ "GenSigSwitchedByIgnition" SG_ 977 BT_EC_Spiegel_Helligkeit 0;
BA_ "GenSigSendType" SG_ 977 BT_FH_Bew_hoch 3;
BA_ "GenSigSwitchedByIgnition" SG_ 977 BT_FH_Bew_hoch 0;
BA_ "GenSigSendType" SG_ 977 BT_FH_Bew_tief 3;
BA_ "GenSigSwitchedByIgnition" SG_ 977 BT_FH_Bew_tief 0;
BA_ "GenSigSendType" SG_ 977 BT_FH_Block 3;
BA_ "GenSigSwitchedByIgnition" SG_ 977 BT_FH_Block 0;
BA_ "GenSigSendType" SG_ 977 BT_FH_Fang 3;
BA_ "GenSigSwitchedByIgnition" SG_ 977 BT_FH_Fang 0;
BA_ "GenSigSendType" SG_ 977 BT_FH_normiert 3;
BA_ "GenSigSwitchedByIgnition" SG_ 977 BT_FH_normiert 0;
BA_ "GenSigSendType" SG_ 977 BT_FH_Oeffnung 3;
BA_ "GenSigSwitchedByIgnition" SG_ 977 BT_FH_Oeffnung 0;
BA_ "GenSigSendType" SG_ 977 BT_FH_Pos_oben 3;
BA_ "GenSigSwitchedByIgnition" SG_ 977 BT_FH_Pos_oben 0;
BA_ "GenSigSendType" SG_ 977 BT_FH_S_AutoHoch 3;
BA_ "GenSigSwitchedByIgnition" SG_ 977 BT_FH_S_AutoHoch 0;
BA_ "GenSigSendType" SG_ 977 BT_FH_S_AutoTief 3;
BA_ "GenSigSwitchedByIgnition" SG_ 977 BT_FH_S_AutoTief 0;
BA_ "GenSigSendType" SG_ 977 BT_FH_S_ManHoch 3;
BA_ "GenSigSwitchedByIgnition" SG_ 977 BT_FH_S_ManHoch 0;
BA_ "GenSigSendType" SG_ 977 BT_FH_S_ManTief 3;
BA_ "GenSigSwitchedByIgnition" SG_ 977 BT_FH_S_ManTief 0;
BA_ "GenSigSendType" SG_ 977 BT_FH_Thermo 3;
BA_ "GenSigSwitchedByIgnition" SG_ 977 BT_FH_Thermo 0;
BA_ "GenSigSendType" SG_ 977 BT_gesafet 3;
BA_ "GenSigSwitchedByIgnition" SG_ 977 BT_gesafet 0;
BA_ "Fehlerwert" SG_ 977 BT_Kisi_Fehler 1;
BA_ "GenSigSendType" SG_ 977 BT_Kisi_Fehler 3;
BA_ "GenSigSwitchedByIgnition" SG_ 977 BT_Kisi_Fehler 0;
BA_ "GenSigSendType" SG_ 977 BT_Lock_Taster 3;
BA_ "GenSigSwitchedByIgnition" SG_ 977 BT_Lock_Taster 0;
BA_ "GenSigSendType" SG_ 977 BT_Lock_Taster_inv 3;
BA_ "GenSigSwitchedByIgnition" SG_ 977 BT_Lock_Taster_inv 0;
BA_ "GenSigSendType" SG_ 977 BT_Lock_Unlock_Taster 3;
BA_ "GenSigSwitchedByIgnition" SG_ 977 BT_Lock_Unlock_Taster 0;
BA_ "GenSigSendType" SG_ 977 BT_Oben_Block_erw 3;
BA_ "GenSigSwitchedByIgnition" SG_ 977 BT_Oben_Block_erw 0;
BA_ "GenSigSendType" SG_ 977 BT_Schliesstaster 3;
BA_ "GenSigSwitchedByIgnition" SG_ 977 BT_Schliesstaster 0;
BA_ "GenSigSendType" SG_ 977 BT_Schluesselschalter_auf 3;
BA_ "GenSigSwitchedByIgnition" SG_ 977 BT_Schluesselschalter_auf 0;
BA_ "GenSigSendType" SG_ 977 BT_Schluesselschalter_zu 3;
BA_ "GenSigSwitchedByIgnition" SG_ 977 BT_Schluesselschalter_zu 0;
BA_ "GenSigSendType" SG_ 977 BT_Schluesselschalter_zu_inv 3;
BA_ "GenSigSwitchedByIgnition" SG_ 977 BT_Schluesselschalter_zu_inv 0;
BA_ "GenSigSendType" SG_ 977 BT_SP_ausgerastet 3;
BA_ "GenSigSwitchedByIgnition" SG_ 977 BT_SP_ausgerastet 0;
BA_ "GenSigSendType" SG_ 977 BT_Sp_Blk_def 3;
BA_ "GenSigSwitchedByIgnition" SG_ 977 BT_Sp_Blk_def 0;
BA_ "GenSigSendType" SG_ 977 BT_SP_Heizung_aktiv 3;
BA_ "GenSigSwitchedByIgnition" SG_ 977 BT_SP_Heizung_aktiv 0;
BA_ "GenSigSendType" SG_ 977 BT_Sp_Heizung_Anf 0;
BA_ "GenSigSwitchedByIgnition" SG_ 977 BT_Sp_Heizung_Anf 0;
BA_ "GenSigSendType" SG_ 977 BT_SP_Heizung_Status 3;
BA_ "GenSigSwitchedByIgnition" SG_ 977 BT_SP_Heizung_Status 0;
BA_ "GenSigSendType" SG_ 977 BT_SP_ht_aktiv 3;
BA_ "GenSigSwitchedByIgnition" SG_ 977 BT_SP_ht_aktiv 0;
BA_ "GenSigSendType" SG_ 977 BT_SP_lr_aktiv 3;
BA_ "GenSigSwitchedByIgnition" SG_ 977 BT_SP_lr_aktiv 0;
BA_ "GenSigSendType" SG_ 977 BT_Sperrklinke 3;
BA_ "GenSigSwitchedByIgnition" SG_ 977 BT_Sperrklinke 0;
BA_ "GenSigSendType" SG_ 977 BT_SWA_HMI_defekt 0;
BA_ "GenSigSwitchedByIgnition" SG_ 977 BT_SWA_HMI_defekt 0;
BA_ "GenSigSendType" SG_ 977 BT_TAG_betaetigt 3;
BA_ "GenSigSwitchedByIgnition" SG_ 977 BT_TAG_betaetigt 0;
BA_ "GenSigSendType" SG_ 977 BT_TCR_Mode_aktiv 3;
BA_ "GenSigSwitchedByIgnition" SG_ 977 BT_TCR_Mode_aktiv 0;
BA_ "GenSigSendType" SG_ 977 BT_TIG_betaetigt 3;
BA_ "GenSigSwitchedByIgnition" SG_ 977 BT_TIG_betaetigt 0;
BA_ "GenSigSendType" SG_ 977 BT_TSG_hinten_verbaut 3;
BA_ "GenSigSwitchedByIgnition" SG_ 977 BT_TSG_hinten_verbaut 0;
BA_ "GenSigSendType" SG_ 977 BT_Tuer_geoeffnet 3;
BA_ "GenSigSwitchedByIgnition" SG_ 977 BT_Tuer_geoeffnet 0;
BA_ "Fehlerwert" SG_ 977 BT_Tuer_Status 3;
BA_ "GenSigSendType" SG_ 977 BT_Tuer_Status 3;
BA_ "GenSigSwitchedByIgnition" SG_ 977 BT_Tuer_Status 0;
BA_ "GenSigSendType" SG_ 977 BT_Tuer_Status_QBit 0;
BA_ "GenSigSwitchedByIgnition" SG_ 977 BT_Tuer_Status_QBit 0;
BA_ "GenSigSendType" SG_ 977 BT_Tueroeffnen_Warnung 3;
BA_ "GenSigSwitchedByIgnition" SG_ 977 BT_Tueroeffnen_Warnung 0;
BA_ "GenSigSendType" SG_ 977 BT_Tuerschloss_defekt 0;
BA_ "GenSigSwitchedByIgnition" SG_ 977 BT_Tuerschloss_defekt 0;
BA_ "GenSigSendType" SG_ 977 BT_UEKB_aktiviert 3;
BA_ "GenSigSwitchedByIgnition" SG_ 977 BT_UEKB_aktiviert 0;
BA_ "GenSigSendType" SG_ 977 BT_Unlock_Taster 3;
BA_ "GenSigSwitchedByIgnition" SG_ 977 BT_Unlock_Taster 0;
BA_ "GenSigSendType" SG_ 977 BT_Unten_Block_erw 3;
BA_ "GenSigSwitchedByIgnition" SG_ 977 BT_Unten_Block_erw 0;
BA_ "GenSigSendType" SG_ 977 BT_verriegelt 3;
BA_ "GenSigSwitchedByIgnition" SG_ 977 BT_verriegelt 0;
BA_ "GenSigSendType" SG_ 977 BT_Zuziehhilfe_aktiv 3;
BA_ "GenSigSwitchedByIgnition" SG_ 977 BT_Zuziehhilfe_aktiv 0;
BA_ "GenSigSendType" SG_ 976 ASW_HMI_defekt 0;
BA_ "GenSigSwitchedByIgnition" SG_ 976 ASW_HMI_defekt 0;
BA_ "GenSigSendType" SG_ 976 ASW_wakeup 3;
BA_ "GenSigSwitchedByIgnition" SG_ 976 ASW_wakeup 0;
BA_ "GenSigSendType" SG_ 976 ASW_Warnung_aktiv_FS 3;
BA_ "GenSigSwitchedByIgnition" SG_ 976 ASW_Warnung_aktiv_FS 0;
BA_ "Fehlerwert" SG_ 976 FS_Status_eTAG 3;
BA_ "GenSigSendType" SG_ 976 FS_Status_eTAG 3;
BA_ "GenSigSwitchedByIgnition" SG_ 976 FS_Status_eTAG 0;
BA_ "GenSigSendType" SG_ 976 FT_BFS_Fond_Freigabe 3;
BA_ "GenSigSwitchedByIgnition" SG_ 976 FT_BFS_Fond_Freigabe 0;
BA_ "GenSigSendType" SG_ 976 FT_Daemmglas 3;
BA_ "GenSigSwitchedByIgnition" SG_ 976 FT_Daemmglas 0;
BA_ "GenSigSendType" SG_ 976 FT_FH_Bew_hoch 3;
BA_ "GenSigSwitchedByIgnition" SG_ 976 FT_FH_Bew_hoch 0;
BA_ "GenSigSendType" SG_ 976 FT_FH_Bew_tief 3;
BA_ "GenSigSwitchedByIgnition" SG_ 976 FT_FH_Bew_tief 0;
BA_ "GenSigSendType" SG_ 976 FT_FH_Block 3;
BA_ "GenSigSwitchedByIgnition" SG_ 976 FT_FH_Block 0;
BA_ "GenSigSendType" SG_ 976 FT_FH_Fang 3;
BA_ "GenSigSwitchedByIgnition" SG_ 976 FT_FH_Fang 0;
BA_ "GenSigSendType" SG_ 976 FT_FH_normiert 3;
BA_ "GenSigSwitchedByIgnition" SG_ 976 FT_FH_normiert 0;
BA_ "GenSigSendType" SG_ 976 FT_FH_Oeffnung 3;
BA_ "GenSigSwitchedByIgnition" SG_ 976 FT_FH_Oeffnung 0;
BA_ "GenSigSendType" SG_ 976 FT_FH_Pos_oben 3;
BA_ "GenSigSwitchedByIgnition" SG_ 976 FT_FH_Pos_oben 0;
BA_ "GenSigSendType" SG_ 976 FT_FH_S_AutoHoch 3;
BA_ "GenSigSwitchedByIgnition" SG_ 976 FT_FH_S_AutoHoch 0;
BA_ "GenSigSendType" SG_ 976 FT_FH_S_AutoTief 3;
BA_ "GenSigSwitchedByIgnition" SG_ 976 FT_FH_S_AutoTief 0;
BA_ "GenSigSendType" SG_ 976 FT_FH_S_ManHoch 3;
BA_ "GenSigSwitchedByIgnition" SG_ 976 FT_FH_S_ManHoch 0;
BA_ "GenSigSendType" SG_ 976 FT_FH_S_ManTief 3;
BA_ "GenSigSwitchedByIgnition" SG_ 976 FT_FH_S_ManTief 0;
BA_ "GenSigSendType" SG_ 976 FT_FH_Thermo 3;
BA_ "GenSigSwitchedByIgnition" SG_ 976 FT_FH_Thermo 0;
BA_ "GenSigSendType" SG_ 976 FT_gesafet 3;
BA_ "GenSigSwitchedByIgnition" SG_ 976 FT_gesafet 0;
BA_ "GenSigSendType" SG_ 976 FT_HD_Taste 3;
BA_ "GenSigSwitchedByIgnition" SG_ 976 FT_HD_Taste 0;
BA_ "GenSigSendType" SG_ 976 FT_HD_Taste_2 3;
BA_ "GenSigSwitchedByIgnition" SG_ 976 FT_HD_Taste_2 0;
BA_ "GenSigSendType" SG_ 976 FT_IRUE_Taste 3;
BA_ "GenSigSwitchedByIgnition" SG_ 976 FT_IRUE_Taste 0;
BA_ "Fehlerwert" SG_ 976 FT_Kisi_Fehler 1;
BA_ "GenSigSendType" SG_ 976 FT_Kisi_Fehler 3;
BA_ "GenSigSwitchedByIgnition" SG_ 976 FT_Kisi_Fehler 0;
BA_ "GenSigSendType" SG_ 976 FT_Kisi_li_aktiv 3;
BA_ "GenSigSwitchedByIgnition" SG_ 976 FT_Kisi_li_aktiv 0;
BA_ "GenSigSendType" SG_ 976 FT_Kisi_re_aktiv 3;
BA_ "GenSigSwitchedByIgnition" SG_ 976 FT_Kisi_re_aktiv 0;
BA_ "GenSigSendType" SG_ 976 FT_Kisi_Taster_li 3;
BA_ "GenSigSwitchedByIgnition" SG_ 976 FT_Kisi_Taster_li 0;
BA_ "GenSigSendType" SG_ 976 FT_Kisi_Taster_re 3;
BA_ "GenSigSwitchedByIgnition" SG_ 976 FT_Kisi_Taster_re 0;
BA_ "GenSigSendType" SG_ 976 FT_Lock_Taster 3;
BA_ "GenSigSwitchedByIgnition" SG_ 976 FT_Lock_Taster 0;
BA_ "GenSigSendType" SG_ 976 FT_Lock_Unlock_Taster 3;
BA_ "GenSigSwitchedByIgnition" SG_ 976 FT_Lock_Unlock_Taster 0;
BA_ "GenSigSendType" SG_ 976 FT_Oben_Block_erw 3;
BA_ "GenSigSwitchedByIgnition" SG_ 976 FT_Oben_Block_erw 0;
BA_ "GenSigSendType" SG_ 976 FT_Schliesstaster 3;
BA_ "GenSigSwitchedByIgnition" SG_ 976 FT_Schliesstaster 0;
BA_ "GenSigSendType" SG_ 976 FT_Schluesselschalter_auf 3;
BA_ "GenSigSwitchedByIgnition" SG_ 976 FT_Schluesselschalter_auf 0;
BA_ "GenSigSendType" SG_ 976 FT_Schluesselschalter_zu 3;
BA_ "GenSigSwitchedByIgnition" SG_ 976 FT_Schluesselschalter_zu 0;
BA_ "GenSigSendType" SG_ 976 FT_SP_ausgerastet 3;
BA_ "GenSigSwitchedByIgnition" SG_ 976 FT_SP_ausgerastet 0;
BA_ "GenSigSendType" SG_ 976 FT_Sp_Blk_def 3;
BA_ "GenSigSwitchedByIgnition" SG_ 976 FT_Sp_Blk_def 0;
BA_ "GenSigSendType" SG_ 976 FT_Sp_Heizung_Anf 0;
BA_ "GenSigSwitchedByIgnition" SG_ 976 FT_Sp_Heizung_Anf 0;
BA_ "GenSigSendType" SG_ 976 FT_SP_Heizung_Status 3;
BA_ "GenSigSwitchedByIgnition" SG_ 976 FT_SP_Heizung_Status 0;
BA_ "GenSigSendType" SG_ 976 FT_SP_ht_aktiv 3;
BA_ "GenSigSwitchedByIgnition" SG_ 976 FT_SP_ht_aktiv 0;
BA_ "GenSigSendType" SG_ 976 FT_SP_lr_aktiv 3;
BA_ "GenSigSwitchedByIgnition" SG_ 976 FT_SP_lr_aktiv 0;
BA_ "GenSigSendType" SG_ 976 FT_Sperrklinke 3;
BA_ "GenSigSwitchedByIgnition" SG_ 976 FT_Sperrklinke 0;
BA_ "GenSigSendType" SG_ 976 FT_SWA_Taster 3;
BA_ "GenSigSwitchedByIgnition" SG_ 976 FT_SWA_Taster 0;
BA_ "GenSigSendType" SG_ 976 FT_TAG_betaetigt 3;
BA_ "GenSigSwitchedByIgnition" SG_ 976 FT_TAG_betaetigt 0;
BA_ "GenSigSendType" SG_ 976 FT_TD_Taste 3;
BA_ "GenSigSwitchedByIgnition" SG_ 976 FT_TD_Taste 0;
BA_ "GenSigSendType" SG_ 976 FT_TD_Taste_Fehler 0;
BA_ "GenSigSwitchedByIgnition" SG_ 976 FT_TD_Taste_Fehler 0;
BA_ "GenSigSendType" SG_ 976 FT_TIG_betaetigt 3;
BA_ "GenSigSwitchedByIgnition" SG_ 976 FT_TIG_betaetigt 0;
BA_ "GenSigSendType" SG_ 976 FT_TSG_hinten_verbaut 3;
BA_ "GenSigSwitchedByIgnition" SG_ 976 FT_TSG_hinten_verbaut 0;
BA_ "GenSigSendType" SG_ 976 FT_Tuer_geoeffnet 3;
BA_ "GenSigSwitchedByIgnition" SG_ 976 FT_Tuer_geoeffnet 0;
BA_ "GenSigSendType" SG_ 976 FT_Tuerschloss_defekt 0;
BA_ "GenSigSwitchedByIgnition" SG_ 976 FT_Tuerschloss_defekt 0;
BA_ "GenSigSendType" SG_ 976 FT_UEKB_aktiviert 3;
BA_ "GenSigSwitchedByIgnition" SG_ 976 FT_UEKB_aktiviert 0;
BA_ "GenSigSendType" SG_ 976 FT_Unlock_Taster 3;
BA_ "GenSigSwitchedByIgnition" SG_ 976 FT_Unlock_Taster 0;
BA_ "GenSigSendType" SG_ 976 FT_Unten_Block_erw 3;
BA_ "GenSigSwitchedByIgnition" SG_ 976 FT_Unten_Block_erw 0;
BA_ "GenSigSendType" SG_ 976 FT_verriegelt 3;
BA_ "GenSigSwitchedByIgnition" SG_ 976 FT_verriegelt 0;
BA_ "GenSigSendType" SG_ 976 FT_Zuziehhilfe_aktiv 3;
BA_ "GenSigSwitchedByIgnition" SG_ 976 FT_Zuziehhilfe_aktiv 0;
BA_ "GenSigSendType" SG_ 976 SSR_Temp_Freigabe 0;
BA_ "GenSigSwitchedByIgnition" SG_ 976 SSR_Temp_Freigabe 0;
BA_ "GenSigSendType" SG_ 976 SWA_HMI_Diagnose 0;
BA_ "GenSigSwitchedByIgnition" SG_ 976 SWA_HMI_Diagnose 0;
BA_ "Fehlerwert" SG_ 997 FT_BFS_Tuer_Status 3;
BA_ "GenSigSendType" SG_ 997 FT_BFS_Tuer_Status 3;
BA_ "GenSigSwitchedByIgnition" SG_ 997 FT_BFS_Tuer_Status 0;
BA_ "GenSigSendType" SG_ 997 FT_Cargolock_bet 3;
BA_ "GenSigSwitchedByIgnition" SG_ 997 FT_Cargolock_bet 0;
BA_ "Fehlerwert" SG_ 997 FT_HBFS_Tuer_Status 3;
BA_ "GenSigSendType" SG_ 997 FT_HBFS_Tuer_Status 3;
BA_ "GenSigSwitchedByIgnition" SG_ 997 FT_HBFS_Tuer_Status 0;
BA_ "Fehlerwert" SG_ 997 FT_HFS_Tuer_Status 3;
BA_ "GenSigSendType" SG_ 997 FT_HFS_Tuer_Status 3;
BA_ "GenSigSwitchedByIgnition" SG_ 997 FT_HFS_Tuer_Status 0;
BA_ "GenSigSendType" SG_ 997 FT_kisi_asynchron 3;
BA_ "GenSigSwitchedByIgnition" SG_ 997 FT_kisi_asynchron 0;
BA_ "GenSigSendType" SG_ 997 FT_KiSi_Status_Soll_HBFS 0;
BA_ "GenSigSwitchedByIgnition" SG_ 997 FT_KiSi_Status_Soll_HBFS 0;
BA_ "GenSigSendType" SG_ 997 FT_KiSi_Status_Soll_HFS 0;
BA_ "GenSigSwitchedByIgnition" SG_ 997 FT_KiSi_Status_Soll_HFS 0;
BA_ "GenSigSendType" SG_ 997 FT_Kisi_Taster_li_02 3;
BA_ "GenSigSwitchedByIgnition" SG_ 997 FT_Kisi_Taster_li_02 0;
BA_ "GenSigSendType" SG_ 997 FT_Kisi_Taster_re_02 3;
BA_ "GenSigSwitchedByIgnition" SG_ 997 FT_Kisi_Taster_re_02 0;
BA_ "GenSigSendType" SG_ 997 FT_Lock_Taster_02 0;
BA_ "GenSigSwitchedByIgnition" SG_ 997 FT_Lock_Taster_02 0;
BA_ "GenSigSendType" SG_ 997 FT_Schluesselschalter_zu_02 0;
BA_ "GenSigSwitchedByIgnition" SG_ 997 FT_Schluesselschalter_zu_02 0;
BA_ "GenSigSendType" SG_ 997 FT_SP_Heizung_ein 3;
BA_ "GenSigSwitchedByIgnition" SG_ 997 FT_SP_Heizung_ein 0;
BA_ "GenSigSendType" SG_ 997 FT_TCR_Mode_aktiv 3;
BA_ "GenSigSwitchedByIgnition" SG_ 997 FT_TCR_Mode_aktiv 0;
BA_ "GenSigSendType" SG_ 997 FT_TD_Taste_Status 3;
BA_ "GenSigSwitchedByIgnition" SG_ 997 FT_TD_Taste_Status 0;
BA_ "Fehlerwert" SG_ 997 FT_Tuer_Status 3;
BA_ "GenSigSendType" SG_ 997 FT_Tuer_Status 3;
BA_ "GenSigSwitchedByIgnition" SG_ 997 FT_Tuer_Status 0;
BA_ "GenSigSendType" SG_ 997 FT_Tuer_Status_QBit 0;
BA_ "GenSigSwitchedByIgnition" SG_ 997 FT_Tuer_Status_QBit 0;
BA_ "GenSigSendType" SG_ 997 FT_Tueroeffnen_Warnung 3;
BA_ "GenSigSwitchedByIgnition" SG_ 997 FT_Tueroeffnen_Warnung 0;
BA_ "GenSigSendType" SG_ 997 TBF_FS_Touch_Event 3;
BA_ "GenSigSwitchedByIgnition" SG_ 997 TBF_FS_Touch_Event 0;
BA_ "GenSigSendType" SG_ 997 TSG_FS_Spiegel_angeklappt 3;
BA_ "GenSigSwitchedByIgnition" SG_ 997 TSG_FS_Spiegel_angeklappt 0;
BA_ "GenSigFuncType" SG_ 997 TSG_FT_02_BZ 1;
BA_ "GenSigSendType" SG_ 997 TSG_FT_02_BZ 0;
BA_ "GenSigSwitchedByIgnition" SG_ 997 TSG_FT_02_BZ 0;
BA_ "GenSigFuncType" SG_ 997 TSG_FT_02_CRC 2;
BA_ "GenSigSendType" SG_ 997 TSG_FT_02_CRC 0;
BA_ "GenSigSwitchedByIgnition" SG_ 997 TSG_FT_02_CRC 0;
BA_REL_ "GenSigTimeoutTime" BU_SG_REL_ Fahrerdisplay_Kombi SG_ 1413 SI_BUS_02 5000;
BA_REL_ "GenSigTimeoutTime" BU_SG_REL_ Fahrerdisplay_Kombi SG_ 1413 SI_NWDF 5000;
BA_REL_ "GenSigTimeoutTime" BU_SG_REL_ Fahrerdisplay_Kombi SG_ 1413 SI_NWDF_gueltig 5000;
BA_REL_ "GenSigTimeoutTime" BU_SG_REL_ Fahrerdisplay_Kombi SG_ 1413 SI_P_Mode 5000;
BA_REL_ "GenSigTimeoutTime" BU_SG_REL_ Fahrerdisplay_Kombi SG_ 1413 SI_P_Mode_gueltig 5000;
BA_REL_ "GenSigTimeoutTime" BU_SG_REL_ Fahrerdisplay_Kombi SG_ 1413 SI_QRS_Mode 5000;
BA_REL_ "GenSigTimeoutTime" BU_SG_REL_ Fahrerdisplay_Kombi SG_ 1413 SI_T_Mode 5000;
BA_REL_ "GenSigTimeoutTime" BU_SG_REL_ Fahrerdisplay_Kombi SG_ 2527679739 STK_Voko_LED 5000;
BA_REL_ "GenSigTimeoutTime" BU_SG_REL_ HUD SG_ 1413 SI_NWDF 5000;
BA_REL_ "GenSigTimeoutTime" BU_SG_REL_ HUD SG_ 1413 SI_NWDF_gueltig 5000;
BA_REL_ "GenSigTimeoutTime" BU_SG_REL_ HUD SG_ 1413 SI_P_Mode 5000;
BA_REL_ "GenSigTimeoutTime" BU_SG_REL_ HUD SG_ 1413 SI_P_Mode_gueltig 5000;
BA_REL_ "GenSigTimeoutTime" BU_SG_REL_ HUD SG_ 1413 SI_QRS_Mode 5000;
BA_REL_ "GenSigTimeoutTime" BU_SG_REL_ HUD SG_ 1413 SI_T_Mode 5000;
BA_REL_ "GenSigTimeoutTime" BU_SG_REL_ ICAS1_X_Gateway SG_ 1637 TF_Telephone_State 5000;
BA_REL_ "GenSigTimeoutTime" BU_SG_REL_ ICAS3_Gateway SG_ 619 TA_Fehler 1000;
BA_REL_ "GenSigTimeoutTime" BU_SG_REL_ ICAS3_Gateway SG_ 619 TA_FoD_Status 1000;
BA_REL_ "GenSigTimeoutTime" BU_SG_REL_ ICAS3_Gateway SG_ 619 TA_Handsoff_LED 1000;
BA_REL_ "GenSigTimeoutTime" BU_SG_REL_ ICAS3_Gateway SG_ 619 TA_aktiv_HMI 1000;
BA_REL_ "GenSigTimeoutTime" BU_SG_REL_ ICAS3_Gateway SG_ 976 FT_Tuer_geoeffnet 1000;
BA_REL_ "GenSigTimeoutTime" BU_SG_REL_ ICAS3_Gateway SG_ 977 BT_Tuer_geoeffnet 1000;
BA_REL_ "GenSigTimeoutTime" BU_SG_REL_ ICAS3_Gateway SG_ 980 BH_Blinker_li 5000;
BA_REL_ "GenSigTimeoutTime" BU_SG_REL_ ICAS3_Gateway SG_ 980 BH_Blinker_re 5000;
BA_REL_ "GenSigTimeoutTime" BU_SG_REL_ ICAS3_Gateway SG_ 997 FT_Tuer_Status 1000;
BA_REL_ "GenSigTimeoutTime" BU_SG_REL_ ICAS3_Gateway SG_ 997 TBF_FS_Touch_Event 1000;
BA_REL_ "GenSigTimeoutTime" BU_SG_REL_ ICAS3_Gateway SG_ 1413 SI_BUS_01 5000;
BA_REL_ "GenSigTimeoutTime" BU_SG_REL_ ICAS3_Gateway SG_ 1413 SI_BUS_02 5000;
BA_REL_ "GenSigTimeoutTime" BU_SG_REL_ ICAS3_Gateway SG_ 1413 SI_BUS_03 5000;
BA_REL_ "GenSigTimeoutTime" BU_SG_REL_ ICAS3_Gateway SG_ 1413 SI_BUS_04 5000;
BA_REL_ "GenSigTimeoutTime" BU_SG_REL_ ICAS3_Gateway SG_ 1413 SI_BUS_05 5000;
BA_REL_ "GenSigTimeoutTime" BU_SG_REL_ ICAS3_Gateway SG_ 1413 SI_BUS_06 5000;
BA_REL_ "GenSigTimeoutTime" BU_SG_REL_ ICAS3_Gateway SG_ 1413 SI_BUS_07 5000;
BA_REL_ "GenSigTimeoutTime" BU_SG_REL_ ICAS3_Gateway SG_ 1413 SI_BUS_08 5000;
BA_REL_ "GenSigTimeoutTime" BU_SG_REL_ ICAS3_Gateway SG_ 1413 SI_BUS_09 5000;
BA_REL_ "GenSigTimeoutTime" BU_SG_REL_ ICAS3_Gateway SG_ 1413 SI_BUS_10 5000;
BA_REL_ "GenSigTimeoutTime" BU_SG_REL_ ICAS3_Gateway SG_ 1413 SI_BUS_11 5000;
BA_REL_ "GenSigTimeoutTime" BU_SG_REL_ ICAS3_Gateway SG_ 1413 SI_BUS_12 5000;
BA_REL_ "GenSigTimeoutTime" BU_SG_REL_ ICAS3_Gateway SG_ 1413 SI_BUS_13 5000;
BA_REL_ "GenSigTimeoutTime" BU_SG_REL_ ICAS3_Gateway SG_ 1413 SI_BUS_14 5000;
BA_REL_ "GenSigTimeoutTime" BU_SG_REL_ ICAS3_Gateway SG_ 1413 SI_BUS_15 5000;
BA_REL_ "GenSigTimeoutTime" BU_SG_REL_ ICAS3_Gateway SG_ 1413 SI_CAB_V15 5000;
BA_REL_ "GenSigTimeoutTime" BU_SG_REL_ ICAS3_Gateway SG_ 1413 SI_NWDF 5000;
BA_REL_ "GenSigTimeoutTime" BU_SG_REL_ ICAS3_Gateway SG_ 1413 SI_NWDF_gueltig 5000;
BA_REL_ "GenSigTimeoutTime" BU_SG_REL_ ICAS3_Gateway SG_ 1413 SI_P_Mode 5000;
BA_REL_ "GenSigTimeoutTime" BU_SG_REL_ ICAS3_Gateway SG_ 1413 SI_P_Mode_gueltig 5000;
BA_REL_ "GenSigTimeoutTime" BU_SG_REL_ ICAS3_Gateway SG_ 1413 SI_QRS_Mode 5000;
BA_REL_ "GenSigTimeoutTime" BU_SG_REL_ ICAS3_Gateway SG_ 1413 SI_T_Mode 5000;
BA_REL_ "GenSigTimeoutTime" BU_SG_REL_ ICAS3_Gateway SG_ 1413 SI_T_Schutz 5000;
BA_REL_ "GenSigTimeoutTime" BU_SG_REL_ ICAS3_Gateway SG_ 2463978805 SmaLi_AppSwVersion 5000;
BA_REL_ "GenSigTimeoutTime" BU_SG_REL_ ICAS3_Gateway SG_ 2463978805 SmaLi_Cnt_06 5000;
BA_REL_ "GenSigTimeoutTime" BU_SG_REL_ ICAS3_Gateway SG_ 2463978805 SmaLi_CtrlCmdRsp_01 5000;
BA_REL_ "GenSigTimeoutTime" BU_SG_REL_ ICAS3_Gateway SG_ 2463978805 SmaLi_InterfaceVersion 5000;
BA_REL_ "GenSigTimeoutTime" BU_SG_REL_ ICAS3_Gateway SG_ 2463978805 SmaLi_MovieIDRsp 5000;
BA_REL_ "GenSigTimeoutTime" BU_SG_REL_ ICAS3_Gateway SG_ 2463978805 SmaLi_SavedMovieBundleVersion 5000;
BA_REL_ "GenSigTimeoutTime" BU_SG_REL_ ICAS3_Gateway SG_ 2463978805 SmaLi_SlotID_06 5000;
BA_REL_ "GenSigTimeoutTime" BU_SG_REL_ ICAS3_Gateway SG_ 2463978805 SmaLi_availMemory 5000;
BA_REL_ "GenSigTimeoutTime" BU_SG_REL_ ICAS3_Gateway SG_ 2463978805 SmaLi_error_cause 5000;
BA_REL_ "GenSigTimeoutTime" BU_SG_REL_ ICAS3_Gateway SG_ 2463978805 SmaLi_numLEDs 5000;
BA_REL_ "GenSigTimeoutTime" BU_SG_REL_ ICAS3_Gateway SG_ 2463978805 SmaLi_numOfSlots 5000;
BA_REL_ "GenSigTimeoutTime" BU_SG_REL_ ICAS3_Gateway SG_ 2463978805 SmaLi_xPosCenter 5000;
BA_REL_ "GenSigTimeoutTime" BU_SG_REL_ ICAS3_Gateway SG_ 2463978805 SmaLi_xPosPassengerLeft 5000;
BA_REL_ "GenSigTimeoutTime" BU_SG_REL_ ICAS3_Gateway SG_ 2463978805 SmaLi_xPosPassengerRight 5000;
BA_REL_ "GenSigTimeoutTime" BU_SG_REL_ ICAS3_Gateway SG_ 2589283756 SOK_ungeschuetzte_Zeit 5000;
BA_REL_ "GenSigTimeoutTime" BU_SG_REL_ ICC_IO_Node SG_ 997 FT_Tuer_Status 1000;
BA_REL_ "GenSigTimeoutTime" BU_SG_REL_ ICC_IO_Node SG_ 997 TBF_FS_Touch_Event 1000;
BA_REL_ "GenSigTimeoutTime" BU_SG_REL_ ICC_IO_Node SG_ 1413 SI_BUS_01 5000;
BA_REL_ "GenSigTimeoutTime" BU_SG_REL_ ICC_IO_Node SG_ 1413 SI_BUS_02 5000;
BA_REL_ "GenSigTimeoutTime" BU_SG_REL_ ICC_IO_Node SG_ 1413 SI_BUS_03 5000;
BA_REL_ "GenSigTimeoutTime" BU_SG_REL_ ICC_IO_Node SG_ 1413 SI_BUS_04 5000;
BA_REL_ "GenSigTimeoutTime" BU_SG_REL_ ICC_IO_Node SG_ 1413 SI_BUS_05 5000;
BA_REL_ "GenSigTimeoutTime" BU_SG_REL_ ICC_IO_Node SG_ 1413 SI_BUS_06 5000;
BA_REL_ "GenSigTimeoutTime" BU_SG_REL_ ICC_IO_Node SG_ 1413 SI_BUS_07 5000;
BA_REL_ "GenSigTimeoutTime" BU_SG_REL_ ICC_IO_Node SG_ 1413 SI_BUS_08 5000;
BA_REL_ "GenSigTimeoutTime" BU_SG_REL_ ICC_IO_Node SG_ 1413 SI_BUS_09 5000;
BA_REL_ "GenSigTimeoutTime" BU_SG_REL_ ICC_IO_Node SG_ 1413 SI_BUS_10 5000;
BA_REL_ "GenSigTimeoutTime" BU_SG_REL_ ICC_IO_Node SG_ 1413 SI_BUS_11 5000;
BA_REL_ "GenSigTimeoutTime" BU_SG_REL_ ICC_IO_Node SG_ 1413 SI_BUS_12 5000;
BA_REL_ "GenSigTimeoutTime" BU_SG_REL_ ICC_IO_Node SG_ 1413 SI_BUS_13 5000;
BA_REL_ "GenSigTimeoutTime" BU_SG_REL_ ICC_IO_Node SG_ 1413 SI_BUS_14 5000;
BA_REL_ "GenSigTimeoutTime" BU_SG_REL_ ICC_IO_Node SG_ 1413 SI_BUS_15 5000;
BA_REL_ "GenSigTimeoutTime" BU_SG_REL_ ICC_IO_Node SG_ 1413 SI_Bus_Identifikation 5000;
BA_REL_ "GenSigTimeoutTime" BU_SG_REL_ ICC_IO_Node SG_ 1413 SI_CAB_V15 5000;
BA_REL_ "GenSigTimeoutTime" BU_SG_REL_ ICC_IO_Node SG_ 1413 SI_NWDF 5000;
BA_REL_ "GenSigTimeoutTime" BU_SG_REL_ ICC_IO_Node SG_ 1413 SI_NWDF_gueltig 5000;
BA_REL_ "GenSigTimeoutTime" BU_SG_REL_ ICC_IO_Node SG_ 1413 SI_P_Mode 5000;
BA_REL_ "GenSigTimeoutTime" BU_SG_REL_ ICC_IO_Node SG_ 1413 SI_P_Mode_gueltig 5000;
BA_REL_ "GenSigTimeoutTime" BU_SG_REL_ ICC_IO_Node SG_ 1413 SI_QRS_Mode 5000;
BA_REL_ "GenSigTimeoutTime" BU_SG_REL_ ICC_IO_Node SG_ 1413 SI_T_Mode 5000;
BA_REL_ "GenSigTimeoutTime" BU_SG_REL_ ICC_IO_Node SG_ 1413 SI_T_Schutz 5000;
BA_REL_ "GenSigTimeoutTime" BU_SG_REL_ ICC_IO_Node SG_ 2589283756 SOK_ungeschuetzte_Zeit 5000;
BA_REL_ "GenSigTimeoutTime" BU_SG_REL_ Kombi SG_ 619 TA_Spurwechsel 1000;
BA_REL_ "GenSigTimeoutTime" BU_SG_REL_ Kombi SG_ 619 TA_Status 1000;
BA_REL_ "GenSigTimeoutTime" BU_SG_REL_ Kombi SG_ 619 TA_Texte 1000;
BA_REL_ "GenSigTimeoutTime" BU_SG_REL_ Kombi SG_ 619 TA_Texte_02 1000;
BA_REL_ "GenSigTimeoutTime" BU_SG_REL_ Kombi SG_ 976 FT_Kisi_Fehler 1000;
BA_REL_ "GenSigTimeoutTime" BU_SG_REL_ Kombi SG_ 976 FT_Tuerschloss_defekt 1000;
BA_REL_ "GenSigTimeoutTime" BU_SG_REL_ Kombi SG_ 977 BT_Tuerschloss_defekt 1000;
BA_REL_ "GenSigTimeoutTime" BU_SG_REL_ Kombi SG_ 980 LRH_On_Off 5000;
BA_REL_ "GenSigTimeoutTime" BU_SG_REL_ Kombi SG_ 997 FT_Tuer_Status 1000;
BA_REL_ "GenSigTimeoutTime" BU_SG_REL_ Kombi SG_ 997 FT_kisi_asynchron 1000;
BA_REL_ "GenSigTimeoutTime" BU_SG_REL_ Kombi SG_ 1001 Thermo_Verbrauch_BTL 1000;
BA_REL_ "GenSigTimeoutTime" BU_SG_REL_ Kombi SG_ 1001 Thermo_Verbrauch_BTL_Ueberlauf 1000;
BA_REL_ "GenSigTimeoutTime" BU_SG_REL_ Kombi SG_ 1001 Thermo_Verbrauch_Innen 1000;
BA_REL_ "GenSigTimeoutTime" BU_SG_REL_ Kombi SG_ 1001 Thermo_Verbrauch_Innen_Ueberlauf 1000;
BA_REL_ "GenSigTimeoutTime" BU_SG_REL_ Kombi SG_ 1413 SI_BUS_01 5000;
BA_REL_ "GenSigTimeoutTime" BU_SG_REL_ Kombi SG_ 1413 SI_BUS_02 5000;
BA_REL_ "GenSigTimeoutTime" BU_SG_REL_ Kombi SG_ 1413 SI_BUS_03 5000;
BA_REL_ "GenSigTimeoutTime" BU_SG_REL_ Kombi SG_ 1413 SI_BUS_04 5000;
BA_REL_ "GenSigTimeoutTime" BU_SG_REL_ Kombi SG_ 1413 SI_BUS_05 5000;
BA_REL_ "GenSigTimeoutTime" BU_SG_REL_ Kombi SG_ 1413 SI_BUS_06 5000;
BA_REL_ "GenSigTimeoutTime" BU_SG_REL_ Kombi SG_ 1413 SI_BUS_13 5000;
BA_REL_ "GenSigTimeoutTime" BU_SG_REL_ Kombi SG_ 1413 SI_BUS_14 5000;
BA_REL_ "GenSigTimeoutTime" BU_SG_REL_ Kombi SG_ 1413 SI_BUS_15 5000;
BA_REL_ "GenSigTimeoutTime" BU_SG_REL_ Kombi SG_ 1413 SI_Bus_Identifikation 5000;
BA_REL_ "GenSigTimeoutTime" BU_SG_REL_ Kombi SG_ 1413 SI_NWDF 5000;
BA_REL_ "GenSigTimeoutTime" BU_SG_REL_ Kombi SG_ 1413 SI_NWDF_gueltig 5000;
BA_REL_ "GenSigTimeoutTime" BU_SG_REL_ Kombi SG_ 1413 SI_P_Mode 5000;
BA_REL_ "GenSigTimeoutTime" BU_SG_REL_ Kombi SG_ 1413 SI_P_Mode_gueltig 5000;
BA_REL_ "GenSigTimeoutTime" BU_SG_REL_ Kombi SG_ 1413 SI_QRS_Mode 5000;
BA_REL_ "GenSigTimeoutTime" BU_SG_REL_ Kombi SG_ 1413 SI_T_Mode 5000;
BA_REL_ "GenSigTimeoutTime" BU_SG_REL_ Kombi SG_ 1413 SI_T_Schutz 5000;
BA_REL_ "GenSigTimeoutTime" BU_SG_REL_ Kombi SG_ 1447 eCall_Funktionsstatus 5000;
BA_REL_ "GenSigTimeoutTime" BU_SG_REL_ Kombi SG_ 1447 eCall_Funktionsstatus_02 5000;
BA_REL_ "GenSigTimeoutTime" BU_SG_REL_ Kombi SG_ 2589283756 SOK_ungeschuetzte_Zeit 5000;
BA_REL_ "GenSigTimeoutTime" BU_SG_REL_ SmartLight_01 SG_ 1413 SI_NWDF 5000;
BA_REL_ "GenSigTimeoutTime" BU_SG_REL_ SmartLight_01 SG_ 1413 SI_NWDF_gueltig 5000;
BA_REL_ "GenSigTimeoutTime" BU_SG_REL_ SmartLight_01 SG_ 1413 SI_P_Mode 5000;
BA_REL_ "GenSigTimeoutTime" BU_SG_REL_ SmartLight_01 SG_ 1413 SI_P_Mode_gueltig 5000;
BA_REL_ "GenSigTimeoutTime" BU_SG_REL_ SmartLight_01 SG_ 1413 SI_QRS_Mode 5000;
BA_REL_ "GenSigTimeoutTime" BU_SG_REL_ SmartLight_01 SG_ 1413 SI_T_Mode 5000;
BA_REL_ "GenSigTimeoutTime" BU_SG_REL_ SmartLight_01 SG_ 1413 SI_T_Schutz 5000;
BA_REL_ "GenSigTimeoutTime" BU_SG_REL_ SmartLight_01 SG_ 2589283750 KBI_Aussen_Temp_gef 5000;
BA_REL_ "GenSigTimeoutTime" BU_SG_REL_ SmartLight_01 SG_ 2589283750 KBI_QBit_Aussen_Temp_gef 5000;
BA_REL_ "GenSigTimeoutTime" BU_SG_REL_ ZR_MIB_TOP_ab_Gen3 SG_ 976 FT_Kisi_li_aktiv 1000;
BA_REL_ "GenSigTimeoutTime" BU_SG_REL_ ZR_MIB_TOP_ab_Gen3 SG_ 976 FT_Kisi_re_aktiv 1000;
BA_REL_ "GenSigTimeoutTime" BU_SG_REL_ ZR_MIB_TOP_ab_Gen3 SG_ 976 FT_Tuer_geoeffnet 1000;
BA_REL_ "GenSigTimeoutTime" BU_SG_REL_ ZR_MIB_TOP_ab_Gen3 SG_ 977 BT_Tuer_geoeffnet 1000;
BA_REL_ "GenSigTimeoutTime" BU_SG_REL_ ZR_MIB_TOP_ab_Gen3 SG_ 997 FT_Tuer_Status 1000;
BA_REL_ "GenSigTimeoutTime" BU_SG_REL_ ZR_MIB_TOP_ab_Gen3 SG_ 1413 SI_BUS_01 5000;
BA_REL_ "GenSigTimeoutTime" BU_SG_REL_ ZR_MIB_TOP_ab_Gen3 SG_ 1413 SI_BUS_02 5000;
BA_REL_ "GenSigTimeoutTime" BU_SG_REL_ ZR_MIB_TOP_ab_Gen3 SG_ 1413 SI_BUS_03 5000;
BA_REL_ "GenSigTimeoutTime" BU_SG_REL_ ZR_MIB_TOP_ab_Gen3 SG_ 1413 SI_BUS_04 5000;
BA_REL_ "GenSigTimeoutTime" BU_SG_REL_ ZR_MIB_TOP_ab_Gen3 SG_ 1413 SI_BUS_05 5000;
BA_REL_ "GenSigTimeoutTime" BU_SG_REL_ ZR_MIB_TOP_ab_Gen3 SG_ 1413 SI_BUS_06 5000;
BA_REL_ "GenSigTimeoutTime" BU_SG_REL_ ZR_MIB_TOP_ab_Gen3 SG_ 1413 SI_BUS_07 5000;
BA_REL_ "GenSigTimeoutTime" BU_SG_REL_ ZR_MIB_TOP_ab_Gen3 SG_ 1413 SI_BUS_08 5000;
BA_REL_ "GenSigTimeoutTime" BU_SG_REL_ ZR_MIB_TOP_ab_Gen3 SG_ 1413 SI_BUS_09 5000;
BA_REL_ "GenSigTimeoutTime" BU_SG_REL_ ZR_MIB_TOP_ab_Gen3 SG_ 1413 SI_BUS_10 5000;
BA_REL_ "GenSigTimeoutTime" BU_SG_REL_ ZR_MIB_TOP_ab_Gen3 SG_ 1413 SI_BUS_11 5000;
BA_REL_ "GenSigTimeoutTime" BU_SG_REL_ ZR_MIB_TOP_ab_Gen3 SG_ 1413 SI_BUS_12 5000;
BA_REL_ "GenSigTimeoutTime" BU_SG_REL_ ZR_MIB_TOP_ab_Gen3 SG_ 1413 SI_BUS_13 5000;
BA_REL_ "GenSigTimeoutTime" BU_SG_REL_ ZR_MIB_TOP_ab_Gen3 SG_ 1413 SI_BUS_14 5000;
BA_REL_ "GenSigTimeoutTime" BU_SG_REL_ ZR_MIB_TOP_ab_Gen3 SG_ 1413 SI_BUS_15 5000;
BA_REL_ "GenSigTimeoutTime" BU_SG_REL_ ZR_MIB_TOP_ab_Gen3 SG_ 1413 SI_Bus_Identifikation 5000;
BA_REL_ "GenSigTimeoutTime" BU_SG_REL_ ZR_MIB_TOP_ab_Gen3 SG_ 1413 SI_Diagnose_Aktiv 5000;
BA_REL_ "GenSigTimeoutTime" BU_SG_REL_ ZR_MIB_TOP_ab_Gen3 SG_ 1413 SI_NWDF 5000;
BA_REL_ "GenSigTimeoutTime" BU_SG_REL_ ZR_MIB_TOP_ab_Gen3 SG_ 1413 SI_NWDF_gueltig 5000;
BA_REL_ "GenSigTimeoutTime" BU_SG_REL_ ZR_MIB_TOP_ab_Gen3 SG_ 1413 SI_P_Mode 5000;
BA_REL_ "GenSigTimeoutTime" BU_SG_REL_ ZR_MIB_TOP_ab_Gen3 SG_ 1413 SI_P_Mode_gueltig 5000;
BA_REL_ "GenSigTimeoutTime" BU_SG_REL_ ZR_MIB_TOP_ab_Gen3 SG_ 1413 SI_QRS_Mode 5000;
BA_REL_ "GenSigTimeoutTime" BU_SG_REL_ ZR_MIB_TOP_ab_Gen3 SG_ 1413 SI_Sammel_SG_Fehler 5000;
BA_REL_ "GenSigTimeoutTime" BU_SG_REL_ ZR_MIB_TOP_ab_Gen3 SG_ 1413 SI_Sammelfehler 5000;
BA_REL_ "GenSigTimeoutTime" BU_SG_REL_ ZR_MIB_TOP_ab_Gen3 SG_ 1413 SI_T_Mode 5000;
BA_REL_ "GenSigTimeoutTime" BU_SG_REL_ ZR_MIB_TOP_ab_Gen3 SG_ 1413 SI_T_Schutz 5000;
BA_REL_ "GenSigTimeoutTime" BU_SG_REL_ ZR_MIB_TOP_ab_Gen3 SG_ 2589283750 KBI_Aussen_Temp_gef 5000;
BA_REL_ "GenSigTimeoutTime" BU_SG_REL_ ZR_MIB_TOP_ab_Gen3 SG_ 2589283750 KBI_QBit_Aussen_Temp_gef 5000;
BA_REL_ "GenSigTimeoutTime" BU_SG_REL_ ZR_MIB_TOP_ab_Gen3 SG_ 2589283756 SOK_ungeschuetzte_Zeit 5000;
VAL_ 2463978804 SmaLi_CtrlCmd_01 0 "Ignore" 4 "ReqConfig" 8 "SetBrightness" 12 "ReqSlot" 16 "SetMovieBundleVersion" 20 "ValidateChecksum" 76 "StartRealTimeSequence" 80 "EndRealTimeSequence" 132 "BeginMovie" 136 "BeginMoviePersistent" 140 "LoopStart" 144 "LoopEnd" 146 "ExtroStart" 148 "EndMovie" 150 "ExtroEnd" 156 "EndMoviePersistent" 196 "PlayMovie" 200 "DeleteMovie" 204 "StopMovie" 208 "DeleteAll" 210 "ExtroMovie" 212 "DeactivateMovie" 216 "ActivateMovie" 220 "ActivateAllMovies" ;
VAL_ 2463978800 SmaLi_FrameCmd_01 0 "Ignore" 68 "Frame" 72 "MovieFrame" ;
VAL_ 2463978801 SmaLi_FrameCmd_02 0 "Ignore" 68 "Frame" 72 "MovieFrame" ;
VAL_ 2463978802 SmaLi_FrameCmd_03 0 "Ignore" 68 "Frame" 72 "MovieFrame" ;
VAL_ 2463978803 SmaLi_FrameCmd_04 0 "Ignore" 68 "Frame" 72 "MovieFrame" ;
VAL_ 2463978806 SmaLi_FrameCmd_05 0 "Ignore" 68 "Frame" 72 "MovieFrame" ;
VAL_ 2463978805 SmaLi_CtrlCmdRsp_01 0 "Ignore" 1 "IgnoreRsp" 5 "Config" 10 "SetBrightnessErr" 13 "SlotRsp" 14 "SlotRspErr" 21 "ChecksumValid" 22 "ChecksumInvalid" 23 "ChecksumValidationErr" 37 "Ready" 69 "FrameErr" 73 "MovieFrameErr" 77 "RealTimeSequenceFinished" 78 "StartRealTimeSeqErr" 131 "MovieDefinitionErr" 138 "BeginMoviePersistErr" 149 "MovieSaved" 154 "EndMoviePersistentErr" 197 "PlayMovieFinished" 198 "PlayMovieErr" 199 "MovieRunning" 202 "DeleteMovieErr" 206 "StopMovieErr" 209 "DeleteAllFinished" 210 "DeleteAllErr" 211 "ExtroMovieErr" 214 "DeactivateMovieErr" 218 "ActivateMovieErr" 255 "GeneralError" ;
VAL_ 2463978805 SmaLi_error_cause 0 "kein_Fehler" 64 "Fehler_in_Anfrage" 65 "Kommando_nicht_definiert" 67 "LED_ausserhalb_des_Bereichs" 68 "Farbe_ausserhalb_des_Bereichs" 69 "Buffer_Overflow" 70 "ungueltiger_Counter" 71 "Nicht_bereit" 72 "Anzeige_deaktiviert" 73 "Timeout" 128 "Komm_kann_nicht_ausgef_werden" 129 "Kommando_nicht_implementiert" 130 "Ein_Film_laeuft_gerade" 131 "Movie_nicht_verfuegbar" 132 "Film_zu_lang" 133 "Slot_belegt" 134 "MovieID_existiert_bereits" 135 "Slot_nicht_vorhanden" 136 "Movie_Protokollfehler" 137 "Slot_leer" 138 "Movie_nicht_in_Slot" 139 "Brightness_zu_gross" 140 "Brightness_zu_klein" 141 "MovieID_existiert_nicht" 142 "Movie_deaktiviert" 143 "Interner_Film_gestartet" 144 "Diagnose_gestartet" 145 "Speichervorgang_laeuft" 146 "Loeschvorgang_laeuft" 147 "Neuer_Film_gestartet" 148 "Frame_nicht_komplett_empfangen" 150 "Speicher_belegt" 151 "Referenzpruefsumme_fehlt" 152 "Pruefsumme_fehlerhaft" 153 "Funktion_deaktiviert" 255 "Fehler_unbekannt" ;
VAL_ 980 BH_Blinker_Fehler 0 "kein_Fehler" 1 "Fehler" ;
VAL_ 980 BH_Blinker_li 0 "nicht_betaetigt" 1 "Blinkerhebel_Pos_li_betaetigt" ;
VAL_ 980 BH_Blinker_re 0 "nicht_betaetigt" 1 "Blinkerhebel_Pos_re_betaetigt" ;
VAL_ 980 BH_Fernlicht 0 "nicht_betaetigt" 1 "Blinkerhebel_in_Richtung_Fernlicht_betaetigt" ;
VAL_ 980 BH_Lichthupe 0 "nicht_betaetigt" 1 "Blinkerhebel in Richtung Lichthupe betaetigt" ;
VAL_ 980 FAS_Taster 0 "nicht_betaetigt" 1 "betaetigt" ;
VAL_ 980 FAS_Taster_Fehler 0 "kein_Fehler" 1 "Fehler" ;
VAL_ 980 LRH_aktiv 0 "inaktiv" 1 "aktiv" ;
VAL_ 980 LRH_On_Off 0 "LRH_aus__keine Anzeige" 1 "LRH_aus" 2 "LRH_ein" 3 "Fehler" ;
VAL_ 980 LSS_Tastencode 0 "Key_Released__No_Key" 4 "Up" 5 "Down" 7 "OK__ThumbWheel_Button" ;
VAL_ 980 SMLS_Hupe 0 "nicht_betaetigt" 1 "Hupe_gedrueckt" ;
VAL_ 980 SMLS_P_verriegelt 0 "Init" 1 "nicht_verriegelt" 2 "verriegelt" 3 "Fehler" ;
VAL_ 980 SMLS_P_verriegelt_plausibel 0 "unplausibel" 1 "plausibel" ;
VAL_ 980 SMLS_PTT 0 "nicht_betaetigt" 1 "PTT_gedrueckt" ;
VAL_ 980 WH_Frontwaschen 0 "aus" 1 "Wischerhebel in Stellung Wisch Wasch vorne" ;
VAL_ 980 WH_Heckintervall 0 "nicht_betaetigt" 1 "Wischerhebel in Stellung Heckintervall" ;
VAL_ 980 WH_Heckwaschen 0 "nicht_betaetigt" 1 "Wischerhebel in Stellung Wisch Wasch hinten" ;
VAL_ 980 WH_Intervall 0 "aus" 1 "Wischerhebel in Stellung Intervall" ;
VAL_ 980 WH_Intervallstufen 0 "Init / Default" 1 "Intervallstufe 1" 5 "Intervallstufe 2" 9 "Intervallstufe 3" 13 "Intervallstufe 4" 15 "Fehler" ;
VAL_ 980 WH_SRA 0 "SRA_Aus" 1 "SRA_Ein" ;
VAL_ 980 WH_Tipwischen 0 "nicht_betaetigt" 1 "betaetigt" ;
VAL_ 980 WH_Tipwischen_lang 0 "nicht_betaetigt" 1 "betaetigt" ;
VAL_ 980 WH_Wischer_Fehler 0 "kein_Fehler" 1 "Fehler" ;
VAL_ 980 WH_WischerStufe1 0 "aus" 1 "Wischerhebel in Stufe Wischen 1" ;
VAL_ 980 WH_WischerStufe2 0 "aus" 1 "Wischerhebel in Stufe Wischen 2" ;
VAL_ 2589283756 SOK_ungeschuetzte_Zeit 0 "Init" ;
VAL_ 2527679739 STK_Anf_AussenspiegelHZ 0 "nicht_angefordert" 1 "angefordert" ;
VAL_ 2527679739 STK_Berechnungsphase 0 "keine_Berechnungsphase" 1 "Berechnungsphase_erforderlich" 2 "Init" 3 "Fehler" ;
VAL_ 2527679739 STK_ErwVK_Anf 0 "nicht_angefordert" 1 "angefordert" ;
VAL_ 2527679739 STK_ErwVK_Beifahrerzone 0 "nicht_angefordert" 1 "Beifahrerzone_angefordert" ;
VAL_ 2527679739 STK_ErwVK_Fahrerzone 0 "nicht_angefordert" 1 "Fahrerzone_angefordert" ;
VAL_ 2527679739 STK_ErwVK_Heckzone2_links 0 "nicht_angefordert" 1 "Heckzone2_links_angefordert" ;
VAL_ 2527679739 STK_ErwVK_Heckzone2_rechts 0 "nicht_angefordert" 1 "Heckzone2_rechts_angefordert" ;
VAL_ 2527679739 STK_ErwVK_Heckzone_links 0 "nicht_angefordert" 1 "Heckzone_links_angefordert" ;
VAL_ 2527679739 STK_ErwVK_Heckzone_rechts 0 "nicht_angefordert" 1 "Heckzone_rechts_angefordert" ;
VAL_ 2527679739 STK_ErwVK_Modus 0 "nicht_angefordert" 1 "Fahrerzone" 2 "Beifahrerzone" 3 "Heckzone_links" 4 "Heckzone_rechts" 5 "Scheibenheizung" ;
VAL_ 2527679739 STK_ErwVK_Scheibenheizung 0 "nicht_angefordert" 1 "Scheibenheizung_angefordert" ;
VAL_ 2527679739 STK_FSH_Anf 0 "keine_Anforderung" 1 "Frontscheibenheizung_Anf" ;
VAL_ 2527679739 STK_GesamtEnergiebedarf 254 "Init" 255 "Fehler" ;
VAL_ 2527679739 STK_HSH_Anf 0 "keine_Anforderung" 1 "Heckscheibenheizung_Anf" ;
VAL_ 2527679739 STK_Klima_Temp 29 "VW_high_30C" 30 "Init" 31 "Fehler" ;
VAL_ 2527679739 STK_KurzVK_Anf 0 "nicht_angefordert" 1 "angefordert" ;
VAL_ 2527679739 STK_MaxLeistung 254 "Init" 255 "Fehler" ;
VAL_ 2527679739 STK_Standklima_Anf 0 "nicht_angefordert" 1 "angefordert" ;
VAL_ 2527679739 STK_Standklima_Timer_Status 0 "Standklimatimer_nicht_aktiv" 1 "Standklimatimer_aktiv" ;
VAL_ 2527679739 STK_Stecker_Status 0 "kein_Stecker_erkannt" 1 "AC_Stecker_erkannt" 2 "DC_Stecker_erkannt" ;
VAL_ 2527679739 STK_VK_Modus 0 "keine_Vorkonditionierung" 1 "Sofort_Konditionierung" 2 "zeitversetzte_Konditionierung" 3 "Fehler" ;
VAL_ 2527679739 STK_VK_STH_Einsatz 0 "Verbrennerstandheizung verbieten" 1 "Automatik (Verbrennerstandheizung erlauben)" 2 "Verbrennerstandheizung erzwingen" 3 "reserviert" 4 "reserviert" 5 "reserviert" 6 "Init" 7 "Fehler" ;
VAL_ 2527679739 STK_VK_Timer_Status 0 "nicht_aktiv" 1 "aktiv" 2 "Sofortstart_aktiv" ;
VAL_ 2527679739 STK_Voko_LED 0 "Aus" 1 "Ein" ;
VAL_ 1413 GW_KD_Fehler 0 "kein_KD_Fehler" 1 "KD_Fehler" ;
VAL_ 1413 SI_BUS_01 0 "keine_Busruhe" 1 "Busruhe" ;
VAL_ 1413 SI_BUS_02 0 "keine_Busruhe" 1 "Busruhe" ;
VAL_ 1413 SI_BUS_03 0 "keine_Busruhe" 1 "Busruhe" ;
VAL_ 1413 SI_BUS_04 0 "keine_Busruhe" 1 "Busruhe" ;
VAL_ 1413 SI_BUS_05 0 "keine_Busruhe" 1 "Busruhe" ;
VAL_ 1413 SI_BUS_06 0 "keine_Busruhe" 1 "Busruhe" ;
VAL_ 1413 SI_BUS_07 0 "keine_Busruhe" 1 "Busruhe" ;
VAL_ 1413 SI_BUS_08 0 "keine_Busruhe" 1 "Busruhe" ;
VAL_ 1413 SI_BUS_09 0 "keine_Busruhe" 1 "Busruhe" ;
VAL_ 1413 SI_BUS_10 0 "keine_Busruhe" 1 "Busruhe" ;
VAL_ 1413 SI_BUS_11 0 "keine_Busruhe" 1 "Busruhe" ;
VAL_ 1413 SI_BUS_12 0 "keine_Busruhe" 1 "Busruhe" ;
VAL_ 1413 SI_BUS_13 0 "keine_Busruhe" 1 "Busruhe" ;
VAL_ 1413 SI_BUS_14 0 "keine_Busruhe" 1 "Busruhe" ;
VAL_ 1413 SI_BUS_15 0 "keine_Busruhe" 1 "Busruhe" ;
VAL_ 1413 SI_Bus_Identifikation 16 "CAN_Diagnose" 17 "CAN_Antrieb" 18 "CAN_Komfort" 19 "CAN_Infotainment" 20 "CAN_Fahrwerk" 21 "CAN_Extended" 22 "CAN_Hybrid" 23 "CAN_Lade" 24 "CAN_Kombi" 25 "CAN_Komfort_2" 26 "CAN_AFS" 27 "CAN_MIB" 33 "CAN_FahrerAssistenzSysteme" 34 "CAN_Migration" 35 "CAN_Connect" 36 "CAN_AnzeigeBedienung" 37 "CAN_ElectricalVehicle" 40 "CAN_Telematik" 41 "CAN_MFL" 42 "CAN_FahrerAssistenzSysteme_2" 47 "CAN_Komfort_3" 48 "FlexRay_A" 49 "FlexRay_B" 97 "VLAN_FAS" 98 "VLAN_Infotainment" 99 "VLAN_Connect" 100 "VLAN_Komfort" 101 "VLAN_Antrieb" 102 "VLAN_Diagnose" 103 "VLAN_Internet" 104 "VLAN_Gateway" 105 "VLAN_Remote_FC" 106 "VLAN_Connect_2" 107 "VLAN_Licht" 108 "VLAN_Charge" 109 "VLAN_Cockpit" 176 "HCP1_CANFD01" 177 "HCP1_CANFD02" 178 "HCP1_CANFD03" 179 "HCP1_CANFD04" 180 "HCP1_CANFD05" 181 "HCP1_CANFD06" 182 "HCP1_CANFD07" 183 "HCP1_CANFD08" 186 "HCP4_CANFD03" 187 "HCP4_CANFD04" 188 "HCP1_CANFD09" 189 "HCP4_CANFD06" 190 "HCP4_CANFD07" 191 "HCP4_CANFD08" 192 "HCP4_CANFD09" 193 "HCP4_CANFD10" 194 "HCP1_CANFD10" 195 "ICAS1_CANFD2_HCP5_CANFD02" 196 "HCP1_CANFD11" 197 "WU_HCP1_CANFD" 199 "WU_HCP2_CANFD" 200 "WU_HCP3_CANFD" 201 "WU_HCP4_CANFD" 202 "HCP3_CANFD02" 204 "ESC_CANFD" 205 "HCP4_CANFD11" 206 "HCP4_CANFD12" 207 "HCP5_CANFD04" 208 "HCP5_CANFD05" 212 "WU_ConMod_CANFD" 213 "WU_PASD_CANFD" 215 "CAN_MobileDeviceKey" ;
VAL_ 1413 SI_CAB_V15 0 "Init" 1 "CAB_01_Antrieb" 2 "CAB_02_Hybrid_Laden" 4 "CAB_03_Fahrwerk" 8 "CAB_04_Fahrerassistenz" 16 "CAB_05_Komfort" 32 "CAB_06_Anzeige" 64 "CAB_07_Connect" 128 "CAB_08_MIB" 256 "CAB_09_Standheizung" 512 "CAB_10_MDK" 1024 "CAB_11_VLAN_Fahrerassistenz" 4096 "CAB_13_VLAN_Connect" 8192 "CAB_14_VLAN_Infotainment" 16384 "CAB_15_Laden" 32768 "CAB_16_Licht" 65536 "CAB_17_RTM" ;
VAL_ 1413 SI_Diagnose_Aktiv 0 "inaktiv" 1 "aktiv" ;
VAL_ 1413 SI_NWDF 0 "Ueberwachung_nicht_freigegeben" 1 "Ueberwachung_freigegeben" ;
VAL_ 1413 SI_NWDF_gueltig 0 "NWDF_wird_nicht_unterstuetzt" 1 "NWDF_wird_unterstuetzt" ;
VAL_ 1413 SI_P_Mode 0 "inaktiv" 1 "aktiv" ;
VAL_ 1413 SI_P_Mode_gueltig 0 "dezentraler_Produktionsmode" 1 "zentraler_Produktionsmode" ;
VAL_ 1413 SI_QRS_Mode 0 "QRS_Messmodus_nicht_aktiv" 1 "QRS_Messmodus_aktiv" ;
VAL_ 1413 SI_Sammel_SG_Fehler 61 "Reserviert" 62 "Overflow" 63 "ungueltig" ;
VAL_ 1413 SI_Sammelfehler 0 "kein_Sammelfehler" 1 "Sammelfehler" ;
VAL_ 1413 SI_T_Mode 0 "Transportmodus_nicht_aktiv" 1 "Transportmodus_aktiv" ;
VAL_ 1413 SI_T_Schutz 0 "Transportschutz_nicht_aktiv" 1 "Transportschutz_aktiv" ;
VAL_ 2589283775 NM_aktiv_Buskopplung 0 "nicht_aktiv" 1 "aktiv" ;
VAL_ 2589283775 NM_aktiv_CAB 0 "nicht_aktiv" 1 "aktiv" ;
VAL_ 2589283775 NM_aktiv_CWU 0 "nicht_aktiv" 1 "aktiv" ;
VAL_ 2589283775 NM_Req_CMS 0 "inaktiv" 1 "Nachlauf_aktiv" ;
VAL_ 2589283775 NM_Req_DCP_01 0 "inaktiv" 1 "Nachlauf_aktiv" ;
VAL_ 2589283775 NM_Req_DCP_02 0 "inaktiv" 1 "Nachlauf_aktiv" ;
VAL_ 2589283775 NM_Req_DIM 0 "inaktiv" 1 "Nachlauf_aktiv" ;
VAL_ 2589283775 NM_Req_ECM 0 "inaktiv" 1 "Nachlauf_aktiv" ;
VAL_ 2589283775 NM_Req_EMHLR 0 "inaktiv" 1 "Nachlauf_aktiv" ;
VAL_ 2589283775 NM_Req_EOC 0 "Inaktiv" 1 "Nachlauf_Aktiv" ;
VAL_ 2589283775 NM_Req_FoD 0 "Inaktiv" 1 "Nachlauf_aufgrund_FoD" ;
VAL_ 2589283775 NM_Req_HVEM 0 "Inaktiv" 1 "Nachlauf_aufgrund_HVEM" ;
VAL_ 2589283775 NM_Req_IAA_PSO 0 "Inaktiv" 1 "Nachlauf_aufgrund_IAA_PSO" ;
VAL_ 2589283775 NM_Req_internal 0 "inaktiv" 1 "Nachlauf_aktiv" ;
VAL_ 2589283775 NM_Req_Kessy 0 "Inaktiv" 1 "Nachlauf_aufgrund_KY" ;
VAL_ 2589283775 NM_Req_KLS 0 "Inaktiv" 1 "Nachlauf_aufgrund_KLS" ;
VAL_ 2589283775 NM_Req_KS 0 "Inaktiv" 1 "Nachlauf_aufgrund_KS" ;
VAL_ 2589283775 NM_Req_PaCo 0 "Inaktiv" 1 "Nachlauf_aufgrund_PaCo" ;
VAL_ 2589283775 NM_Req_RTM 0 "inaktiv" 1 "Nachlauf_aktiv" ;
VAL_ 2589283775 NM_Req_SAL 0 "Inaktiv" 1 "Nachlauf_aufgrund_SAL" ;
VAL_ 2589283775 NM_Req_STK 0 "inaktiv" 1 "Nachlauf_aktiv" ;
VAL_ 2589283775 NM_Req_SWC1 0 "inaktiv" 1 "Nachlauf_aktiv" ;
VAL_ 2589283775 NM_Req_SWC2 0 "inaktiv" 1 "Nachlauf_aktiv" ;
VAL_ 2589283775 NM_Req_USS 0 "Inaktiv" 1 "Nachlauf_aufgrund_USS" ;
VAL_ 2589283775 NM_Req_ZM 0 "Inaktiv" 1 "Nachlauf_aufgrund_ZM" ;
VAL_ 2589283775 NM_Req_ZV 0 "inaktiv" 1 "Nachlauf_aktiv" ;
VAL_ 2589283775 Powerstate_Act 0 "Init" 1 "KL30_to_FullOperation" 2 "Reset_to_FullOperation" 5 "Parking_to_FullOperation" 7 "FullOperation_to_ChargingMin" 9 "FullOperation_to_Parking" 13 "ChargingMin_to_FullOperation" 15 "Parking_to_TransportMode" 17 "Transport_to_Parking" 21 "ParkingMin_to_Parking" ;
VAL_ 2589283947 NM_Reason_CMS 0 "Inaktiv" ;
VAL_ 2589283947 NM_Reason_DCP_1 0 "Inaktiv" ;
VAL_ 2589283947 NM_Reason_DCP_2 0 "Inaktiv" ;
VAL_ 2589283947 NM_Reason_DIM 0 "Inaktiv" ;
VAL_ 2589283947 NM_Reason_ECM 0 "Inaktiv" ;
VAL_ 2589283947 NM_Reason_EMHLR 0 "Inaktiv" ;
VAL_ 2589283947 NM_Reason_EOC 0 "Inaktiv" ;
VAL_ 2589283947 NM_Reason_FoD 0 "Inaktiv" ;
VAL_ 2589283947 NM_Reason_HVEM 0 "Inaktiv" ;
VAL_ 2589283947 NM_Reason_IAA_PSO 0 "Inaktiv" ;
VAL_ 2589283947 NM_Reason_ICAS1_internal 0 "Inaktiv" ;
VAL_ 2589283947 NM_Reason_Kessy 0 "Inaktiv" ;
VAL_ 2589283947 NM_Reason_KLS 0 "Inaktiv" ;
VAL_ 2589283947 NM_Reason_KS 0 "Inaktiv" ;
VAL_ 2589283947 NM_Reason_PaCo 0 "Inaktiv" ;
VAL_ 2589283947 NM_Reason_RTM 0 "Inaktiv" ;
VAL_ 2589283947 NM_Reason_SAL 0 "Inaktiv" ;
VAL_ 2589283947 NM_Reason_STK 0 "Inaktiv" ;
VAL_ 2589283947 NM_Reason_SWC1 0 "Inaktiv" ;
VAL_ 2589283947 NM_Reason_SWC2 0 "Inaktiv" ;
VAL_ 2589283947 NM_Reason_USS 0 "Inaktiv" ;
VAL_ 2589283947 NM_Reason_ZM 0 "Inaktiv" ;
VAL_ 2589283947 NM_Reason_ZV 0 "Inaktiv" ;
VAL_ 2589283947 Powerstate_Prev_01 0 "Init" 1 "KL30_to_FullOperation" 2 "Reset_to_FullOperation" 5 "Parking_to_FullOperation" 7 "FullOperation_to_ChargingMin" 9 "FullOperation_to_Parking" 13 "ChargingMin_to_FullOperation" 15 "Parking_to_TransportMode" 17 "Transport_to_Parking" 21 "ParkingMin_to_Parking" ;
VAL_ 2589283947 Powerstate_Prev_02 0 "Init" 1 "KL30_to_FullOperation" 2 "Reset_to_FullOperation" 5 "Parking_to_FullOperation" 7 "FullOperation_to_ChargingMin" 9 "FullOperation_to_Parking" 13 "ChargingMin_to_FullOperation" 15 "Parking_to_TransportMode" 17 "Transport_to_Parking" 21 "ParkingMin_to_Parking" ;
VAL_ 619 TA_ACC_Sollstatus 0 "Init" 1 "ACC_aktivieren" 2 "ACC_deaktivieren" ;
VAL_ 619 TA_aktiv_HMI 0 "nicht_aktiv" 1 "TA_Low_aktiv" 2 "TA_High_aktiv" ;
VAL_ 619 TA_Fehler 0 "kein_Fehler" 1 "Fehler_TA_Low" 2 "Fehler_TA_Low_keine_Sensorsicht" 3 "Fehler_TA_High" 4 "Fehler_TA_High_keine_Sensorsicht" ;
VAL_ 619 TA_FoD_Status 0 "Init" 1 "kein_TA_verbaut" 2 "TA_Low_verbaut" 3 "TA_Low_und_TA_High_verbaut" ;
VAL_ 619 TA_Handsoff_LED 0 "keine_Anzeige" 1 "weiss" 2 "rot" 3 "reserviert" ;
VAL_ 619 TA_Spurwechsel 0 "Kein_Spurwechsel" 1 "Spurwechsel_links" 2 "Spurwechsel_rechts" 3 "Spurwechselfreigabe_links" 4 "Spurwechselfreigabe_rechts" 5 "TA_Modus_StandBy" 6 "Spurwechselfreigabe_li_und_re" ;
VAL_ 619 TA_Spurwechsel_Ready 0 "nicht_moeglich" 1 "links_moeglich" 2 "rechts_moeglich" 3 "links_rechts_moeglich" ;
VAL_ 619 TA_Status 0 "Keine_Anzeige" 1 "Passiv" 2 "Aktiv" 3 "Warnung" ;
VAL_ 619 TA_Texte 0 "Keine_Anzeige" 1 "Nicht_verfuegbar" 2 "Modus_TA_m_ass_Spurwechsel_gewae" 3 "Modus_ACC_ausgewaehlt" 4 "Modus_TravelAssist_ausgewaehlt" 5 "Spurwechsel_nicht_verfuegbar" 6 "Spurwechsel_abgebrochen" 7 "Spurw_abgebr_Lenkung_uebernehmen" ;
VAL_ 619 TA_Texte_02 0 "Keine_Anzeige" 1 "TA_zur_Zeit_nicht_aktivierbar" 2 "Zurzeit_nur_Spurfuehrung_verfueg" 3 "Fahreruebernahme_stumm" 4 "Fahreruebernahme_leise" 5 "Systemgrenzenwarnung" 6 "Fehler_TA_Low_keine_Sensorsicht" 7 "Fehler_TA_High_keine_Sensorsicht" 8 "Reserved_08" 9 "Reserved_09" 10 "Reserved_10" 11 "Reserved_11" 12 "Reserved_12" 13 "Reserved_13" 14 "Reserved_14" 15 "Reserved_15" ;
VAL_ 619 TA_Ueberholhilfe 0 "Init" 1 "keine_Ueberholhilfe" 2 "ACC_Ueberholhilfe" 3 "TA_FSW_Ueberholhilfe" ;
VAL_ 1637 TF_BT_ConnectionState 0 "keine_Verbindung" 1 "Verbindung" ;
VAL_ 1637 TF_Mute_Msg_Code 0 "Phonecall" 1 "Speech Recognition active" 2 "Emergency Call" 3 "beep-signal" 4 "Operator Call" 5 "Ring" 6 "Phonecall wideband" 7 "Stereo Audio (source mobile)" ;
VAL_ 1637 TF_Telephone_State 0 "idle" 1 "not_active" 2 "Call_active" 3 "eCall_active" 4 "not_available" 5 "reserved" 6 "reserved" 7 "reserved" ;
VAL_ 2589283750 KBI_Aussen_Temp_gef 253 "nicht verbaut" 254 "Init" 255 "Fehler" ;
VAL_ 2589283750 KBI_QBit_Aussen_Temp_gef 0 "gueltiger_Wert" 1 "Ersatz_Init_oder_Fehlerwert" ;
VAL_ 1001 Thermo_Pred_P_dyn_Innen 2046 "Init" 2047 "Fehler" ;
VAL_ 1001 Thermo_Pred_P_stat_Innen 2046 "Init" 2047 "Fehler" ;
VAL_ 1001 Thermo_Pred_T_dyn_Innen 254 "Init" 255 "Fehler" ;
VAL_ 1001 Thermo_Verbrauch_BTL_Ueberlauf 0 "kein_Ueberlauf" 1 "Ueberlauf" ;
VAL_ 1001 Thermo_Verbrauch_Innen_Ueberlauf 0 "kein_Ueberlauf" 1 "Ueberlauf" ;
VAL_ 1447 bCall_active 0 "bcall_inactive" 1 "bcall_active" ;
VAL_ 1447 eCall_Funktionsstatus 0 "kein_Fehler" 1 "Fkt_eingeschraenkt" 2 "Fkt_eingeschraenkt_service" 3 "Fkt_nicht_verfuegbar" 4 "Fkt_Service" 5 "Fkt_deaktiviert" 6 "Fkt_aktiviert" 7 "init" ;
VAL_ 1447 eCall_Funktionsstatus_02 0 "kein_Fehler" 1 "Manueller_Notruf_aktiv" 2 "Automatischer_Notruf_aktiv" 7 "Init" ;
VAL_ 1447 iCall_active 0 "inaktiv" 1 "aktiv" ;
VAL_ 1447 MOD_Energie_Anf 0 "Keine_Anforderung" 1 "Anforderung_NV" 2 "Anforderung_HV_Nutzung_Erlaubt" 3 "Fehler" ;
VAL_ 1447 OCU_Privacymode_Locationdata 0 "Init" 1 "locationdata_freigabe" 2 "locationdata_gesperrt" ;
VAL_ 1447 OCU_Privacymode_Status 0 "Init" 1 "Privacymode_not_active" 2 "Privacymode_active" ;
VAL_ 1447 TM_Door_Lock 0 "Init" 1 "door_lock" ;
VAL_ 1447 TM_Door_Unlock 0 "Init" 1 "door_unlock" ;
VAL_ 1447 TM_Nur_Hupen 0 "inaktiv" 1 "aktiv" ;
VAL_ 1447 TM_Panik_Alarm 0 "Init" 1 "panik_alarm_on" ;
VAL_ 1447 TM_Spiegel_Anklappen 0 "Init" 1 "Spiegel_anklappen" ;
VAL_ 1447 TM_Warnblinken 0 "Init" 1 "Warnblinken_on" ;
VAL_ 1447 TM_ZV_Signatur 0 "Init" ;
VAL_ 977 ASW_Warnung_aktiv_BFS 0 "nicht_angefordert" 1 "angefordert" ;
VAL_ 977 BFS_Status_eTAG 0 "Init" 1 "Griff_ausgefahren" 2 "Griff_eingefahren" 3 "Fehler" ;
VAL_ 977 BT_ASW_HMI_defekt 0 "ASW_kein_Fehler" 1 "ASW_Fehler" ;
VAL_ 977 BT_FH_Bew_hoch 0 "Init" 1 "FH_ist_in_Bewegung_hoch" ;
VAL_ 977 BT_FH_Bew_tief 0 "Init" 1 "FH_ist_in_Bewegung_tief" ;
VAL_ 977 BT_FH_Block 0 "Init" 1 "Fensterheber_Block" ;
VAL_ 977 BT_FH_Fang 0 "ausserhalb_Fangbereich" 1 "innerhalb_Fangbereich" ;
VAL_ 977 BT_FH_normiert 0 "Init" 1 "Fenster_normiert" ;
VAL_ 977 BT_FH_Pos_oben 1 "Scheibe oben (nach Absenken auf Position) " ;
VAL_ 977 BT_FH_S_AutoHoch 0 "Init" 1 "FH_Schalter_auto_hoch_gedrueckt" ;
VAL_ 977 BT_FH_S_AutoTief 0 "Init" 1 "FH_Schalter_auto_tief_gedrueckt" ;
VAL_ 977 BT_FH_S_ManHoch 0 "Init" 1 "FH_Schalter_man_hoch_gedrueckt" ;
VAL_ 977 BT_FH_S_ManTief 0 "Init" 1 "FH_Schalter_man_tief_gedrueckt" ;
VAL_ 977 BT_FH_Thermo 0 "Init" 1 "Thermoschutz_aktiv" ;
VAL_ 977 BT_gesafet 0 "Init" 1 "gesafet" ;
VAL_ 977 BT_Kisi_Fehler 0 "kein_Fehler" 1 "Fehler" ;
VAL_ 977 BT_Lock_Taster 0 "Init" 1 "Lock_Taster_betaetigt" ;
VAL_ 977 BT_Lock_Taster_inv 0 "Lock Taster betï?½tigt" 1 "Lock Taster nicht betï?½tigt" ;
VAL_ 977 BT_Lock_Unlock_Taster 0 "nicht_betaetigt" 1 "betaetigt" ;
VAL_ 977 BT_Oben_Block_erw 0 "Fensterheber_nicht_in_Blockerwar" 1 "Fensterheber_in_Blockerwartung_o" ;
VAL_ 977 BT_Schliesstaster 1 "betaetigt" ;
VAL_ 977 BT_Schluesselschalter_auf 0 "Init" 1 "Schluesselschalter_auf_betaetigt" ;
VAL_ 977 BT_Schluesselschalter_zu 0 "Init" 1 "Schluesselschalter_zu_betaetigt" ;
VAL_ 977 BT_Schluesselschalter_zu_inv 0 "Schlï?½sselschalter betï?½tigt" 1 "Schlï?½sselschalter nicht betï?½tigt" ;
VAL_ 977 BT_SP_ausgerastet 0 "Init" 1 "Spiegel_ausgerastet" ;
VAL_ 977 BT_Sp_Blk_def 0 "iO" 1 "Spiegel_Blinker_defekt" ;
VAL_ 977 BT_SP_Heizung_aktiv 1 "BF Spiegelheizung ein" ;
VAL_ 977 BT_SP_Heizung_Status 0 "Init" 1 "Status_Spiegelheizung_ein" ;
VAL_ 977 BT_SP_ht_aktiv 0 "Init" 1 "Spiegel_yAchse_aktiv" ;
VAL_ 977 BT_SP_lr_aktiv 0 "Init" 1 "Spiegel_xAchse_aktiv" ;
VAL_ 977 BT_Sperrklinke 0 "Schloss_in_Vorraste_und_Hauptraste" 1 "Tuer_auf_oder_Tuer_Position_zwischen_Vor_und_Hauptraste" ;
VAL_ 977 BT_SWA_HMI_defekt 0 "SWA_kein_Fehler" 1 "SWA_Fehler" ;
VAL_ 977 BT_TAG_betaetigt 0 "Init" 1 "Tuerinnengriff_betaetigt" ;
VAL_ 977 BT_TCR_Mode_aktiv 0 "TCR_Mode_deaktiv" 1 "TCR_Mode_aktiv" ;
VAL_ 977 BT_TIG_betaetigt 0 "Init" 1 "Tuerinnengriff_betaetigt" ;
VAL_ 977 BT_TSG_hinten_verbaut 0 "nicht verbaut" 1 "verbaut" ;
VAL_ 977 BT_Tuer_geoeffnet 0 "geschlossen" 1 "offen" ;
VAL_ 977 BT_Tuer_Status 0 "Init" 1 "Tuer_geschlossen" 2 "Tuer_offen" 3 "Fehler" ;
VAL_ 977 BT_Tuer_Status_QBit 0 "Status_Tuerkontakt_sicher" 1 "Status_Tuerkontakt_unsicher" ;
VAL_ 977 BT_Tueroeffnen_Warnung 0 "Tuerwarnung_nicht_aktiv" 1 "Tuerwarnung_aktiv" ;
VAL_ 977 BT_Tuerschloss_defekt 0 "Tuerschloss_funktionsfaehig" 1 "Tuerschloss_defekt" ;
VAL_ 977 BT_UEKB_aktiviert 0 "Init" 1 "aktiv" ;
VAL_ 977 BT_Unlock_Taster 0 "Init" 1 "Unlock_Taster_betaetigt" ;
VAL_ 977 BT_Unten_Block_erw 0 "Fensterheber_nicht_in_Blockerwar" 1 "Fensterheber_in_Blockerwartung_u" ;
VAL_ 977 BT_verriegelt 0 "Init" 1 "verriegelt" ;
VAL_ 977 BT_Zuziehhilfe_aktiv 0 "Init" 1 "Zuziehhilfe_aktiv" ;
VAL_ 976 ASW_HMI_defekt 0 "iO" 1 "defekt" ;
VAL_ 976 ASW_wakeup 0 "Sleep" 1 "Wakeup" ;
VAL_ 976 ASW_Warnung_aktiv_FS 0 "nicht_angefordert" 1 "angefordert" ;
VAL_ 976 FS_Status_eTAG 0 "Init" 1 "Griff_ausgefahren" 2 "Griff_eingefahren" 3 "Fehler" ;
VAL_ 976 FT_BFS_Fond_Freigabe 0 "Init" 1 "Freigabe_fuer_Fondbedienung_BFS" ;
VAL_ 976 FT_Daemmglas 0 "Normalglas_verbaut" 1 "Daemmglas_verbaut" ;
VAL_ 976 FT_FH_Bew_hoch 0 "Init" 1 "FH_in_Bewegung_hoch" ;
VAL_ 976 FT_FH_Bew_tief 0 "Init" 1 "FH_in_Bewegung_tief" ;
VAL_ 976 FT_FH_Block 0 "Init" 1 "Fenster_Block" ;
VAL_ 976 FT_FH_Fang 0 "ausserhalb_Fangbereich" 1 "innerhalb_Fangbereich" ;
VAL_ 976 FT_FH_normiert 0 "Init" 1 "Fenster_normiert" ;
VAL_ 976 FT_FH_Pos_oben 1 "Scheibe oben (nach Absenken auf Position) " ;
VAL_ 976 FT_FH_S_AutoHoch 0 "Init" 1 "FH_Schalter_auto_hoch_betaetigt" ;
VAL_ 976 FT_FH_S_AutoTief 0 "Init" 1 "FH_Schalter_auto_tief_betaetigt" ;
VAL_ 976 FT_FH_S_ManHoch 0 "Init" 1 "FH_Schalter_man_hoch_betaetigt" ;
VAL_ 976 FT_FH_S_ManTief 0 "Init" 1 "FH_Schalter_man_tief_betaetigt" ;
VAL_ 976 FT_FH_Thermo 0 "Init" 1 "Thermoschutz_aktiv" ;
VAL_ 976 FT_gesafet 0 "Init" 1 "gesafet" ;
VAL_ 976 FT_HD_Taste 0 "nicht_betaetigt" 1 "Heckdeckeltaste_betaetigt" ;
VAL_ 976 FT_HD_Taste_2 0 "Taste_nicht_gedrueckt" 1 "Taste_gedrueckt" ;
VAL_ 976 FT_IRUE_Taste 0 "Init" 1 "IRUE_Taste_betaetigt" ;
VAL_ 976 FT_Kisi_Fehler 0 "kein_Fehler" 1 "Fehler" ;
VAL_ 976 FT_Kisi_li_aktiv 0 "inaktiv" 1 "aktiv" ;
VAL_ 976 FT_Kisi_re_aktiv 0 "inaktiv" 1 "aktiv" ;
VAL_ 976 FT_Kisi_Taster_li 0 "nicht_betaetigt" 1 "betaetigt" ;
VAL_ 976 FT_Kisi_Taster_re 0 "nicht_betaetigt" 1 "betaetigt" ;
VAL_ 976 FT_Lock_Taster 0 "Init" 1 "Lock_Taster_betaetigt" ;
VAL_ 976 FT_Lock_Unlock_Taster 0 "nicht_betaetigt" 1 "betaetigt" ;
VAL_ 976 FT_Oben_Block_erw 0 "Fensterheber_nicht_in_Blockerwar" 1 "Fensterheber_in_Blockerwartung_o" ;
VAL_ 976 FT_Schliesstaster 1 "Schliesstaster_betaetigt" ;
VAL_ 976 FT_Schluesselschalter_auf 0 "Init" 1 "Schluesselschalter_auf_betaetigt" ;
VAL_ 976 FT_Schluesselschalter_zu 1 "Schluesselschalter zu betaetigt" ;
VAL_ 976 FT_SP_ausgerastet 0 "Init" 1 "Spiegel_ausgerastet" ;
VAL_ 976 FT_Sp_Blk_def 0 "iO" 1 "defekt" ;
VAL_ 976 FT_SP_Heizung_Status 0 "Init" 1 "Status_Spiegelheizung_ein" ;
VAL_ 976 FT_SP_ht_aktiv 0 "Init" 1 "Spiegel_yAchse_aktiv" ;
VAL_ 976 FT_SP_lr_aktiv 0 "Init" 1 "Spiegel_xAchse_aktiv" ;
VAL_ 976 FT_Sperrklinke 0 "Schloss_in_Vorraste_und_Hauptraste" 1 "Tuer_auf_oder_Tuer_Position_zwischen_Vor_und_Hauptraste" ;
VAL_ 976 FT_SWA_Taster 0 "Taster_nicht_betaetigt" 1 "Taster_betaetigt" ;
VAL_ 976 FT_TAG_betaetigt 0 "nicht_betaetigt" 1 "betaetigt" ;
VAL_ 976 FT_TD_Taste 0 "Init" 1 "Tankdeckel_Taster_betaetigt" ;
VAL_ 976 FT_TD_Taste_Fehler 0 "iO" 1 "defekt" ;
VAL_ 976 FT_TIG_betaetigt 0 "nicht_betaetigt" 1 "betaetigt" ;
VAL_ 976 FT_TSG_hinten_verbaut 0 "nicht verbaut" 1 "verbaut" ;
VAL_ 976 FT_Tuer_geoeffnet 0 "geschlossen" 1 "Tuer_offen" ;
VAL_ 976 FT_Tuerschloss_defekt 0 "Tuerschloss_funktionsfaehig" 1 "Tuerschloss_defekt" ;
VAL_ 976 FT_UEKB_aktiviert 0 "Init" 1 "UEKB_aktiv" ;
VAL_ 976 FT_Unlock_Taster 0 "Init" 1 "Unlock_Taster_betaetigt" ;
VAL_ 976 FT_Unten_Block_erw 0 "Fensterheber_nicht_in_Blockerwar" 1 "Fensterheber_in_Blockerwartung_u" ;
VAL_ 976 FT_verriegelt 0 "Init" 1 "verriegelt" ;
VAL_ 976 FT_Zuziehhilfe_aktiv 0 "Init" 1 "Zuziehilfe_aktiv" ;
VAL_ 976 SSR_Temp_Freigabe 0 "SSR_Deaktiviert" 1 "SSR_Freigegeben" ;
VAL_ 976 SWA_HMI_Diagnose 0 "kein_Fehler_erkannt" 1 "Fehler_Taster_erkannt" 2 "Fehler_LED_erkannt" 3 "Fehler_LED_und_Taster_erkannt" ;
VAL_ 997 FT_BFS_Tuer_Status 0 "Init" 1 "Tuer_geschlossen" 2 "Tuer_offen" 3 "Fehler" ;
VAL_ 997 FT_Cargolock_bet 0 "nicht_betaetigt" 1 "betaetigt" ;
VAL_ 997 FT_HBFS_Tuer_Status 0 "Init" 1 "Tuer_geschlossen" 2 "Tuer_offen" 3 "Fehler" ;
VAL_ 997 FT_HFS_Tuer_Status 0 "Init" 1 "Tuer_geschlossen" 2 "Tuer_offen" 3 "Fehler" ;
VAL_ 997 FT_kisi_asynchron 0 "nicht_aktiv" 1 "aktiv" ;
VAL_ 997 FT_KiSi_Status_Soll_HBFS 0 "inaktiv" 1 "aktiv" ;
VAL_ 997 FT_KiSi_Status_Soll_HFS 0 "inaktiv" 1 "aktiv" ;
VAL_ 997 FT_Kisi_Taster_li_02 0 "nicht_betaetigt" 1 "betaetigt" ;
VAL_ 997 FT_Kisi_Taster_re_02 0 "nicht_betaetigt" 1 "betaetigt" ;
VAL_ 997 FT_Lock_Taster_02 0 "nicht_betaetigt" 1 "betaetigt" ;
VAL_ 997 FT_Schluesselschalter_zu_02 0 "nicht_betaetigt" 1 "betaetigt" ;
VAL_ 997 FT_SP_Heizung_ein 0 "Aus" 1 "Ein" ;
VAL_ 997 FT_TCR_Mode_aktiv 0 "TCR_Mode_deaktiv" 1 "TCR_Mode_aktiv" ;
VAL_ 997 FT_TD_Taste_Status 0 "kein_Fehler" 1 "Kurzschluss_nach_Minus" 2 "Kurzschluss_nach_Plus" 3 "Leitungsunterbrechung" ;
VAL_ 997 FT_Tuer_Status 0 "Init" 1 "Tuer_geschlossen" 2 "Tuer_offen" 3 "Fehler" ;
VAL_ 997 FT_Tuer_Status_QBit 0 "Status_Tuerkontakt_sicher" 1 "Status_Tuerkontakt_unsicher" ;
VAL_ 997 FT_Tueroeffnen_Warnung 0 "Tuerwarnung_nicht_aktiv" 1 "Tuerwarnung_aktiv" ;
VAL_ 997 TBF_FS_Touch_Event 0 "nicht_betaetigt" 1 "Tippen" 2 "Wischen" 3 "Geste" 4 "Doppeltippen" 5 "Longpress_1" 6 "Longpress_2" 7 "reserviert" 8 "reserviert" 9 "reserviert" 10 "reserviert" 11 "reserviert" 12 "reserviert" 13 "reserviert" 14 "reserviert" 15 "reserviert" ;
VAL_ 997 TSG_FS_Spiegel_angeklappt 0 "Spiegel_ausgeklappt" 1 "Spiegel_eingeklappt" ;
